VERSION ""

NS_ :

BS_:

BU_: APIM_CISM APIM ESPM DSP FCIMB RACM_RCIM HUD_ADV WCM TRM_ITRM ACM GWM _delete IPC GENERIC TSTR

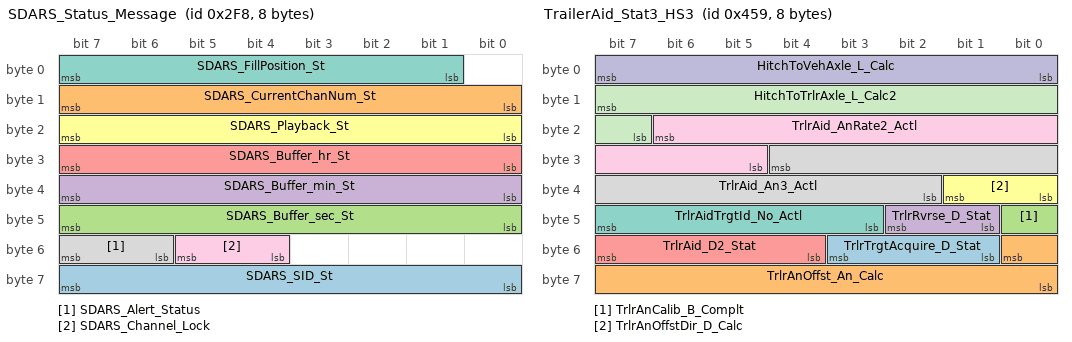
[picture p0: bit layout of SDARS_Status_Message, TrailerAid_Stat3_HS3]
BO_ 760 SDARS_Status_Message: 8 ACM
 SG_ SDARS_SID_St : 63|8@0+ (1,0) [0|255] "unitless"  APIM,RACM_RCIM
 SG_ SDARS_CurrentChanNum_St : 15|8@0+ (1,0) [0|255] "unitless"  APIM,RACM_RCIM,IPC
 SG_ SDARS_Buffer_sec_St : 47|8@0+ (1,0) [0|255] "unitless"  APIM,IPC
 SG_ SDARS_Buffer_min_St : 39|8@0+ (1,0) [0|255] "unitless"  APIM,IPC
 SG_ SDARS_Buffer_hr_St : 31|8@0+ (1,0) [0|255] "unitless"  APIM,IPC
 SG_ SDARS_Playback_St : 23|8@0+ (1,0) [0|255] "unitless"  APIM,IPC
 SG_ SDARS_FillPosition_St : 7|7@0+ (1,0) [0|127] "unitless"  APIM,IPC
 SG_ SDARS_Alert_Status : 55|2@0+ (1,0) [0|3] "SED"  APIM,IPC
 SG_ SDARS_Channel_Lock : 53|2@0+ (1,0) [0|3] "SED"  APIM,RACM_RCIM,IPC

BO_ 705 SDARS_RDISP_WORD_Tx: 8 ACM
 SG_ SDARS_RDISP_WORD_Tx : 7|64@0+ (1,0) [0|1.84467440737096E+019] "unitless"  APIM

BO_ 1113 TrailerAid_Stat3_HS3: 8 GWM
 SG_ TrlrTrgtAcquire_D_Stat : 51|3@0+ (1,0) [0|7] "SED" Vector__XXX
 SG_ TrlrAnOffst_An_Calc : 48|9@0+ (0.1,0) [0|51.1] "degrees"  APIM,APIM_CISM,IPC
 SG_ TrlrAnCalib_B_Complt : 40|1@0+ (1,0) [0|1] "SED"  APIM,APIM_CISM,IPC
 SG_ TrlrRvrse_D_Stat : 42|2@0+ (1,0) [0|3] "SED" Vector__XXX
 SG_ TrlrAid_D2_Stat : 55|4@0+ (1,0) [0|15] "SED" Vector__XXX
 SG_ TrlrAnOffstDir_D_Calc : 33|2@0+ (1,0) [0|3] "SED"  APIM,APIM_CISM,IPC
 SG_ TrlrAidTrgtId_No_Actl : 47|5@0+ (1,0) [0|31] "unitless"  APIM,APIM_CISM,IPC
 SG_ TrlrAid_An3_Actl : 28|11@0+ (0.125,-90) [-90|165.75] "degrees" Vector__XXX
 SG_ TrlrAid_AnRate2_Actl : 22|10@0+ (0.125,-50) [-50|77.75] "degrees/sec" Vector__XXX
 SG_ HitchToVehAxle_L_Calc : 7|8@0+ (0.0127,-0.508) [-0.508|2.7178] "meter" Vector__XXX
 SG_ HitchToTrlrAxle_L_Calc2 : 15|9@0+ (0.0254,0) [0|12.9794] "meter" Vector__XXX

BO_ 1144 MHT_EV_Wakeup_HS3: 8 GWM
 SG_ AwdLckMde_D_Stat : 59|3@0+ (1,0) [0|7] "SED" Vector__XXX
 SG_ BattTracCool_B_Actl : 60|1@0+ (1,0) [0|1] "SED" Vector__XXX
 SG_ BattChrgInhbt_D2_Rq : 63|3@0+ (1,0) [0|7] "SED" Vector__XXX
 SG_ FstChrgCmplt_T_Est : 41|10@0+ (1,0) [0|1023] "minute"  APIM,APIM_CISM,IPC
 SG_ BattChrgTrgtSoC_D_Rq : 35|3@0+ (1,0) [0|7] "Percent"  APIM_CISM,IPC
 SG_ CabnEvapSovFront_B_Rq : 38|1@0+ (1,0) [0|1] "SED" Vector__XXX
 SG_ HeatCoreSovRear_B_Rq : 36|1@0+ (1,0) [0|1] "SED" Vector__XXX
 SG_ BattChlrSov_B_Rq : 39|1@0+ (1,0) [0|1] "SED" Vector__XXX
 SG_ CabnEvapSovRear_B_Rq : 37|1@0+ (1,0) [0|1] "SED" Vector__XXX
 SG_ BrkAppl_D_RqPt : 25|2@0+ (1,0) [0|3] "SED" Vector__XXX
 SG_ BattClntVlvOvrrd_D_Rq : 31|2@0+ (1,0) [0|3] "SED" Vector__XXX
 SG_ BattTracChillerOn_B_Rq : 27|1@0+ (1,0) [0|1] "SED" Vector__XXX
 SG_ BattTracChiller_D_Stat : 29|2@0+ (1,0) [0|3] "SED" Vector__XXX
 SG_ HtrnDcdcDis_B_Rq : 26|1@0+ (1,0) [0|1] "SED" Vector__XXX
 SG_ HtrnCnnctPwr_B_Stat : 16|1@0+ (1,0) [0|1] "SED" Vector__XXX
 SG_ PtcHtr_D_Stat : 18|2@0+ (1,0) [0|3] "SED" Vector__XXX
 SG_ WakeAlarm0_B_Typ : 21|1@0+ (1,0) [0|1] "SED" Vector__XXX
 SG_ WakeAlarm0_T_Rq : 7|15@0+ (1,0) [0|32767] "minute" Vector__XXX
 SG_ HtrnClntFlw_D_Rq : 20|2@0+ (1,0) [0|3] "SED" Vector__XXX
 SG_ BattTracDrvSustn_B_Rq : 8|1@0+ (1,0) [0|1] "SED" Vector__XXX
 SG_ CabinDrvSustn_B_Rq : 23|1@0+ (1,0) [0|1] "SED" Vector__XXX
 SG_ ChrgNowEvnt_B_Stat : 22|1@0+ (1,0) [0|1] "SED" Vector__XXX
 SG_ PreCondBatt_B_Actl : 32|1@0+ (1,0) [0|1] "SED" Vector__XXX
 SG_ BattTracClntVlv_B_Rq : 47|1@0+ (1,0) [0|1] "SED" Vector__XXX
 SG_ ULoBattTrnsfrSustn_B_Rq : 43|1@0+ (1,0) [0|1] "SED" Vector__XXX
 SG_ ULoBattTransfer_D_Stat : 46|3@0+ (1,0) [0|7] "SED" Vector__XXX
 SG_ BattTracClimtDis_B_Stat : 42|1@0+ (1,0) [0|1] "SED" Vector__XXX

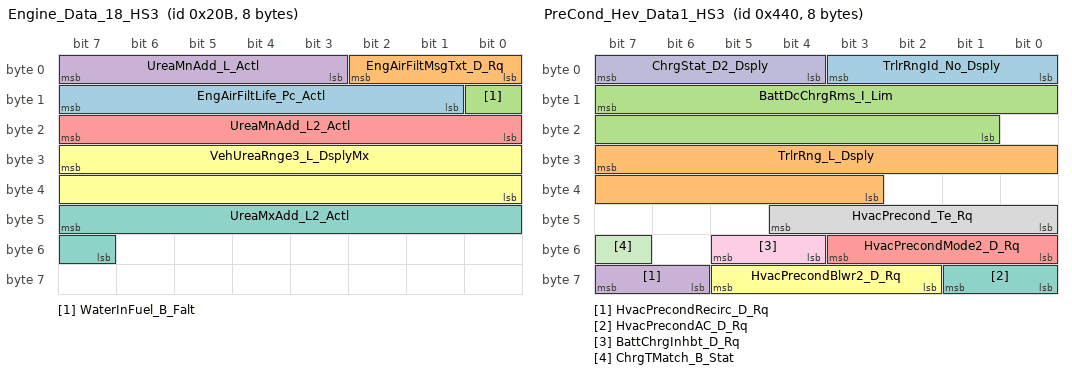
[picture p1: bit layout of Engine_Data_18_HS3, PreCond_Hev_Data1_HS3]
BO_ 523 Engine_Data_18_HS3: 8 GWM
 SG_ EngAirFiltLife_Pc_Actl : 15|7@0+ (1,0) [0|127] "percent"  IPC
 SG_ EngAirFiltMsgTxt_D_Rq : 2|3@0+ (1,0) [0|7] "SED"  IPC
 SG_ WaterInFuel_B_Falt : 8|1@0+ (1,0) [0|1] "SED"  APIM_CISM,IPC
 SG_ UreaMnAdd_L_Actl : 7|5@0+ (1,0) [0|31] "litre"  APIM_CISM,IPC
 SG_ UreaMnAdd_L2_Actl : 23|8@0+ (0.1,0) [0|25.4] "litre"  APIM_CISM,IPC
 SG_ VehUreaRnge3_L_DsplyMx : 31|16@0+ (1,0) [0|65535] "unitless"  APIM_CISM,IPC
 SG_ UreaMxAdd_L2_Actl : 47|9@0+ (0.1,0) [0|51] "litre"  APIM_CISM,IPC

BO_ 692 AUDIO_RDISP_WORD_Tx: 8 ACM
 SG_ AUDIO_RDISP_WORD_Tx : 7|64@0+ (1,0) [0|1.84467440737096E+019] "unitless"  APIM

BO_ 1837 TesterPhysicalResWCM: 8 WCM
 SG_ TesterPhysicalResWCM : 7|64@0+ (1,0) [0|1.84467E+019] "unitless"  TSTR

BO_ 942 ParkAid_Data2_HS3: 8 GWM
 SG_ ApaOffOptnSel_B_Avail : 51|1@0+ (1,0) [0|1] "SED"  APIM,APIM_CISM
 SG_ ApaSlotOption_B_Avail : 43|1@0+ (1,0) [0|1] "SED"  APIM,APIM_CISM
 SG_ ApaSlotAlrtSet_B_Stat : 44|1@0+ (1,0) [0|1] "SED"  APIM,APIM_CISM
 SG_ ApaSlotAlrt_B_Rq : 45|1@0+ (1,0) [0|1] "SED"  APIM,APIM_CISM
 SG_ ApaRmtFeatSel_B_Avail : 46|1@0+ (1,0) [0|1] "SED"  APIM,APIM_CISM
 SG_ ApaParkOutSel_B_Avail : 47|1@0+ (1,0) [0|1] "SED"  APIM,APIM_CISM
 SG_ ApaSys_D2_Stat : 35|4@0+ (1,0) [0|15] "SED"  APIM,APIM_CISM
 SG_ ApaSlotTrgt_D_Stat : 39|4@0+ (1,0) [0|15] "SED"  APIM,APIM_CISM
 SG_ ApaParkInSel_B_Avail : 24|1@0+ (1,0) [0|1] "SED"  APIM,APIM_CISM
 SG_ ApaMsgTxt_D2_Stat : 28|4@0+ (1,0) [0|15] "SED"  APIM,APIM_CISM
 SG_ ApaDynmcSlot_B_Stat : 29|1@0+ (1,0) [0|1] "SED"  APIM,APIM_CISM
 SG_ ApaDisplayMode_D_Stat : 31|2@0+ (1,0) [0|3] "SED"  APIM,APIM_CISM
 SG_ ApaControlMode_D_Stat : 16|1@0+ (1,0) [0|1] "SED"  APIM,APIM_CISM
 SG_ PrkBrkElRleas_B_RqApa : 50|1@0+ (1,0) [0|1] "SED" Vector__XXX
 SG_ PrkAidAcsyRear_D_Stat : 18|2@0+ (1,0) [0|3] "SED"  IPC
 SG_ PrkAidAcsyFront_D_Stat : 20|2@0+ (1,0) [0|3] "SED"  IPC
 SG_ ApaDrvRq2MsgTxt_D_Rq : 55|4@0+ (1,0) [0|15] "SED"  APIM,APIM_CISM
 SG_ ApaDrvRq1MsgTxt_D_Rq : 42|3@0+ (1,0) [0|7] "SED"  APIM,APIM_CISM
 SG_ PrkAidRdiusRight_L_Dsply : 15|8@0+ (1,0) [0|255] "unitless"  APIM,APIM_CISM
 SG_ PrkAidRdiusLeft_L_Dsply : 7|8@0+ (1,0) [0|255] "unitless"  APIM,APIM_CISM
 SG_ PrkAidDrvDir_D_Stat : 23|3@0+ (1,0) [0|7] "SED"  APIM,APIM_CISM

BO_ 1088 PreCond_Hev_Data1_HS3: 8 GWM
 SG_ TrlrRngId_No_Dsply : 3|4@0+ (1,0) [0|15] "unitless"  APIM,APIM_CISM
 SG_ TrlrRng_L_Dsply : 31|13@0+ (0.1,0) [0|818.9] "kilometer"  APIM,APIM_CISM
 SG_ BattDcChrgRms_I_Lim : 15|15@0+ (0.05,0) [0|1638.25] "ampere" Vector__XXX
 SG_ HvacPrecondRecirc_D_Rq : 63|2@0+ (1,0) [0|3] "SED"  GENERIC
 SG_ HvacPrecondMode2_D_Rq : 51|4@0+ (1,0) [0|15] "SED"  GENERIC
 SG_ HvacPrecondBlwr2_D_Rq : 61|4@0+ (1,0) [0|15] "SED"  GENERIC
 SG_ HvacPrecondAC_D_Rq : 57|2@0+ (1,0) [0|3] "SED"  GENERIC
 SG_ HvacPrecond_Te_Rq : 44|5@0+ (0.5,14.5) [14.5|30] "degC"  GENERIC
 SG_ BattChrgInhbt_D_Rq : 53|2@0+ (1,0) [0|3] "SED"  GENERIC
 SG_ ChrgStat_D2_Dsply : 7|4@0+ (1,0) [0|15] "SED"  APIM,APIM_CISM,IPC
 SG_ ChrgTMatch_B_Stat : 55|1@0+ (1,0) [0|1] "SED"  APIM_CISM,IPC

BO_ 706 SDARS_MC_WORD_Tx: 8 ACM
 SG_ SDARS_MC_WORD_Tx : 7|64@0+ (1,0) [0|1.84467440737096E+019] "unitless"  IPC

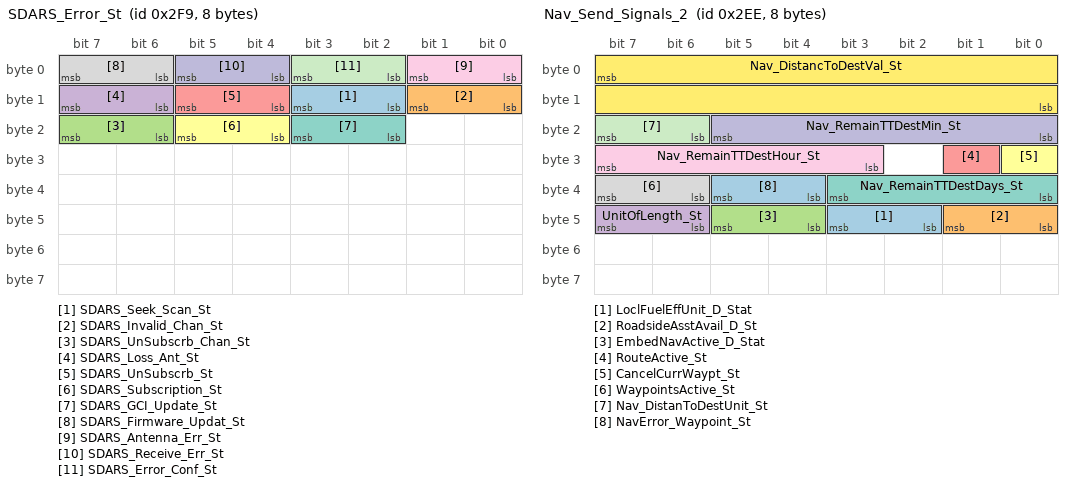
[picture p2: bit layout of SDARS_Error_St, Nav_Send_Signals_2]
BO_ 761 SDARS_Error_St: 8 ACM
 SG_ SDARS_Seek_Scan_St : 11|2@0+ (1,0) [0|3] "SED"  APIM,RACM_RCIM,IPC
 SG_ SDARS_Invalid_Chan_St : 9|2@0+ (1,0) [0|3] "SED"  APIM,RACM_RCIM,IPC
 SG_ SDARS_UnSubscrb_Chan_St : 23|2@0+ (1,0) [0|3] "SED"  APIM,RACM_RCIM,IPC
 SG_ SDARS_Loss_Ant_St : 15|2@0+ (1,0) [0|3] "SED"  APIM,RACM_RCIM,IPC
 SG_ SDARS_UnSubscrb_St : 13|2@0+ (1,0) [0|3] "SED"  APIM,RACM_RCIM,IPC
 SG_ SDARS_Subscription_St : 21|2@0+ (1,0) [0|3] "SED"  APIM,RACM_RCIM,IPC
 SG_ SDARS_GCI_Update_St : 19|2@0+ (1,0) [0|3] "SED"  APIM,RACM_RCIM,IPC
 SG_ SDARS_Firmware_Updat_St : 7|2@0+ (1,0) [0|3] "SED"  APIM,RACM_RCIM,IPC
 SG_ SDARS_Antenna_Err_St : 1|2@0+ (1,0) [0|3] "SED"  APIM,RACM_RCIM,IPC
 SG_ SDARS_Receive_Err_St : 5|2@0+ (1,0) [0|3] "SED"  APIM,RACM_RCIM,IPC
 SG_ SDARS_Error_Conf_St : 3|2@0+ (1,0) [0|3] "SED"  APIM,RACM_RCIM,IPC

BO_ 694 PHONE_MC_WORD_Tx: 8 APIM
 SG_ PHONE_MC_WORD_Tx : 7|64@0+ (1,0) [0|1.84467440737096E+019] "unitless"  IPC

BO_ 750 Nav_Send_Signals_2: 8 APIM
 SG_ LoclFuelEffUnit_D_Stat : 43|2@0+ (1,0) [0|3] "SED"  GWM,IPC
 SG_ RoadsideAsstAvail_D_St : 41|2@0+ (1,0) [0|3] "SED"  GWM,IPC
 SG_ EmbedNavActive_D_Stat : 45|2@0+ (1,0) [0|3] "SED"  GWM,IPC
 SG_ UnitOfLength_St : 47|2@0+ (1,0) [0|3] "SED"  GWM,IPC
 SG_ RouteActive_St : 25|1@0+ (1,0) [0|1] "SED"  GWM,HUD_ADV,IPC
 SG_ CancelCurrWaypt_St : 24|1@0+ (1,0) [0|1] "SED"  GWM,IPC
 SG_ Nav_RemainTTDestDays_St : 35|4@0+ (1,0) [0|14] "day"  GWM,HUD_ADV,IPC
 SG_ WaypointsActive_St : 39|2@0+ (1,0) [0|3] "SED"  GWM,IPC
 SG_ Nav_RemainTTDestHour_St : 31|5@0+ (1,0) [0|31] "hour"  GWM,HUD_ADV,IPC
 SG_ Nav_RemainTTDestMin_St : 21|6@0+ (1,0) [0|63] "minute"  GWM,HUD_ADV,IPC
 SG_ Nav_DistanToDestUnit_St : 23|2@0+ (1,0) [0|3] "SED"  GWM,HUD_ADV,IPC
 SG_ Nav_DistancToDestVal_St : 7|16@0+ (1,0) [0|65534] "unitless"  GWM,HUD_ADV,IPC
 SG_ NavError_Waypoint_St : 37|2@0+ (1,0) [0|3] "SED"  GWM,HUD_ADV,IPC

BO_ 704 NAV_MC_WORD_Tx: 8 APIM
 SG_ NAV_MC_WORD_Tx : 7|64@0+ (1,0) [0|1.84467440737096E+019] "unitless"  IPC

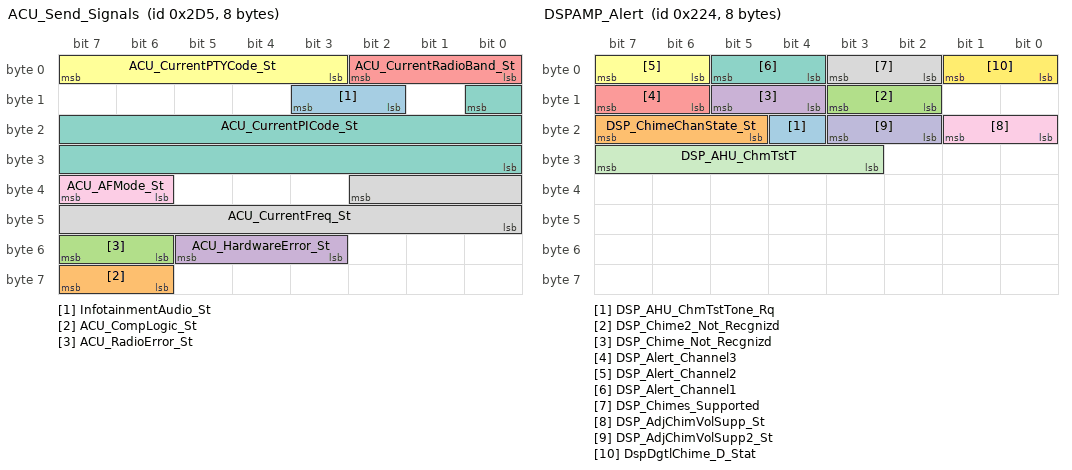
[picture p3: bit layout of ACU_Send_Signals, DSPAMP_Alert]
BO_ 725 ACU_Send_Signals: 8 APIM
 SG_ InfotainmentAudio_St : 11|2@0+ (1,0) [0|3] "SED"  APIM,DSP
 SG_ ACU_CompLogic_St : 63|2@0+ (1,0) [0|3] "SED"  GWM,GENERIC
 SG_ ACU_RadioError_St : 55|2@0+ (1,0) [0|3] "SED"  APIM,RACM_RCIM,GWM,IPC
 SG_ ACU_HardwareError_St : 53|3@0+ (1,0) [0|7] "SED"  APIM,RACM_RCIM,GWM,IPC
 SG_ ACU_CurrentRadioBand_St : 2|3@0+ (1,0) [0|7] "SED"  GWM,IPC
 SG_ ACU_CurrentPTYCode_St : 7|5@0+ (1,0) [0|31] "unitless"  APIM,RACM_RCIM,GWM,IPC
 SG_ ACU_CurrentPICode_St : 8|17@0+ (1,0) [0|65535] "unitless"  APIM,RACM_RCIM,GWM
 SG_ ACU_CurrentFreq_St : 34|11@0+ (1,0) [0|1557] "unitless"  APIM,DSP,RACM_RCIM,GWM,WCM,IPC
 SG_ ACU_AFMode_St : 39|2@0+ (1,0) [0|3] "SED"  APIM,GWM

BO_ 1049 APIMSDMsignals: 8 APIM
 SG_ DcacZone3PwBttn_B_Stat : 34|1@0+ (1,0) [0|1] "SED"  GWM
 SG_ DcacZone2PwBttn_B_Stat : 35|1@0+ (1,0) [0|1] "SED"  GWM
 SG_ DcacPwResetBtn2_B_Stat : 36|1@0+ (1,0) [0|1] "SED"  GWM
 SG_ DcacPwOffButtn2_B_Stat : 37|1@0+ (1,0) [0|1] "SED"  GWM
 SG_ DcacPwHiButtn2_B_Stat : 38|1@0+ (1,0) [0|1] "SED"  GWM
 SG_ DcacGfciTestBtn2_B_Stat : 39|1@0+ (1,0) [0|1] "SED"  GWM
 SG_ DcacAllZoneBttn_B_Stat : 16|1@0+ (1,0) [0|1] "SED"  GWM
 SG_ DcacChime_D_Rq : 18|2@0+ (1,0) [0|3] "SED"  GWM,IPC
 SG_ PersTurnSglView_D_RqMnu : 20|2@0+ (1,0) [0|3] "SED"  GWM
 SG_ TrailCtlSwtch_B_Stat4 : 21|1@0+ (1,0) [0|1] "SED"  GWM
 SG_ RearDiffLck_D_RqDrv3 : 9|2@0+ (1,0) [0|3] "SED"  GWM
 SG_ FrontDiffLck_D_RqDrv3 : 11|2@0+ (1,0) [0|3] "SED"  GWM
 SG_ CamraFrnt_B_RqMnu : 12|1@0+ (1,0) [0|1] "SED"  GWM
 SG_ TurnAsstSwtch_D_Stat : 14|2@0+ (1,0) [0|3] "SED"  GWM
 SG_ StabBarCnncButtn_D_Sta3 : 23|2@0+ (1,0) [0|3] "SED"  GWM
 SG_ TrlrRngId_No_RqReset : 27|4@0+ (1,0) [0|15] "unitless"  GWM
 SG_ TrlrId_No_ActlMnu : 31|4@0+ (1,0) [0|15] "unitless"  GWM
 SG_ SelDrvMdeTxtRst_B_Rq2 : 15|1@0+ (1,0) [0|1] "SED"  GWM
 SG_ SelDrvMdePage_B_Stat : 0|1@0+ (1,0) [0|1] "SED"  GWM
 SG_ SelDrvMdeCnfm_D_Stat2 : 2|2@0+ (1,0) [0|3] "SED"  GWM
 SG_ SelDrvMde_D_RqDrv : 7|5@0+ (1,0) [0|31] "SED"  GWM

BO_ 1014 WCM_Send_Signals: 8 WCM
 SG_ WrlssAcsyChrgr_D_Stat : 7|3@0+ (1,0) [0|7] "SED"  APIM,APIM_CISM
 SG_ WrlssAcsyChrg_Pc_Actl : 15|7@0+ (1,0) [0|125] "percent"  APIM,APIM_CISM

BO_ 548 DSPAMP_Alert: 8 DSP
 SG_ DSP_AHU_ChmTstTone_Rq : 20|1@0+ (1,0) [0|1] "SED"  APIM_CISM,ACM
 SG_ DSP_ChimeChanState_St : 23|3@0+ (1,0) [0|7] "SED"  APIM_CISM,ACM
 SG_ DSP_Chime2_Not_Recgnizd : 11|2@0+ (1,0) [0|3] "SED"  APIM_CISM,IPC
 SG_ DSP_Chime_Not_Recgnizd : 13|2@0+ (1,0) [0|3] "SED"  APIM_CISM,IPC
 SG_ DSP_Alert_Channel3 : 15|2@0+ (1,0) [0|3] "SED"  APIM,APIM_CISM,WCM,IPC,RACM_RCIM
 SG_ DSP_Alert_Channel2 : 7|2@0+ (1,0) [0|3] "SED"  APIM_CISM,IPC,ACM
 SG_ DSP_Alert_Channel1 : 5|2@0+ (1,0) [0|3] "SED"  APIM_CISM,IPC,ACM
 SG_ DSP_Chimes_Supported : 3|2@0+ (1,0) [0|3] "SED"  APIM,APIM_CISM,IPC,ACM
 SG_ DSP_AdjChimVolSupp_St : 17|2@0+ (1,0) [0|3] "SED"  APIM_CISM,IPC,ACM
 SG_ DSP_AdjChimVolSupp2_St : 19|2@0+ (1,0) [0|3] "SED"  APIM_CISM,IPC,ACM
 SG_ DSP_AHU_ChmTstT : 31|5@0+ (1,0) [0|31] "SED"  APIM_CISM,ACM
 SG_ DspDgtlChime_D_Stat : 1|2@0+ (1,0) [0|3] "SED"  APIM_CISM,ACM

BO_ 404 Dsp_Response_Signals: 8 APIM
 SG_ Dsp_LangUpdate_Rsp : 7|2@0+ (1,0) [0|3] "SED"  GWM,IPC

BO_ 689 AUDIO_MC_WORD_Tx: 8 ACM
 SG_ AUDIO_MC_WORD_Tx : 7|64@0+ (1,0) [0|1.84467440737096E+019] "unitless"  IPC

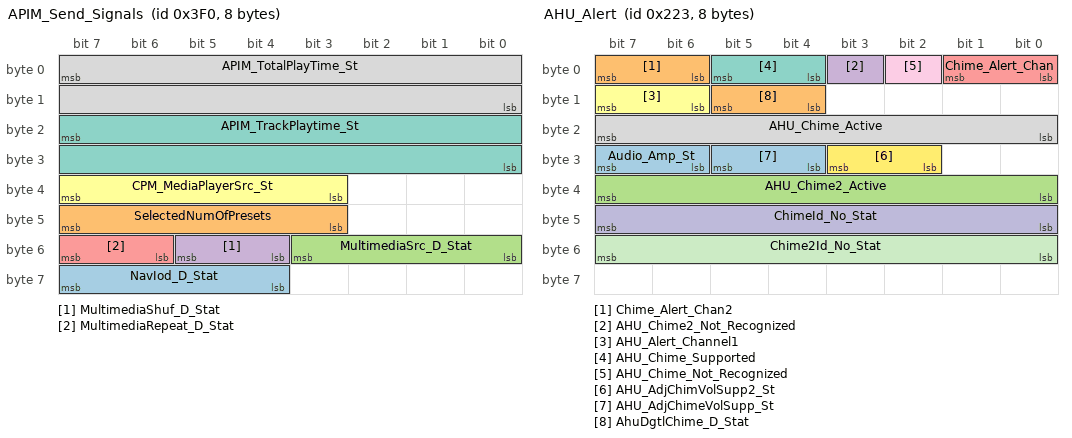
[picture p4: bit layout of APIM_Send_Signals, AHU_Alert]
BO_ 1008 APIM_Send_Signals: 8 APIM
 SG_ NavIod_D_Stat : 63|4@0+ (1,0) [0|15] "SED"  IPC
 SG_ SelectedNumOfPresets : 47|5@0+ (1,0) [0|31] "SED"  RACM_RCIM,IPC,ACM,GWM
 SG_ MultimediaSrc_D_Stat : 51|4@0+ (1,0) [0|15] "SED"  RACM_RCIM,GWM
 SG_ MultimediaShuf_D_Stat : 53|2@0+ (1,0) [0|2] "SED"  RACM_RCIM,GWM
 SG_ MultimediaRepeat_D_Stat : 55|2@0+ (1,0) [0|3] "SED"  RACM_RCIM,GWM
 SG_ CPM_MediaPlayerSrc_St : 39|5@0+ (1,0) [0|31] "SED"  GENERIC,GWM
 SG_ APIM_TrackPlaytime_St : 23|16@0+ (1,-100) [-100|65434] "second"  RACM_RCIM,IPC,GWM
 SG_ APIM_TotalPlayTime_St : 7|16@0+ (1,-100) [-100|65434] "second"  RACM_RCIM,IPC,GWM

BO_ 547 AHU_Alert: 8 APIM
 SG_ Audio_Amp_St : 31|2@0+ (1,0) [0|3] "SED"  GWM
 SG_ Chime_Alert_Chan2 : 7|2@0+ (1,0) [0|3] "SED"  GWM,DSP,IPC
 SG_ AHU_Chime2_Active : 39|8@0+ (1,0) [0|255] "SED"  GWM,DSP,IPC
 SG_ AHU_Chime2_Not_Recognized : 3|1@0+ (1,0) [0|1] "SED"  GWM,IPC
 SG_ Chime_Alert_Chan : 1|2@0+ (1,0) [0|3] "SED"  GWM,DSP,IPC
 SG_ AHU_Alert_Channel1 : 15|2@0+ (1,0) [0|3] "SED"  APIM,IPC,WCM,RACM_RCIM,GWM
 SG_ AHU_Chime_Supported : 5|2@0+ (1,0) [0|3] "SED"  APIM,GWM,IPC
 SG_ AHU_Chime_Active : 23|8@0+ (1,0) [0|255] "SED"  GWM,DSP,IPC
 SG_ AHU_Chime_Not_Recognized : 2|1@0+ (1,0) [0|1] "SED"  GWM,IPC
 SG_ ChimeId_No_Stat : 47|8@0+ (1,0) [0|255] "SED"  IPC
 SG_ Chime2Id_No_Stat : 55|8@0+ (1,0) [0|255] "SED"  IPC
 SG_ AHU_AdjChimVolSupp2_St : 27|2@0+ (1,0) [0|3] "SED"  IPC
 SG_ AHU_AdjChimeVolSupp_St : 29|2@0+ (1,0) [0|3] "SED"  IPC
 SG_ AhuDgtlChime_D_Stat : 13|2@0+ (1,0) [0|3] "SED"  DSP

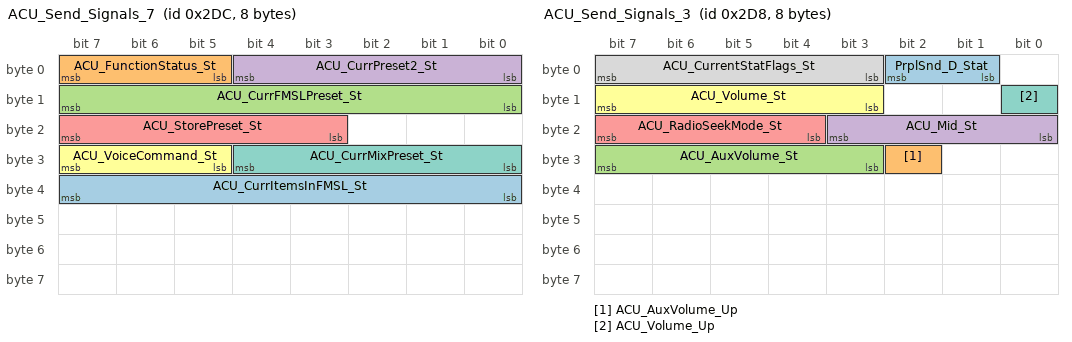
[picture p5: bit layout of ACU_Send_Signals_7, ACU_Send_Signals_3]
BO_ 732 ACU_Send_Signals_7: 8 APIM
 SG_ ACU_CurrItemsInFMSL_St : 39|8@0+ (1,0) [0|255] "unitless"  APIM
 SG_ ACU_FunctionStatus_St : 7|3@0+ (1,0) [0|7] "SED"  APIM,RACM_RCIM,IPC
 SG_ ACU_CurrFMSLPreset_St : 15|8@0+ (1,0) [0|255] "unitless"  APIM,GWM
 SG_ ACU_CurrPreset2_St : 4|5@0+ (1,0) [0|31] "unitless"  APIM,RACM_RCIM,GWM,IPC
 SG_ ACU_StorePreset_St : 23|5@0+ (1,0) [0|31] "SED"  APIM,IPC,GWM
 SG_ ACU_VoiceCommand_St : 31|3@0+ (1,0) [0|7] "SED" Vector__XXX
 SG_ ACU_CurrMixPreset_St : 28|5@0+ (1,0) [0|31] "unitless"  APIM,IPC,RACM_RCIM,GWM

BO_ 728 ACU_Send_Signals_3: 8 APIM
 SG_ PrplSnd_D_Stat : 2|2@0+ (1,0) [0|3] "SED"  APIM
 SG_ ACU_AuxVolume_Up : 26|1@0+ (1,0) [0|1] "SED"  IPC
 SG_ ACU_AuxVolume_St : 31|5@0+ (1,0) [0|31] "unitless"  IPC
 SG_ ACU_Mid_St : 19|4@0+ (1,-7) [-7|8] "unitless"  APIM,GWM
 SG_ ACU_RadioSeekMode_St : 23|4@0+ (1,0) [0|15] "SED"  APIM,IPC,GWM
 SG_ ACU_Volume_St : 15|5@0+ (1,0) [0|30] "unitless"  APIM,WCM,HUD_ADV,RACM_RCIM,GWM,IPC
 SG_ ACU_Volume_Up : 8|1@0+ (1,0) [0|1] "SED"  APIM,RACM_RCIM,GWM,IPC
 SG_ ACU_CurrentStatFlags_St : 7|5@0+ (1,0) [0|31] "unitless"  APIM,RACM_RCIM,GWM,IPC

BO_ 489 ACU_Send_Signals_1: 8 APIM
 SG_ ACU_CurrentPSName_St : 7|64@0+ (1,0) [0|1.8446744074E+019] "unitless"  APIM,RACM_RCIM,GWM,IPC

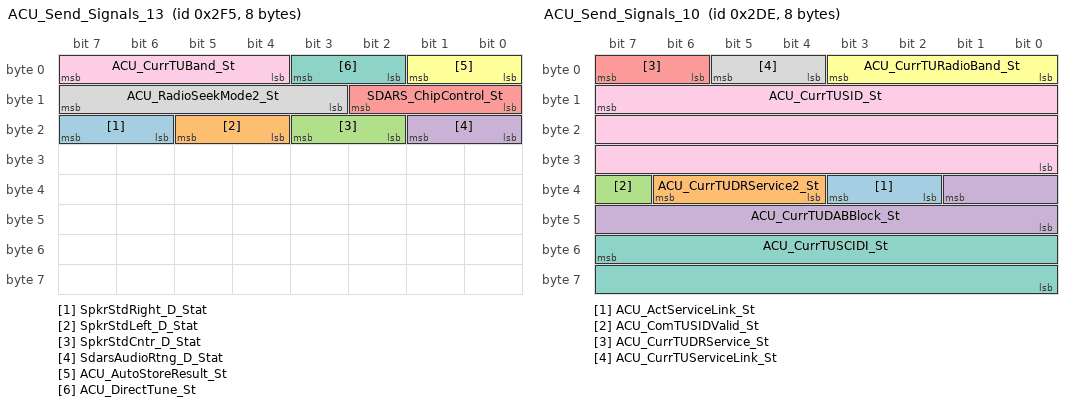
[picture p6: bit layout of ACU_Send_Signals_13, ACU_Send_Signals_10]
BO_ 757 ACU_Send_Signals_13: 8 ACM
 SG_ SpkrStdRight_D_Stat : 23|2@0+ (1,0) [0|3] "SED"  DSP,GWM
 SG_ SpkrStdLeft_D_Stat : 21|2@0+ (1,0) [0|3] "SED"  DSP,GWM
 SG_ SpkrStdCntr_D_Stat : 19|2@0+ (1,0) [0|3] "SED"  DSP,GWM
 SG_ SdarsAudioRtng_D_Stat : 17|2@0+ (1,0) [0|3] "SED"  APIM,APIM_CISM
 SG_ SDARS_ChipControl_St : 10|3@0+ (1,0) [0|7] "SED"  APIM
 SG_ ACU_AutoStoreResult_St : 1|2@0+ (1,0) [0|3] "SED"  APIM,RACM_RCIM,GWM,IPC
 SG_ ACU_DirectTune_St : 3|2@0+ (1,0) [0|3] "SED"  APIM,GWM,IPC
 SG_ ACU_RadioSeekMode2_St : 15|5@0+ (1,0) [0|31] "SED"  APIM,RACM_RCIM,GWM,WCM,IPC
 SG_ ACU_CurrTUBand_St : 7|4@0+ (1,0) [0|15] "SED"  APIM,DSP,RACM_RCIM,GWM,WCM,IPC

BO_ 734 ACU_Send_Signals_10: 8 ACM
 SG_ ACU_ActServiceLink_St : 35|2@0+ (1,0) [0|3] "SED"  APIM,IPC,RACM_RCIM
 SG_ ACU_CurrTUDRService2_St : 38|3@0+ (1,0) [0|7] "SED"  APIM,RACM_RCIM,GWM,IPC
 SG_ ACU_ComTUSIDValid_St : 39|1@0+ (1,0) [0|1] "SED"  APIM,GWM
 SG_ ACU_CurrTUDABBlock_St : 33|10@0+ (1,0) [0|1023] "SED"  APIM,RACM_RCIM,GWM,IPC
 SG_ ACU_CurrTUDRService_St : 7|2@0+ (1,0) [0|3] "SED"  APIM,GWM
 SG_ ACU_CurrTURadioBand_St : 3|4@0+ (1,0) [0|15] "SED" Vector__XXX
 SG_ ACU_CurrTUSCIDI_St : 55|16@0+ (1,0) [0|65535] "unitless"  APIM,RACM_RCIM,GWM
 SG_ ACU_CurrTUServiceLink_St : 5|2@0+ (1,0) [0|3] "SED"  APIM,RACM_RCIM,GWM
 SG_ ACU_CurrTUSID_St : 15|24@0+ (1,0) [0|16777215] "unitless"  APIM,RACM_RCIM,GWM

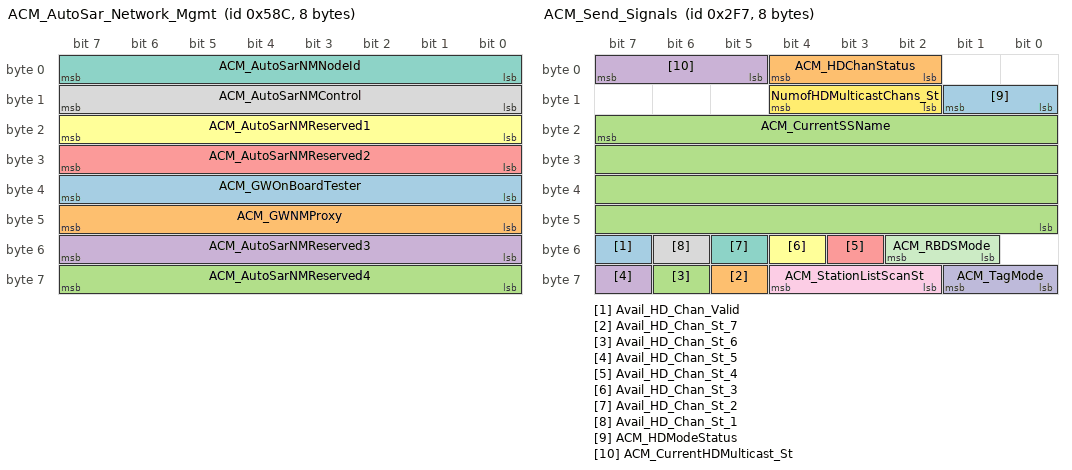
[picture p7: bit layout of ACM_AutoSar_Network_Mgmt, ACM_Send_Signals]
BO_ 1420 ACM_AutoSar_Network_Mgmt: 8 ACM
 SG_ ACM_GWOnBoardTester : 39|8@0+ (1,0) [0|255] "unitless"  IPC,GENERIC,GWM
 SG_ ACM_GWNMProxy : 47|8@0+ (1,0) [0|255] "unitless"  IPC,GENERIC,GWM
 SG_ ACM_AutoSarNMReserved4 : 63|8@0+ (1,0) [0|255] "unitless"  IPC,GENERIC,GWM
 SG_ ACM_AutoSarNMReserved3 : 55|8@0+ (1,0) [0|255] "unitless"  IPC,GENERIC,GWM
 SG_ ACM_AutoSarNMReserved2 : 31|8@0+ (1,0) [0|255] "unitless"  IPC,GENERIC,GWM
 SG_ ACM_AutoSarNMReserved1 : 23|8@0+ (1,0) [0|255] "unitless"  IPC,GENERIC,GWM
 SG_ ACM_AutoSarNMNodeId : 7|8@0+ (1,0) [0|255] "unitless"  IPC,GENERIC,GWM
 SG_ ACM_AutoSarNMControl : 15|8@0+ (1,0) [0|255] "unitless"  IPC,GENERIC,GWM

BO_ 759 ACM_Send_Signals: 8 ACM
 SG_ Avail_HD_Chan_Valid : 55|1@0+ (1,0) [0|1] "SED"  APIM,RACM_RCIM
 SG_ Avail_HD_Chan_St_7 : 61|1@0+ (1,0) [0|1] "SED"  APIM,RACM_RCIM
 SG_ Avail_HD_Chan_St_6 : 62|1@0+ (1,0) [0|1] "SED"  APIM,RACM_RCIM
 SG_ Avail_HD_Chan_St_5 : 63|1@0+ (1,0) [0|1] "SED"  APIM,RACM_RCIM
 SG_ Avail_HD_Chan_St_4 : 51|1@0+ (1,0) [0|1] "SED"  APIM,RACM_RCIM
 SG_ Avail_HD_Chan_St_3 : 52|1@0+ (1,0) [0|1] "SED"  APIM,RACM_RCIM
 SG_ Avail_HD_Chan_St_2 : 53|1@0+ (1,0) [0|1] "SED"  APIM,RACM_RCIM
 SG_ Avail_HD_Chan_St_1 : 54|1@0+ (1,0) [0|1] "SED"  APIM,RACM_RCIM
 SG_ ACM_StationListScanSt : 60|3@0+ (1,0) [0|7] "SED"  APIM,IPC
 SG_ ACM_TagMode : 57|2@0+ (1,0) [0|3] "SED"  APIM,IPC
 SG_ ACM_RBDSMode : 50|2@0+ (1,0) [0|3] "SED"  APIM,RACM_RCIM,IPC
 SG_ NumofHDMulticastChans_St : 12|3@0+ (1,0) [0|7] "SED"  APIM,RACM_RCIM,IPC
 SG_ ACM_HDModeStatus : 9|2@0+ (1,0) [0|3] "SED"  APIM,RACM_RCIM,IPC
 SG_ ACM_HDChanStatus : 4|3@0+ (1,0) [0|7] "SED"  APIM,DSP,RACM_RCIM,IPC
 SG_ ACM_CurrentSSName : 23|32@0+ (1,0) [0|4294967295] "unitless"  APIM,RACM_RCIM,IPC
 SG_ ACM_CurrentHDMulticast_St : 7|3@0+ (1,0) [0|7] "SED"  APIM,RACM_RCIM,IPC

BO_ 1960 TesterPhysicalResFCIMB: 8 FCIMB
 SG_ TesterPhysicalResFCIMB : 7|64@0+ (1,0) [0|1.84467E+019] "unitless"  TSTR

BO_ 1952 TesterPhysicalReqFCIMB: 8 TSTR
 SG_ TesterPhysicalReqFCIMB : 7|64@0+ (1,0) [0|1.84467E+019] "unitless"  FCIMB

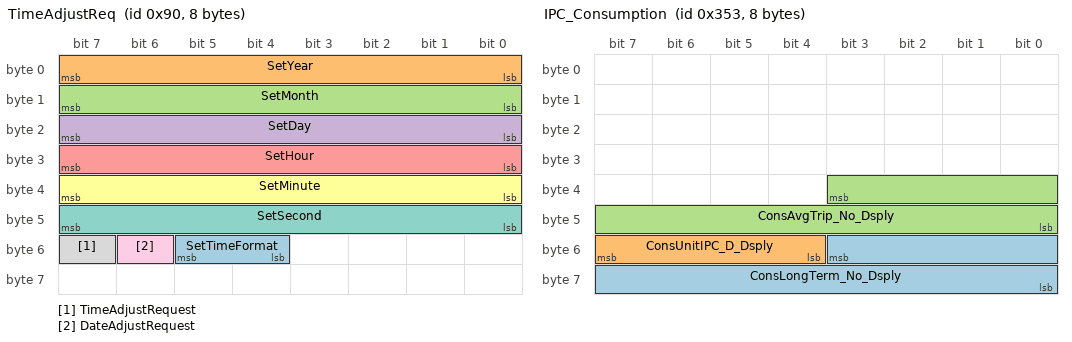
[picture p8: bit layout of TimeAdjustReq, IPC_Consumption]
BO_ 144 TimeAdjustReq: 8 APIM
 SG_ SetTimeFormat : 53|2@0+ (1,0) [0|3] "unitless"  IPC
 SG_ SetYear : 7|8@0+ (1,2000) [2000|2254] "year"  IPC,GENERIC
 SG_ SetMonth : 15|8@0+ (1,0) [0|12] "month"  IPC,GENERIC
 SG_ SetDay : 23|8@0+ (1,0) [0|31] "day"  IPC,GENERIC
 SG_ SetHour : 31|8@0+ (1,0) [0|23] "hour"  IPC,GENERIC
 SG_ SetMinute : 39|8@0+ (1,0) [0|59] "minute"  IPC,GENERIC
 SG_ SetSecond : 47|8@0+ (1,0) [0|59] "second"  IPC,GENERIC
 SG_ TimeAdjustRequest : 55|1@0+ (1,0) [0|1] "SED"  IPC,GENERIC
 SG_ DateAdjustRequest : 54|1@0+ (1,0) [0|1] "SED"  IPC,GENERIC

BO_ 851 IPC_Consumption: 8 IPC
 SG_ ConsLongTerm_No_Dsply : 51|12@0+ (1,0) [0|4093] "%"  GWM
 SG_ ConsUnitIPC_D_Dsply : 55|4@0+ (1,0) [0|15] "SED"  APIM,APIM_CISM,GWM
 SG_ ConsAvgTrip_No_Dsply : 35|12@0+ (1,0) [0|4093] "%"  GWM

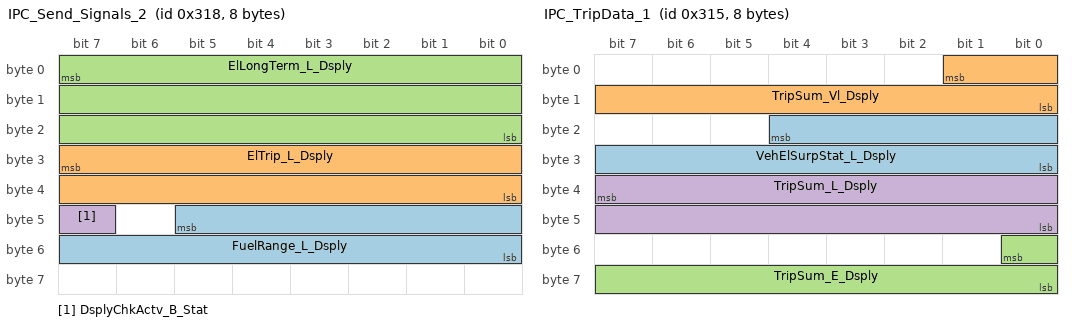
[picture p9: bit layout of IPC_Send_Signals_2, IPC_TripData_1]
BO_ 792 IPC_Send_Signals_2: 8 IPC
 SG_ FuelRange_L_Dsply : 45|14@0+ (0.1,0) [0|1638.3] "km"  APIM,APIM_CISM,HUD_ADV,GWM,ACM
 SG_ ElTrip_L_Dsply : 31|16@0+ (0.1,0) [0|6553.3] "unitless"  GWM
 SG_ ElLongTerm_L_Dsply : 7|24@0+ (0.1,0) [0|1677721.3] "unitless"  GWM
 SG_ DsplyChkActv_B_Stat : 47|1@0+ (1,0) [0|1] "SED"  HUD_ADV,GWM

BO_ 789 IPC_TripData_1: 8 IPC
 SG_ VehElSurpStat_L_Dsply : 20|13@0+ (0.1,-409.4) [-409.4|409.5] "Km"  GWM
 SG_ TripSum_Vl_Dsply : 1|10@0+ (0.1,0) [0|102.3] "Liters"  GWM
 SG_ TripSum_E_Dsply : 48|9@0+ (0.1,0) [0|50.9] "kw*hrs"  GWM
 SG_ TripSum_L_Dsply : 39|16@0+ (0.1,0) [0|6553.3] "Km"  GWM

BO_ 697 AUDIO_MC_WORD_Rx: 8 IPC
 SG_ AUDIO_MC_WORD_Rx : 7|64@0+ (1,0) [0|1.84467440737096E+019] "unitless"  APIM_CISM,ACM

BO_ 700 AUDIO_RDISP_WORD_Rx: 8 APIM
 SG_ AUDIO_RDISP_WORD_Rx : 7|64@0+ (1,0) [0|1.84467440737096E+019] "unitless"  ACM

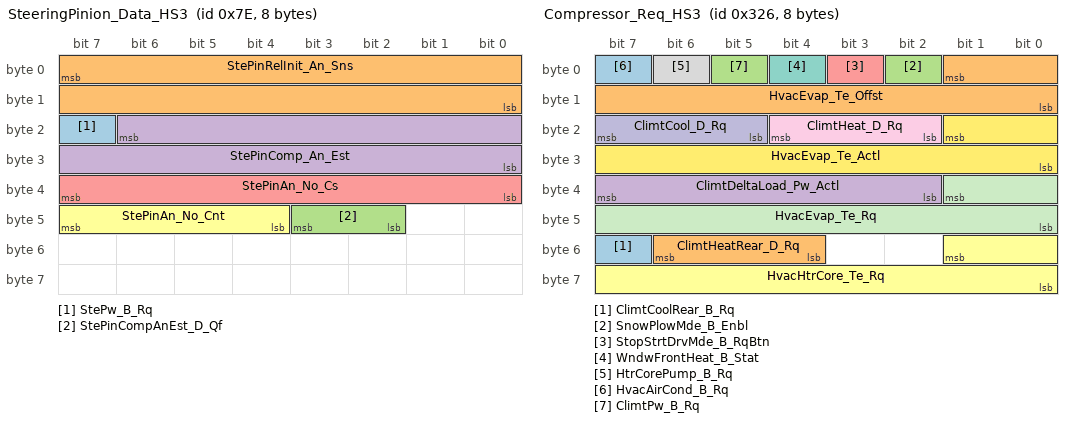
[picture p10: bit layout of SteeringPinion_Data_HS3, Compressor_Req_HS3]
BO_ 126 SteeringPinion_Data_HS3: 8 GWM
 SG_ StePw_B_Rq : 23|1@0+ (1,0) [0|1] "SED" Vector__XXX
 SG_ StePinRelInit_An_Sns : 7|16@0+ (0.1,-3200) [-3200|3353.3] "degrees" Vector__XXX
 SG_ StePinCompAnEst_D_Qf : 43|2@0+ (1,0) [0|3] "SED"  APIM,APIM_CISM,IPC
 SG_ StePinComp_An_Est : 22|15@0+ (0.1,-1600) [-1600|1676.7] "degrees"  APIM,APIM_CISM,IPC
 SG_ StePinAn_No_Cs : 39|8@0+ (1,0) [0|255] "unitless" Vector__XXX
 SG_ StePinAn_No_Cnt : 47|4@0+ (1,0) [0|15] "unitless" Vector__XXX

BO_ 806 Compressor_Req_HS3: 8 GWM
 SG_ ClimtCoolRear_B_Rq : 55|1@0+ (1,0) [0|1] "SED" Vector__XXX
 SG_ ClimtHeatRear_D_Rq : 54|3@0+ (1,0) [0|7] "SED" Vector__XXX
 SG_ SnowPlowMde_B_Enbl : 2|1@0+ (1,0) [0|1] "SED"  APIM,APIM_CISM,IPC
 SG_ ClimtDeltaLoad_Pw_Actl : 39|6@0+ (50,-1600) [-1600|1450] "watts" Vector__XXX
 SG_ StopStrtDrvMde_B_RqBtn : 3|1@0+ (1,0) [0|1] "SED" Vector__XXX
 SG_ HvacHtrCore_Te_Rq : 49|10@0+ (0.25,-50) [-50|205.75] "degC" Vector__XXX
 SG_ WndwFrontHeat_B_Stat : 4|1@0+ (1,0) [0|1] "SED" Vector__XXX
 SG_ HtrCorePump_B_Rq : 6|1@0+ (1,0) [0|1] "SED" Vector__XXX
 SG_ ClimtHeat_D_Rq : 20|3@0+ (1,0) [0|7] "SED" Vector__XXX
 SG_ ClimtCool_D_Rq : 23|3@0+ (1,0) [0|7] "SED" Vector__XXX
 SG_ HvacEvap_Te_Rq : 33|10@0+ (0.125,-50) [-50|77.875] "degC" Vector__XXX
 SG_ HvacEvap_Te_Actl : 17|10@0+ (0.125,-50) [-50|77.75] "degC" Vector__XXX
 SG_ HvacAirCond_B_Rq : 7|1@0+ (1,0) [0|1] "SED" Vector__XXX
 SG_ HvacEvap_Te_Offst : 1|10@0+ (0.125,-50) [-50|77.875] "degC" Vector__XXX
 SG_ ClimtPw_B_Rq : 5|1@0+ (1,0) [0|1] "SED" Vector__XXX

BO_ 676 MC_RDISP_WORD_Tx: 8 IPC
 SG_ MC_RDISP_WORD_Tx : 7|64@0+ (1,0) [0|1.84467440737096E+019] "unitless"  APIM,APIM_CISM

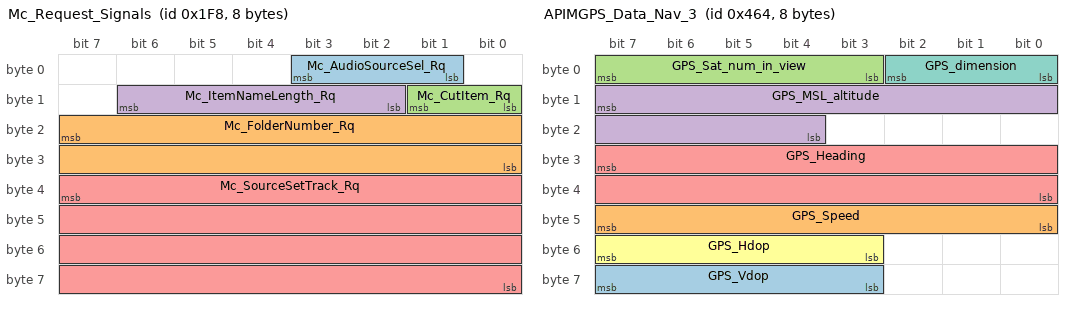
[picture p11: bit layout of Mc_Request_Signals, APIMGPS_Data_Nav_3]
BO_ 504 Mc_Request_Signals: 8 IPC
 SG_ Mc_AudioSourceSel_Rq : 3|3@0+ (1,0) [0|7] "SED"  APIM_CISM,GWM,ACM
 SG_ Mc_FolderNumber_Rq : 23|16@0+ (1,0) [0|65535] "unitless"  APIM_CISM,GWM,ACM
 SG_ Mc_CutItem_Rq : 9|2@0+ (1,0) [0|3] "SED"  APIM_CISM,GWM,ACM
 SG_ Mc_ItemNameLength_Rq : 14|5@0+ (1,0) [0|20] "SED"  APIM_CISM,GWM,ACM
 SG_ Mc_SourceSetTrack_Rq : 39|32@0+ (1,0) [0|4294967295] "unitless"  APIM_CISM,GWM,ACM

BO_ 410 Mc_Send_Signals_3: 8 IPC
 SG_ MyKey_e911Override_St : 39|2@0+ (1,0) [0|3] "SED"  APIM,APIM_CISM,GWM
 SG_ DoNotDisturbOveride_St : 26|2@0+ (1,0) [0|3] "SED"  APIM,APIM_CISM,GWM

BO_ 1124 APIMGPS_Data_Nav_3: 8 APIM
 SG_ GPS_Vdop : 63|5@0+ (0.2,0) [0|5.8] "unitless"  GWM
 SG_ GPS_Speed : 47|8@0+ (1,0) [0|253] "MPH"  GWM
 SG_ GPS_Sat_num_in_view : 7|5@0+ (1,0) [0|29] "unitless"  GWM
 SG_ GPS_MSL_altitude : 15|12@0+ (10,-20460) [-20460|20470] "feet"  GWM
 SG_ GPS_Heading : 31|16@0+ (0.01,0) [0|655.33] "degrees"  GWM
 SG_ GPS_Hdop : 55|5@0+ (0.2,0) [0|5.8] "unitless"  GWM
 SG_ GPS_dimension : 2|3@0+ (1,0) [0|7] "SED"  GWM

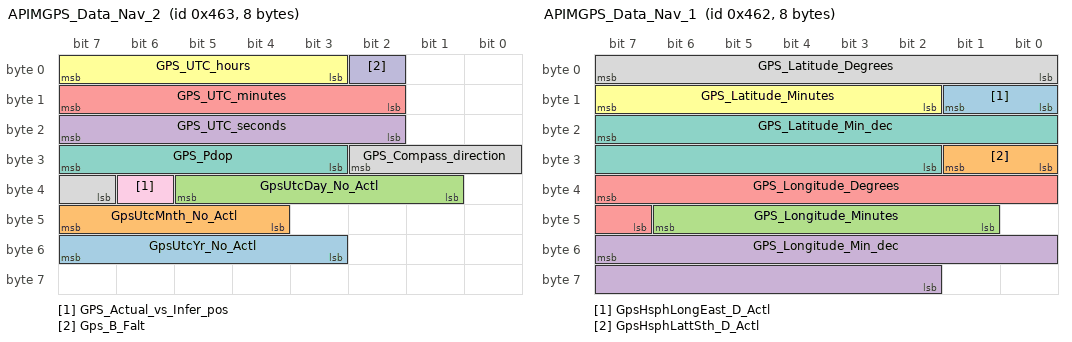
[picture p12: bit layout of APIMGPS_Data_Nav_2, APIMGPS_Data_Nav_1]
BO_ 1123 APIMGPS_Data_Nav_2: 8 APIM
 SG_ GpsUtcYr_No_Actl : 55|5@0+ (1,2010) [2010|2040] "Year"  GWM
 SG_ GpsUtcMnth_No_Actl : 47|4@0+ (1,1) [1|15] "Month"  GWM
 SG_ GpsUtcDay_No_Actl : 37|5@0+ (1,1) [1|32] "day"  GWM
 SG_ GPS_UTC_seconds : 23|6@0+ (1,0) [0|59] "seconds"  GWM
 SG_ GPS_UTC_minutes : 15|6@0+ (1,0) [0|59] "minute"  GWM
 SG_ GPS_UTC_hours : 7|5@0+ (1,0) [0|23] "Hours"  GWM
 SG_ GPS_Pdop : 31|5@0+ (0.2,0) [0|5.8] "unitless"  GWM
 SG_ GPS_Compass_direction : 26|4@0+ (1,0) [0|15] "SED"  HUD_ADV,GWM,IPC
 SG_ GPS_Actual_vs_Infer_pos : 38|1@0+ (1,0) [0|1] "SED"  GWM
 SG_ Gps_B_Falt : 2|1@0+ (1,0) [0|1] "SED"  GWM

BO_ 1122 APIMGPS_Data_Nav_1: 8 APIM
 SG_ GpsHsphLongEast_D_Actl : 9|2@0+ (1,0) [0|3] "SED"  GWM
 SG_ GpsHsphLattSth_D_Actl : 25|2@0+ (1,0) [0|3] "SED"  GWM
 SG_ GPS_Longitude_Minutes : 46|6@0+ (1,0) [0|61] "minute"  GWM
 SG_ GPS_Longitude_Min_dec : 55|14@0+ (0.0001,0) [0|1.6381] "minute"  GWM
 SG_ GPS_Longitude_Degrees : 39|9@0+ (1,-179) [-179|330] "degrees"  GWM
 SG_ GPS_Latitude_Minutes : 15|6@0+ (1,0) [0|61] "minute"  GWM
 SG_ GPS_Latitude_Min_dec : 23|14@0+ (0.0001,0) [0|1.6381] "minute"  GWM
 SG_ GPS_Latitude_Degrees : 7|8@0+ (1,-89) [-89|164] "degrees"  GWM

BO_ 1050 Climate_Control_Data_HS3: 8 GWM
 SG_ HtrCoreRearSov_D_Stat : 34|3@0+ (1,0) [0|7] "SED" Vector__XXX
 SG_ CamraRearBttn_D_Stat : 35|1@0+ (1,0) [0|1] "SED"  APIM,APIM_CISM
 SG_ TrailCtlSwtch_B_Stat : 16|1@0+ (1,0) [0|1] "SED" Vector__XXX
 SG_ CamraFrntBttn_D_Stat : 8|1@0+ (1,0) [0|1] "SED" Vector__XXX
 SG_ AutoHoldSwtch_D_Stat : 20|2@0+ (1,0) [0|3] "SED" Vector__XXX
 SG_ GlvBoxRleas_No_Actl : 23|3@0+ (1,0) [0|7] "unitless" Vector__XXX
 SG_ EcoInhbt_B_RqHvac : 17|1@0+ (1,0) [0|1] "SED" Vector__XXX
 SG_ LpdbPtc3_B_Rq : 36|1@0+ (1,0) [0|1] "SED" Vector__XXX
 SG_ LpdbPtc2_B_Rq : 37|1@0+ (1,0) [0|1] "SED" Vector__XXX
 SG_ LpdbPtc1_B_Rq : 38|1@0+ (1,0) [0|1] "SED" Vector__XXX
 SG_ LpdbHeatWiprPrk_B_Rq : 39|1@0+ (1,0) [0|1] "SED" Vector__XXX
 SG_ LpdbDfrstRearOn_B_Rq : 24|1@0+ (1,0) [0|1] "SED" Vector__XXX
 SG_ LpdbDfrstFrOn_B_Rq : 25|1@0+ (1,0) [0|1] "SED" Vector__XXX
 SG_ LpdbDfrstFlOn_B_Rq : 26|1@0+ (1,0) [0|1] "SED" Vector__XXX
 SG_ LpdbAuxBlwr_B_Rq : 27|1@0+ (1,0) [0|1] "SED" Vector__XXX
 SG_ PrkAidSwtch_No_Cnt : 31|4@0+ (1,0) [0|15] "unitless" Vector__XXX
 SG_ PrkAidSwtch_D_RqDrv : 18|1@0+ (1,0) [0|1] "SED" Vector__XXX
 SG_ SteWhlHeat_D_Rq : 13|4@0+ (1,0) [0|15] "SED" Vector__XXX
 SG_ MirrorHeatOn_B_Rq : 14|1@0+ (1,0) [0|1] "SED" Vector__XXX
 SG_ Remote_Start_QuietMode : 15|1@0+ (1,0) [0|1] "SED" Vector__XXX
 SG_ DrvSlipCtlMde_B_Rq : 9|1@0+ (1,0) [0|1] "SED" Vector__XXX
 SG_ Outside_Air_Temp_Stat : 7|8@0+ (0.5,-40) [-40|86.5] "degC"  APIM,APIM_CISM,IPC,WCM

BO_ 1106 TrailerAid_Stat1_HS3: 8 GWM
 SG_ TrlrSnsId_No_Actl : 7|48@0+ (1,0) [0|281474976710653] "unitless"  APIM,APIM_CISM,IPC

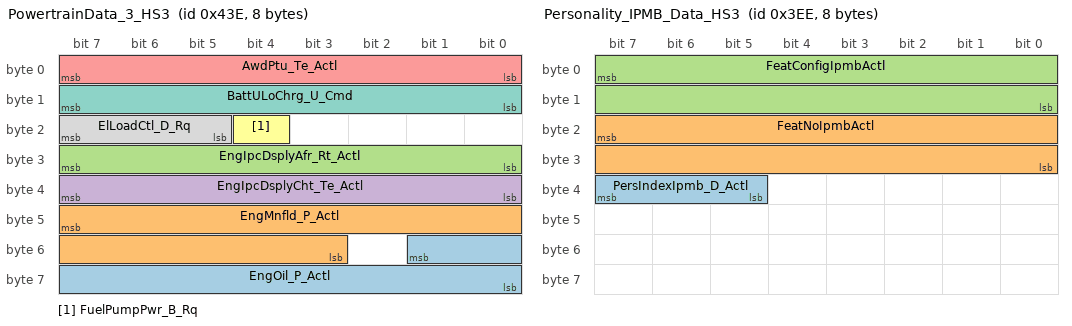
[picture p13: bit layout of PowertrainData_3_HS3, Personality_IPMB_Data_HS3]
BO_ 1086 PowertrainData_3_HS3: 8 GWM
 SG_ EngOil_P_Actl : 49|10@0+ (1,0) [0|1023] "kilopascal"  APIM,APIM_CISM,IPC
 SG_ EngMnfld_P_Actl : 47|13@0+ (0.1,-206.8) [-206.8|612.3] "kilopascal"  APIM,APIM_CISM,IPC
 SG_ EngIpcDsplyAfr_Rt_Actl : 31|8@0+ (0.1,0) [0|25.5] "unitless"  IPC
 SG_ EngIpcDsplyCht_Te_Actl : 39|8@0+ (1,-60) [-60|195] "degC"  IPC
 SG_ AwdPtu_Te_Actl : 7|8@0+ (1,-50) [-50|204] "degC" Vector__XXX
 SG_ FuelPumpPwr_B_Rq : 20|1@0+ (1,0) [0|1] "SED"  IPC
 SG_ BattULoChrg_U_Cmd : 15|8@0+ (0.025,10.6) [10.6|16.975] "volt"  IPC
 SG_ ElLoadCtl_D_Rq : 23|3@0+ (1,0) [0|7] "SED"  IPC

BO_ 817 Locking_Systems_2_HS3: 8 GWM
 SG_ ChildLckMde_B_Stat : 56|1@0+ (1,0) [0|1] "SED"  GENERIC
 SG_ VehLckInd_D_Rq : 58|2@0+ (1,0) [0|3] "SED" Vector__XXX
 SG_ DrTgateOpen_B_Rq : 59|1@0+ (1,0) [0|1] "SED" Vector__XXX
 SG_ DrTgateExtSwMde_B_Stat : 32|1@0+ (1,0) [0|1] "SED" Vector__XXX
 SG_ Remote_Device_Feedback : 50|3@0+ (1,0) [0|7] "SED" Vector__XXX
 SG_ Veh_Lock_Requestor : 55|5@0+ (1,0) [0|31] "SED"  APIM,APIM_CISM,HUD_ADV
 SG_ R_Pwr_Sliding_Dr_Rqst : 36|1@0+ (1,0) [0|1] "SED" Vector__XXX
 SG_ Power_Liftgate_Rqst : 0|1@0+ (1,0) [0|1] "SED" Vector__XXX
 SG_ Veh_Lock_EvNum : 47|8@0+ (1,0) [0|255] "unitless"  HUD_ADV,IPC
 SG_ Power_Decklid_Rqst : 1|1@0+ (1,0) [0|1] "SED" Vector__XXX
 SG_ L_Pwr_Sliding_Dr_Rqst : 3|1@0+ (1,0) [0|1] "SED" Vector__XXX
 SG_ Keyfob_Pad_Msg_Count : 15|8@0+ (1,0) [0|255] "Counts" Vector__XXX
 SG_ Veh_Lock_Sub_Id : 63|4@0+ (1,0) [0|15] "SED" Vector__XXX
 SG_ Veh_Lock_Status : 34|2@0+ (1,0) [0|3] "SED"  APIM,APIM_CISM,HUD_ADV,RACM_RCIM,ACM,IPC
 SG_ ChildLck_D_Dsply : 7|2@0+ (1,0) [0|3] "SED" Vector__XXX
 SG_ WindowLockout_B_Stat : 35|1@0+ (1,0) [0|1] "SED" Vector__XXX
 SG_ RollCodeUnlock : 23|16@0+ (1,0) [0|65535] "unitless"  IPC
 SG_ Lockmsgtxt_D_Rq : 39|3@0+ (1,0) [0|7] "SED"  IPC
 SG_ FobComm_D_Stat : 5|2@0+ (1,0) [0|3] "SED" Vector__XXX
 SG_ LockInhibit : 2|1@0+ (1,0) [0|1] "SED"  APIM,APIM_CISM

BO_ 611 Driveline_Data_1_HS3: 8 GWM
 SG_ AwdTerrMdeChng_D_Rdy : 58|3@0+ (1,0) [0|7] "SED"  IPC
 SG_ AwdTerrMde_D_Actl : 50|3@0+ (1,0) [0|7] "SED"  IPC
 SG_ AwdSys_D_Stat : 27|2@0+ (1,0) [0|3] "SED"  IPC
 SG_ AwdStat_D_RqDsply : 63|5@0+ (1,0) [0|31] "SED"  IPC
 SG_ AwdLck_D_Stat : 31|4@0+ (1,0) [0|15] "SED"  IPC
 SG_ AwdSrvcRqd_B_Rq : 0|1@0+ (1,0) [0|1] "SED"  IPC
 SG_ AwdLck_Tq_Rq : 15|12@0+ (1,0) [0|4093] "Nm"  APIM_CISM,IPC
 SG_ TrnAout_Tq_RqMx : 47|13@0+ (1,-1250) [-1250|6941] "Nm"  IPC
 SG_ AwdOffRoadMode_D_Stats : 25|2@0+ (1,0) [0|3] "SED"  APIM,APIM_CISM,IPC
 SG_ AwdLoLamp_D_RqDsply : 35|2@0+ (1,0) [0|3] "SED"  APIM,APIM_CISM,IPC
 SG_ AwdHiLamp_D_RqDsply : 19|2@0+ (1,0) [0|3] "SED"  APIM,APIM_CISM,IPC
 SG_ AwdAutoLamp_D_RqDsply : 17|2@0+ (1,0) [0|3] "SED"  APIM,APIM_CISM,IPC
 SG_ Awd2wdLamp_D_RqDsply : 2|2@0+ (1,0) [0|3] "SED"  APIM,APIM_CISM,IPC
 SG_ AwdRnge_D_Actl : 7|3@0+ (1,0) [0|7] "SED"  APIM,APIM_CISM,ACM,IPC
 SG_ NtrlTowAvail_B_Stat : 4|1@0+ (1,0) [0|1] "SED"  IPC
 SG_ AwdDrvMde_D_Stat : 38|3@0+ (1,0) [0|7] "SED"  APIM,APIM_CISM,IPC
 SG_ SelDrvMdeAwd_D_Stat : 33|2@0+ (1,0) [0|3] "SED"  GENERIC

BO_ 1114 TrailerAid_Data: 8 IPC
 SG_ TrailCtlSwtch_B_Stat2 : 16|1@0+ (1,0) [0|1] "SED"  GWM
 SG_ TrlBrkInitOut_D_Rq : 60|2@0+ (1,0) [0|3] "SED"  TRM_ITRM,GWM

BO_ 968 Cluster_Lighting_Rq: 8 IPC
 SG_ RvltnMatchAllw_D_Rq : 58|2@0+ (1,0) [0|3] "SED"  GWM
 SG_ BrkDrvMde_D_Rq : 18|3@0+ (1,0) [0|7] "SED"  GWM
 SG_ LnchCtl_N_Rq : 55|8@0+ (50,0) [0|12750] "rpm"  GWM
 SG_ LnchCtl_D_Rq : 63|2@0+ (1,0) [0|3] "SED"  GWM
 SG_ CurrentColor_CmdGage : 43|4@0+ (1,0) [0|15] "SED"  GWM
 SG_ BlendedColor_CmdGage : 25|2@0+ (1,0) [0|3] "SED"  GWM
 SG_ BlendColorRed_CmdGage : 47|4@0+ (1,0) [0|15] "SED"  GWM
 SG_ BlendColorGrn_CmdGage : 35|4@0+ (1,0) [0|15] "SED"  GWM
 SG_ BlendColorBlue_CmdGage : 39|4@0+ (1,0) [0|15] "SED"  GWM
 SG_ Dimming_Level_Cmd : 1|2@0+ (1,0) [0|3] "SED"  GWM
 SG_ Current_Color_Cmd : 23|4@0+ (1,0) [0|15] "SED"  GWM
 SG_ BlendedColorRed_Cmd : 11|4@0+ (1,0) [0|15] "SED"  GWM
 SG_ BlendedColorGreen_Cmd : 15|4@0+ (1,0) [0|15] "SED"  GWM
 SG_ BlendedColorBlue_Cmd : 5|4@0+ (1,0) [0|15] "SED"  GWM
 SG_ BlendedColor_Cmd : 7|2@0+ (1,0) [0|3] "SED"  GWM
 SG_ SuspDrvMde_D_Rq : 61|3@0+ (1,0) [0|7] "SED"  GWM
 SG_ SlMde_D_Rq : 27|2@0+ (1,0) [0|3] "SED"  GWM
 SG_ IsaOffst_D_Rq : 31|4@0+ (1,0) [0|15] "SED"  GWM

BO_ 1006 Personality_IPMB_Data_HS3: 8 GWM
 SG_ PersIndexIpmb_D_Actl : 39|3@0+ (1,0) [0|7] "SED"  APIM,APIM_CISM,ACM
 SG_ FeatNoIpmbActl : 23|16@0+ (1,0) [0|65535] "Number"  APIM,APIM_CISM,ACM
 SG_ FeatConfigIpmbActl : 7|16@0+ (1,0) [0|65535] "Undefined"  APIM,APIM_CISM,ACM

BO_ 129 Steering_Wheel_Data2_HS3: 8 GWM
 SG_ AirbagDrv_B_RqDactv : 36|1@0+ (1,0) [0|1] "SED" Vector__XXX
 SG_ SelDrvMdeSwtch4_D_Stat4 : 38|2@0+ (1,0) [0|3] "SED" Vector__XXX
 SG_ EngExhMdeQuiet_B_RqDrv2 : 39|1@0+ (1,0) [0|1] "SED"  IPC
 SG_ SteWhlSwtchHome_B_Stat : 19|1@0+ (1,0) [0|1] "SED"  IPC
 SG_ SteWhlSwtchInfo_B_Stat : 18|1@0+ (1,0) [0|1] "SED"  IPC
 SG_ SelDrvMdeSwtch3_D_Stat4 : 25|2@0+ (1,0) [0|3] "SED"  GENERIC
 SG_ SelDrvMdeSwtch2_D_Stat4 : 27|2@0+ (1,0) [0|3] "SED"  GENERIC
 SG_ SelDrvMdeSwtch1_D_Stat4 : 29|2@0+ (1,0) [0|3] "SED"  GENERIC
 SG_ PoliceAux4Swtch_B_Stat : 30|1@0+ (1,0) [0|1] "SED"  TRM_ITRM
 SG_ PoliceAux3Swtch_B_Stat : 31|1@0+ (1,0) [0|1] "SED"  TRM_ITRM
 SG_ PoliceAux2Swtch_B_Stat : 16|1@0+ (1,0) [0|1] "SED"  TRM_ITRM
 SG_ SteWhlSwtchView_B_Stat : 23|1@0+ (1,0) [0|1] "SED"  IPC
 SG_ SteWhlSwtchSet_B_Stat : 8|1@0+ (1,0) [0|1] "SED"  IPC
 SG_ SteWhlSwtchPhon_B_Stat : 9|1@0+ (1,0) [0|1] "SED"  HUD_ADV,IPC
 SG_ SteWhlSwtchNav_B_Stat : 10|1@0+ (1,0) [0|1] "SED"  IPC
 SG_ SteWhlSwtchMed_B_Stat : 11|1@0+ (1,0) [0|1] "SED"  HUD_ADV,IPC
 SG_ SteWhlSwtchIod_B_Stat : 12|1@0+ (1,0) [0|1] "SED"  IPC
 SG_ SteWhlSwtchHud_B_Stat : 13|1@0+ (1,0) [0|1] "SED"  HUD_ADV,IPC
 SG_ SteWhlSwtchBack_B_Stat : 14|1@0+ (1,0) [0|1] "SED"  HUD_ADV,IPC
 SG_ PoliceAux1Swtch_B_Stat : 17|1@0+ (1,0) [0|1] "SED"  TRM_ITRM
 SG_ SelDrvMdeSwtch_D_Stat4 : 21|2@0+ (1,0) [0|3] "SED"  APIM,APIM_CISM
 SG_ SteWhlSwtchMenu_B_Stat : 22|1@0+ (1,0) [0|1] "SED"  IPC
 SG_ SteEffortInc_B_RqDrv : 5|1@0+ (1,0) [0|1] "SED"  IPC
 SG_ SelDrvMdeInc_B_RqDrv : 6|1@0+ (1,0) [0|1] "SED"  IPC
 SG_ SelDrvMdeDec_B_RqDrv : 7|1@0+ (1,0) [0|1] "SED"  IPC
 SG_ SuspDampInc_B_RqDrv : 15|1@0+ (1,0) [0|1] "SED"  IPC
 SG_ SteWhlSwtchUp_B_Stat : 3|1@0+ (1,0) [0|1] "SED"  HUD_ADV,IPC
 SG_ SteWhlSwtchRght_B_Stat : 2|1@0+ (1,0) [0|1] "SED"  IPC
 SG_ SteWhlSwtchOk_B_Stat : 4|1@0+ (1,0) [0|1] "SED"  HUD_ADV,IPC
 SG_ SteWhlSwtchLeft_B_Stat : 1|1@0+ (1,0) [0|1] "SED"  IPC
 SG_ SteWhlSwtchDown_B_Stat : 0|1@0+ (1,0) [0|1] "SED"  HUD_ADV,IPC

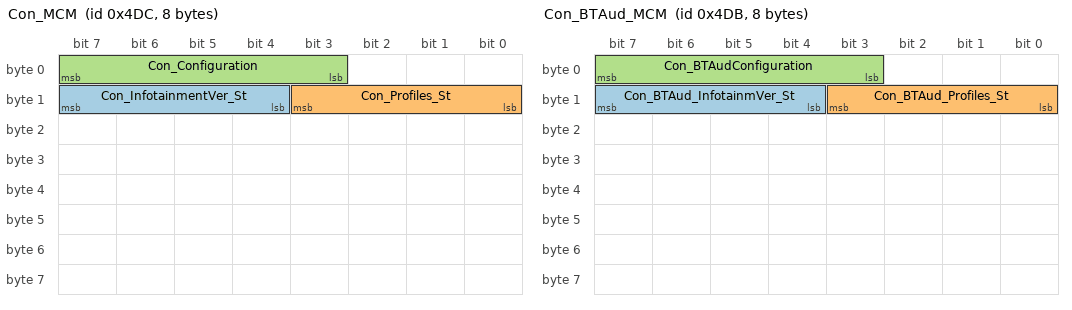
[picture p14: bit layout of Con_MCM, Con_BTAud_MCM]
BO_ 1244 Con_MCM: 8 ACM
 SG_ Con_InfotainmentVer_St : 15|4@0+ (1,0) [0|15] "SED"  IPC
 SG_ Con_Profiles_St : 11|4@0+ (1,0) [0|15] "unitless"  IPC
 SG_ Con_Configuration : 7|5@0+ (1,0) [0|31] "unitless"  IPC

BO_ 1243 Con_BTAud_MCM: 8 ACM
 SG_ Con_BTAud_InfotainmVer_St : 15|4@0+ (1,0) [0|15] "SED"  IPC
 SG_ Con_BTAud_Profiles_St : 11|4@0+ (1,0) [0|15] "unitless"  IPC
 SG_ Con_BTAudConfiguration : 7|5@0+ (1,0) [0|31] "unitless"  IPC

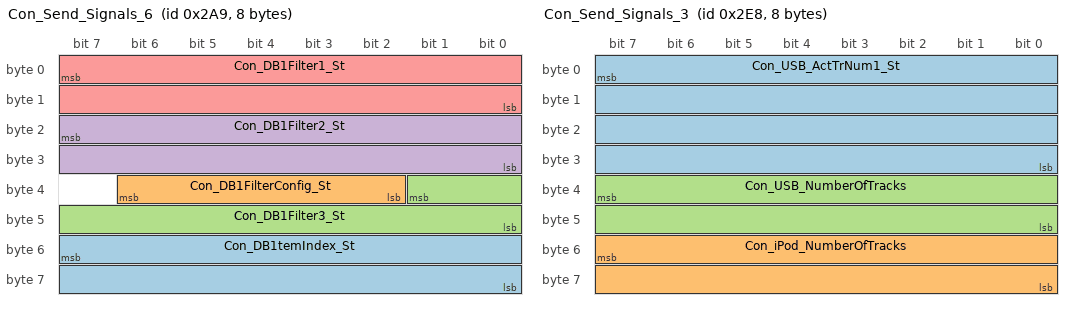
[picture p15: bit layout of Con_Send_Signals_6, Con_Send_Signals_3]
BO_ 681 Con_Send_Signals_6: 8 ACM
 SG_ Con_DB1temIndex_St : 55|16@0+ (1,0) [0|65535] "unitless"  IPC
 SG_ Con_DB1FilterConfig_St : 38|5@0+ (1,0) [0|31] "SED"  IPC
 SG_ Con_DB1Filter3_St : 33|10@0+ (1,0) [0|1023] "unitless"  IPC
 SG_ Con_DB1Filter2_St : 23|16@0+ (1,0) [0|65535] "unitless"  IPC
 SG_ Con_DB1Filter1_St : 7|16@0+ (1,0) [0|65535] "unitless"  IPC

BO_ 744 Con_Send_Signals_3: 8 ACM
 SG_ Con_USB_ActTrNum1_St : 7|32@0+ (1,0) [0|4294967295] "unitless"  IPC
 SG_ Con_iPod_NumberOfTracks : 55|16@0+ (1,0) [0|65535] "unitless"  IPC
 SG_ Con_USB_NumberOfTracks : 39|16@0+ (1,0) [0|65535] "unitless"  IPC

BO_ 712 NAV_MC_WORD_Rx: 8 IPC
 SG_ NAV_MC_WORD_Rx : 7|64@0+ (1,0) [0|1.84467440737096E+019] "unitless"  APIM,APIM_CISM

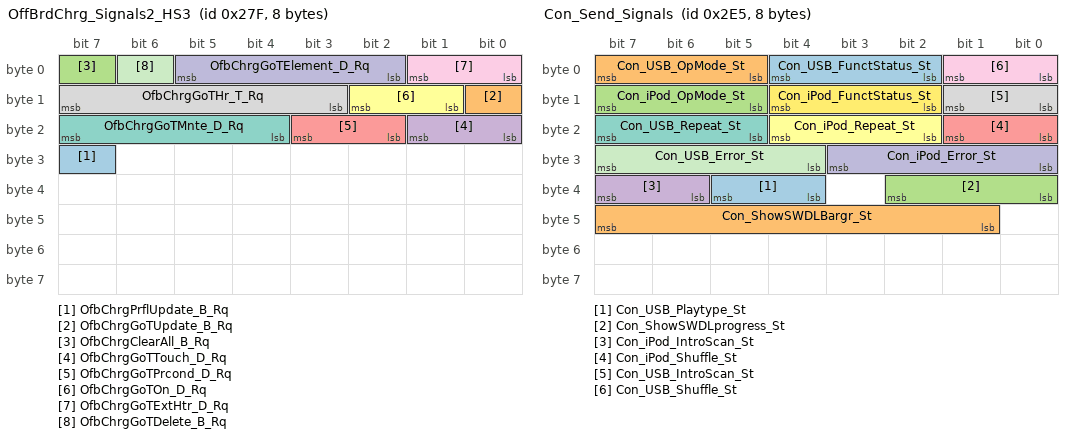
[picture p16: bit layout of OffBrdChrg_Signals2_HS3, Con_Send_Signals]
BO_ 639 OffBrdChrg_Signals2_HS3: 8 GWM
 SG_ OfbChrgPrflUpdate_B_Rq : 31|1@0+ (1,0) [0|1] "SED"  APIM,APIM_CISM
 SG_ OfbChrgGoTUpdate_B_Rq : 8|1@0+ (1,0) [0|1] "SED"  APIM,APIM_CISM
 SG_ OfbChrgClearAll_B_Rq : 7|1@0+ (1,0) [0|1] "SED"  GENERIC
 SG_ OfbChrgGoTTouch_D_Rq : 17|2@0+ (1,0) [0|3] "SED"  GENERIC
 SG_ OfbChrgGoTPrcond_D_Rq : 19|2@0+ (1,0) [0|3] "SED"  GENERIC
 SG_ OfbChrgGoTOn_D_Rq : 10|2@0+ (1,0) [0|3] "SED"  GENERIC
 SG_ OfbChrgGoTMnte_D_Rq : 23|4@0+ (1,0) [0|15] "minute"  GENERIC
 SG_ OfbChrgGoTHr_T_Rq : 15|5@0+ (1,0) [0|29] "hour"  GENERIC
 SG_ OfbChrgGoTExtHtr_D_Rq : 1|2@0+ (1,0) [0|3] "SED"  GENERIC
 SG_ OfbChrgGoTElement_D_Rq : 5|4@0+ (1,0) [0|15] "unitless"  GENERIC
 SG_ OfbChrgGoTDelete_B_Rq : 6|1@0+ (1,0) [0|1] "SED"  GENERIC

BO_ 741 Con_Send_Signals: 8 ACM
 SG_ Con_USB_Playtype_St : 37|2@0+ (1,0) [0|3] "SED"  APIM
 SG_ Con_ShowSWDLBargr_St : 47|7@0+ (1,0) [0|127] "unitless"  APIM
 SG_ Con_ShowSWDLprogress_St : 34|3@0+ (1,0) [0|7] "SED"  APIM
 SG_ Con_iPod_IntroScan_St : 39|2@0+ (1,0) [0|3] "SED"  APIM
 SG_ Con_iPod_Shuffle_St : 17|2@0+ (1,0) [0|3] "SED"  APIM
 SG_ Con_iPod_Repeat_St : 20|3@0+ (1,0) [0|7] "SED"  APIM
 SG_ Con_USB_Repeat_St : 23|3@0+ (1,0) [0|7] "SED"  APIM
 SG_ Con_USB_IntroScan_St : 9|2@0+ (1,0) [0|3] "SED"  APIM
 SG_ Con_USB_Shuffle_St : 1|2@0+ (1,0) [0|3] "SED"  APIM
 SG_ Con_iPod_Error_St : 27|4@0+ (1,0) [0|15] "SED"  APIM
 SG_ Con_USB_Error_St : 31|4@0+ (1,0) [0|15] "SED"  APIM
 SG_ Con_iPod_FunctStatus_St : 12|3@0+ (1,0) [0|7] "SED"  APIM
 SG_ Con_USB_FunctStatus_St : 4|3@0+ (1,0) [0|7] "SED"  APIM
 SG_ Con_USB_OpMode_St : 7|3@0+ (1,0) [0|7] "SED"  APIM
 SG_ Con_iPod_OpMode_St : 15|3@0+ (1,0) [0|7] "SED"  APIM

BO_ 954 Body_Info_10_HS3: 8 GWM
 SG_ ChildLckMaint_D_Stat : 59|2@0+ (1,0) [0|3] "SED" Vector__XXX
 SG_ ExtLghtFront_D_RqBody : 61|2@0+ (1,0) [0|3] "SED" Vector__XXX
 SG_ LoadShedRelay_B_Rq : 40|1@0+ (1,0) [0|1] "SED" Vector__XXX
 SG_ LoadShedRelayMde_D_Stat : 53|2@0+ (1,0) [0|3] "SED" Vector__XXX
 SG_ KeylessIdl_B_Stat : 41|1@0+ (1,0) [0|1] "SED"  APIM,APIM_CISM
 SG_ CargoLght_D_Stat : 55|2@0+ (1,0) [0|3] "SED"  APIM,APIM_CISM
 SG_ TlghtTestLght_D_Stat : 44|3@0+ (1,0) [0|7] "SED"  APIM,APIM_CISM
 SG_ TlghtTestPrecnd_D_Stat : 47|3@0+ (1,0) [0|7] "SED"  APIM,APIM_CISM
 SG_ TlghtTest_D_Stat : 33|2@0+ (1,0) [0|3] "SED"  APIM,APIM_CISM
 SG_ LghtAmbDrvMde_B_Stat : 34|1@0+ (1,0) [0|1] "SED"  APIM,APIM_CISM
 SG_ PwRnngBoardPoll_D_Stat : 36|2@0+ (1,0) [0|3] "SED"  GENERIC
 SG_ PosLghtFr_D_Stat : 49|2@0+ (1,0) [0|3] "SED" Vector__XXX
 SG_ PosLghtFl_D_Stat : 51|2@0+ (1,0) [0|3] "SED" Vector__XXX
 SG_ PoliceDmngLvl_D_Stat : 39|3@0+ (1,0) [0|7] "SED"  APIM,APIM_CISM,IPC
 SG_ TrlrHitchLamp_D_Stat : 25|1@0+ (1,0) [0|1] "SED"  APIM,APIM_CISM
 SG_ LicPlateLght_B_Stat : 26|1@0+ (1,0) [0|1] "SED"  APIM,APIM_CISM
 SG_ TrukBedLght_B_Stat : 24|1@0+ (1,0) [0|1] "SED"  APIM,APIM_CISM
 SG_ VehWlcmFrwlMde_D_Stat : 29|3@0+ (1,0) [0|7] "SED"  APIM,APIM_CISM,IPC
 SG_ GenericSwtch3_No_Actl : 15|3@0+ (1,0) [0|7] "unitless"  TRM_ITRM
 SG_ GenericSwtch2_No_Actl : 4|3@0+ (1,0) [0|7] "unitless"  TRM_ITRM
 SG_ GenericSwtch1_No_Actl : 7|3@0+ (1,0) [0|7] "unitless"  TRM_ITRM
 SG_ PudSptLghtRight_D_Rq : 17|2@0+ (1,0) [0|3] "SED"  GENERIC
 SG_ PudSptLghtLeft_D_Rq : 19|2@0+ (1,0) [0|3] "SED"  GENERIC
 SG_ ExtLghtRight_D_Stat : 21|2@0+ (1,0) [0|3] "SED"  APIM,APIM_CISM
 SG_ VehWlcmFrwl_D_Stat : 31|2@0+ (1,0) [0|3] "SED"  APIM,APIM_CISM,GENERIC
 SG_ ExtLghtRear_D_Stat : 23|2@0+ (1,0) [0|3] "SED"  APIM,APIM_CISM
 SG_ ExtLghtLeft_D_Stat : 9|2@0+ (1,0) [0|3] "SED"  APIM,APIM_CISM
 SG_ ExtLghtAlrt_B_Rq : 12|1@0+ (1,0) [0|1] "SED"  APIM,APIM_CISM
 SG_ ExtLght_D_Falt : 1|2@0+ (1,0) [0|3] "SED"  APIM,APIM_CISM
 SG_ ExtLghtFront_D_Stat : 11|2@0+ (1,0) [0|3] "SED"  APIM,APIM_CISM
 SG_ CrtsyLghtRear_D_Stat : 63|2@0+ (1,0) [0|3] "SED"  APIM,APIM_CISM

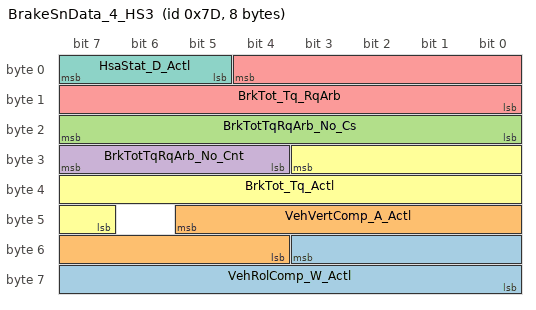
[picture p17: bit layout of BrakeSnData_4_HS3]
BO_ 125 BrakeSnData_4_HS3: 8 GWM
 SG_ VehRolComp_W_Actl : 51|12@0+ (0.03663,-75) [-75|74.92659] "degrees/sec"  APIM,APIM_CISM
 SG_ VehVertComp_A_Actl : 45|10@0+ (0.035,-17.9) [-17.9|17.835] "m/s^2"  APIM,APIM_CISM
 SG_ BrkTotTqRqArb_No_Cs : 23|8@0+ (1,0) [0|255] "unitless"  TRM_ITRM
 SG_ BrkTotTqRqArb_No_Cnt : 31|4@0+ (1,0) [0|15] "unitless"  TRM_ITRM
 SG_ BrkTot_Tq_RqArb : 4|13@0+ (4,0) [0|32756] "Nm"  APIM,APIM_CISM,TRM_ITRM
 SG_ BrkTot_Tq_Actl : 27|13@0+ (4,0) [0|32756] "Nm"  APIM,APIM_CISM,IPC
 SG_ HsaStat_D_Actl : 7|3@0+ (1,0) [0|7] "SED"  IPC

BO_TX_BU_ 760 : APIM_CISM,APIM,ACM;
BO_TX_BU_ 706 : APIM_CISM,APIM,ACM;
BO_TX_BU_ 761 : APIM_CISM,APIM,ACM;
BO_TX_BU_ 694 : APIM_CISM,APIM;
BO_TX_BU_ 750 : APIM_CISM,APIM;
BO_TX_BU_ 704 : APIM_CISM,APIM;
BO_TX_BU_ 725 : APIM_CISM,ACM,APIM;
BO_TX_BU_ 1049 : APIM_CISM,APIM;
BO_TX_BU_ 404 : APIM_CISM,APIM;
BO_TX_BU_ 689 : APIM_CISM,APIM,ACM;
BO_TX_BU_ 1008 : APIM_CISM,APIM;
BO_TX_BU_ 547 : APIM_CISM,ACM,APIM;
BO_TX_BU_ 732 : APIM_CISM,ACM,APIM;
BO_TX_BU_ 728 : APIM_CISM,ACM,APIM;
BO_TX_BU_ 489 : ACM,APIM_CISM,APIM;
BO_TX_BU_ 757 : APIM_CISM,APIM,ACM;
BO_TX_BU_ 734 : APIM_CISM,APIM,ACM;
BO_TX_BU_ 759 : APIM_CISM,APIM,ACM;
BO_TX_BU_ 144 : APIM_CISM,APIM;
BO_TX_BU_ 1124 : APIM_CISM,APIM;
BO_TX_BU_ 1123 : APIM_CISM,APIM;
BO_TX_BU_ 1122 : APIM_CISM,APIM;
CM_ SG_ 760 SDARS_SID_St "Object Tuner.SDARS.ServiceID
$0: SID_0
$1: SID_1
$2: SID_2
$FE: SID_254
$FF: SID_255

";
CM_ SG_ 760 SDARS_CurrentChanNum_St "Object Tuner.SDARS Tuner.CurrentChanNum.ChanNum 
$0: Channel_0
$1: Channel_1
$2: Channel_2
$FE: Channel_254
$FF: Inactive";
CM_ SG_ 760 SDARS_Buffer_sec_St "Object Tuner.SDARS Tuner.BufferStatus.Second
(Parameter5)
";
CM_ SG_ 760 SDARS_Buffer_min_St "Object Tuner.SDARS Tuner.BufferStatus.Minute
(Parameter4)
";
CM_ SG_ 760 SDARS_Buffer_hr_St "Object Tuner.SDARS Tuner.BufferStatus.Hour
(Parameter3)
";
CM_ SG_ 760 SDARS_Playback_St "Method SDARS_BufferStatus
0-100%
Object Tuner.SDARS Tuner.BufferStatus.PlaybackPosition
(Parameter2)";
CM_ SG_ 760 SDARS_FillPosition_St "Method SDARS_BufferStatus
0-100%
Object Tuner.SDARS Tuner.BufferStatus.FillPosition
(Parameter1)";
CM_ SG_ 760 SDARS_Alert_Status "Object.Tuner.SDARS.AlertStatus";
CM_ SG_ 760 SDARS_Channel_Lock "Method SDARS_Channel_Lock";
CM_ SG_ 692 AUDIO_RDISP_WORD_Tx "MM ISO 15765-2 Message Catalogue
Section AUDIO - RDISP";
CM_ SG_ 942 PrkAidRdiusRight_L_Dsply "MSGDCR 679, set all signals to OnChange";
CM_ SG_ 942 PrkAidRdiusLeft_L_Dsply "MSGDCR 679, set all signals to OnChange";
CM_ SG_ 942 PrkAidDrvDir_D_Stat "MSGDCR 679, set all signals to OnChange";
CM_ SG_ 1088 HvacPrecondMode2_D_Rq "Signal not transmitted on vehicles that do not have the Fuel operated heater feature.";
CM_ SG_ 1088 HvacPrecondBlwr2_D_Rq "Signal not transmitted on vehicles that do not have the Fuel operated heater feature.";
CM_ SG_ 761 SDARS_Seek_Scan_St "Method SDARS_Error_Msg
Int Seek/Scan No Channels Available

0x1: No Channel Available
Object Tuner.SDARS Tuner.";
CM_ SG_ 761 SDARS_Invalid_Chan_St "Object Tuner.SDARS Tuner.";
CM_ SG_ 761 SDARS_UnSubscrb_Chan_St "Object Tuner.SDARS Tuner.Unsubscribed Channel ";
CM_ SG_ 761 SDARS_Loss_Ant_St "Object Tuner.SDARS Tuner.Loss of Antenna Signal ";
CM_ SG_ 761 SDARS_UnSubscrb_St "Object Tuner.SDARS Tuner.Unsubscribed Receiver ";
CM_ SG_ 761 SDARS_Subscription_St "Object Tuner.SDARS Tuner.Subscription Update ";
CM_ SG_ 761 SDARS_GCI_Update_St "Object Tuner.SDARS Tuner.GCI Update ";
CM_ SG_ 761 SDARS_Firmware_Updat_St "Object Tuner.SDARS Tuner.FirmwareUpdate";
CM_ SG_ 761 SDARS_Antenna_Err_St "Object Tuner.SDARS Tuner.Antenna Error";
CM_ SG_ 761 SDARS_Receive_Err_St "Object Tuner.SDARS Tuner.Receiver Error";
CM_ SG_ 761 SDARS_Error_Conf_St "Object Tuner.SDARS Tuner.Configuration Status";
CM_ SG_ 694 PHONE_MC_WORD_Tx "MM ISO 15765-2 Message Catalogue
Section  PHONE - MC";
CM_ SG_ 750 UnitOfLength_St "Object.VehicleSettings.LengthUnit.St";
CM_ SG_ 750 RouteActive_St "RouteActive";
CM_ SG_ 750 CancelCurrWaypt_St "Object.NavigationRepeater.CancelCurrentWayPoint.Rsp.Cancelwaypoint";
CM_ SG_ 750 Nav_RemainTTDestDays_St "Object.NavigationRepeater.RemainTimeToDestination.Days
0x0…0xD: days (0…13)
0xE: greater than 13 days";
CM_ SG_ 750 WaypointsActive_St "Object:NavigationRepeater.WaypointsActive.St.WaypointStatus";
CM_ SG_ 750 Nav_RemainTTDestHour_St "Object Navigation.RemainTimeToDestination
0x00 .. 0x18: hours (0 .. 24)
0x19 .. 0x1D: reserved
0x1E : not available";
CM_ SG_ 750 Nav_RemainTTDestMin_St "Object Navigation.RemainTimeToDestination
0x00 .. 0x3C: minutes (0 .. 60)
0x3D .. 0x3D: reserved
0x3E : not available";
CM_ SG_ 750 Nav_DistanToDestUnit_St "Object Navigation.DistanceToDestination

This attribute shows the remaining distance to destination to the infotainment displays.
";
CM_ SG_ 750 Nav_DistancToDestVal_St "Object Navigation.DistanceToDestination

This attribute shows the remaining distance to destination to the infotainment displays.

0x0000 .. 0xFFFD: distance (0 .. 65533)
0xFFFE : distance not available";
CM_ SG_ 750 NavError_Waypoint_St "Object:NavigationRepeater.NAVError.WaypointStatus";
CM_ SG_ 704 NAV_MC_WORD_Tx "MM ISO 15765-2 Message Catalogue
Section NAV - MC
Section NavRepServer - NavRepClient";
CM_ SG_ 725 ACU_CompLogic_St "Object.CDCompLogic_St ";
CM_ SG_ 725 ACU_RadioError_St "Object Audio Management Audio Client.AudioError.RadioError";
CM_ SG_ 725 ACU_HardwareError_St "Object Audio Management Audio Client.AudioError.HardwareError";
CM_ SG_ 725 ACU_CurrentRadioBand_St "Object Tuner.CurrentRadioBand";
CM_ SG_ 725 ACU_CurrentPTYCode_St "Object Tuner.CurrentPTYCode

$0: Invalid
$1: PTY 1 (News)
..
$1F: PTY 31 (Alarm)";
CM_ SG_ 725 ACU_CurrentPICode_St "Object Tuner.CurrentPICode";
CM_ SG_ 725 ACU_CurrentFreq_St "Object Tuner.CurrentFreq

AM: Freq = 153+ Offset kHz.
Offset 0..1557 

FM: Freq = 76+ Offset*0.05 MHz. Offset 0..640
Selected tuned band determine frequency (kHz or MHz).";
CM_ SG_ 725 ACU_AFMode_St "Object Tuner.AFMode";
CM_ SG_ 548 DSP_ChimeChanState_St "Object BodyInterface.StdChimeIF.ChimeChannelState.St";
CM_ SG_ 548 DSP_Chime2_Not_Recgnizd "Object.ChimeAudioSource.DSP_Chime_Not_Recognized ";
CM_ SG_ 548 DSP_Chime_Not_Recgnizd "Object.ChimeAudioSource.DSP_Chime_Not_Recognized ";
CM_ SG_ 548 DSP_Alert_Channel3 "Object.AlertMethod.DSP_AMP_Alert

";
CM_ SG_ 548 DSP_Alert_Channel2 "Object.AlertMethod.DSP_AMP_Alert

";
CM_ SG_ 548 DSP_Alert_Channel1 "Object.AlertMethod.DSP_AMP_Alert

";
CM_ SG_ 548 DSP_Chimes_Supported "Object.AlertMethod.DSP_AMP_Alert

";
CM_ SG_ 548 DSP_AdjChimVolSupp_St "AdjustableChimeVolSupported2";
CM_ SG_ 548 DSP_AdjChimVolSupp2_St "AdjustableChimeVolSupported";
CM_ SG_ 404 Dsp_LangUpdate_Rsp "Object. LanguageUpdate.Rsp";
CM_ SG_ 689 AUDIO_MC_WORD_Tx "MM ISO 15765-2 Message Catalogue
Section Audio - MC";
CM_ SG_ 1008 CPM_MediaPlayerSrc_St "Object AtlanticWizard.AudioManagement.PeripheralMediaPlayerAudioSourceStatus_St";
CM_ SG_ 1008 APIM_TrackPlaytime_St "Object.Mediaplayer.TotalPlayTime";
CM_ SG_ 1008 APIM_TotalPlayTime_St "Object.Mediaplayer.TotalPlayTime";
CM_ SG_ 547 Audio_Amp_St "Object. Audio_Amp_St";
CM_ SG_ 547 Chime_Alert_Chan2 "Object.AlertMethod. AHU_Alerts";
CM_ SG_ 547 AHU_Chime2_Active "Object. AlertMethod. AHU_Alerts

0x0 Inactive
0x1 No_Chime
0x2 Chime_1
0x3 Chime_2
0x4 Chime_3
cont.
0x3F Chime_62";
CM_ SG_ 547 AHU_Chime2_Not_Recognized "Object.AlertMethod. AHU_Alerts";
CM_ SG_ 547 Chime_Alert_Chan "Object.AlertMethod. AHU_Alerts";
CM_ SG_ 547 AHU_Alert_Channel1 "Object.AlertMethod.AHU_Alerts

";
CM_ SG_ 547 AHU_Chime_Supported "Object.AlertMethod. AHU_Alerts";
CM_ SG_ 547 AHU_Chime_Active "Object. AlertMethod. AHU_Alerts

0x0 Inactive
0x1 No_Chime
0x2 Chime_1
0x3 Chime_2
0x4 Chime_3
cont.
0x3F Chime_62";
CM_ SG_ 547 AHU_Chime_Not_Recognized "Object.AlertMethod. AHU_Alerts";
CM_ SG_ 547 AHU_AdjChimVolSupp2_St "AdjustableChimeVolSupported2";
CM_ SG_ 547 AHU_AdjChimeVolSupp_St "AdjustableChimeVolSupported";
CM_ SG_ 732 ACU_CurrItemsInFMSL_St "Object Tuner.CurrentItemsInFMSL";
CM_ SG_ 732 ACU_FunctionStatus_St "Object Indash CD Changer.FunctionStatus
Object Single CD.FunctionStatus";
CM_ SG_ 732 ACU_CurrFMSLPreset_St "Object Tuner.CurrentFMSLPreset

Not applicable for LLA, HLA
CurrentSLIndex";
CM_ SG_ 732 ACU_CurrPreset2_St "Object Tuner.CurrentPreset2";
CM_ SG_ 732 ACU_StorePreset_St "Object Tuner.StorePreset";
CM_ SG_ 732 ACU_VoiceCommand_St "Object VoiceRecogniser.VoiceCommand";
CM_ SG_ 732 ACU_CurrMixPreset_St "Object Tuner.CurrMixPreset";
CM_ SG_ 728 ACU_AuxVolume_Up "Object Audio.Volume_UP
Indicate user value recalls if the value is set to lower/upper border ";
CM_ SG_ 728 ACU_AuxVolume_St "Object Audio.AuxVolume

Level 0..30";
CM_ SG_ 728 ACU_Mid_St "Object Audio.Mid

Level -7..0..7


Method: AHU_Midrange";
CM_ SG_ 728 ACU_RadioSeekMode_St "Object Tuner.RadioSeekMode";
CM_ SG_ 728 ACU_Volume_St "Object Audio.Volume

Level 0..30
Method AHU_Audio_Vol_Level

Refer method table in SPSS for details
0x0 No Volume
0x1 Vol_Step1
0x2 Vol_Step2
0x3 Vol_Step3
Cont.
0x1E Vol_Step30";
CM_ SG_ 728 ACU_Volume_Up "Object Audio.Volume_UP
Indicate user value recalls if the value is set to lower/upper border 
Method AHU_Audio_Vol_Updated";
CM_ SG_ 728 ACU_CurrentStatFlags_St "Object Tuner.CurrentStatFlags

Bit 0: Validation
Bit 1: EON not sup; 1: EON sup
Bit 2: TP not sup; 1: TP sup
Bit 3: 0: Mono; 1: Stereo
Bit 4: 0: RDS not sup; 1: RDS sup";
CM_ SG_ 489 ACU_CurrentPSName_St "Object Tuner.CurrentPSName
Object Tuner.DAB.CurrentServiceName

Text with maximum 8 characters";
CM_ SG_ 757 ACU_AutoStoreResult_St "Object Tuner. RadioSeekModeResult";
CM_ SG_ 757 ACU_DirectTune_St "Object.Tuner.DirectTune";
CM_ SG_ 757 ACU_RadioSeekMode2_St "Object Tuner.RadioSeekMode2";
CM_ SG_ 757 ACU_CurrTUBand_St "Object.Tuner.CurrentTUBand";
CM_ SG_ 734 ACU_ActServiceLink_St "Object DAB.ActServiceLink";
CM_ SG_ 734 ACU_CurrTUDRService2_St "Object DAB.CurrentDRServiceStatus";
CM_ SG_ 734 ACU_ComTUSIDValid_St "Object DAB.CurrentSID.Availability
";
CM_ SG_ 734 ACU_CurrTUDABBlock_St "Object DAB.CurrentDABBlock
Bitfield:
Bit 0..4: L-Band Canada: Numeric value (NV)(1 .. 23); L-Band Europe: NV (A=1 .. W=23); Band III: NV (A=1 .. W=23); 
Bit 5..8: Band III: NV (not used for L-Band; set value to 0h)
Bit 9: 0: Band III, 1: L-Band
";
CM_ SG_ 734 ACU_CurrTUDRService_St "Object DAB.CurrentDRServiceStatus";
CM_ SG_ 734 ACU_CurrTURadioBand_St "Object DAB.CurrentTUBand

Gen3 Values 
$1: reserved
$2: reserved 
$3: reserved
$4: reserved
$5: reserved
$6: reserved";
CM_ SG_ 734 ACU_CurrTUSCIDI_St "Object DAB.CurrentSCIDI";
CM_ SG_ 734 ACU_CurrTUServiceLink_St "Object DAB.CurrentServiceLink";
CM_ SG_ 734 ACU_CurrTUSID_St "Object DAB.CurrentSID.SID

For Digital Radio: 
Byte 1..2: 16 bit hex coded SID
Byte 3:     8 bit hex coded ECC";
CM_ SG_ 759 Avail_HD_Chan_Valid "Object. AvailableHDChannel.St";
CM_ SG_ 759 Avail_HD_Chan_St_7 "Object. AvailableHDChannel.St";
CM_ SG_ 759 Avail_HD_Chan_St_6 "Object. AvailableHDChannel.St";
CM_ SG_ 759 Avail_HD_Chan_St_5 "Object. AvailableHDChannel.St";
CM_ SG_ 759 Avail_HD_Chan_St_4 "Object. AvailableHDChannel.St";
CM_ SG_ 759 Avail_HD_Chan_St_3 "Object. AvailableHDChannel.St";
CM_ SG_ 759 Avail_HD_Chan_St_2 "Object. AvailableHDChannel.St";
CM_ SG_ 759 Avail_HD_Chan_St_1 "Object. AvailableHDChannel.St";
CM_ SG_ 759 ACM_StationListScanSt "Object.AMFMSlave.StationListScan
$0:Invalid";
CM_ SG_ 759 ACM_TagMode "Object.AMFMSlave.TagMode";
CM_ SG_ 759 ACM_RBDSMode "Object.AMFMSlave.RBDSMode";
CM_ SG_ 759 NumofHDMulticastChans_St "Object. AMFMSlave.NumofHDMulticastChans";
CM_ SG_ 759 ACM_HDModeStatus "Object.AMFMSlave.HDMode";
CM_ SG_ 759 ACM_HDChanStatus "Object. AMFMSlave.HDChanStatus
$0:Inactive";
CM_ SG_ 759 ACM_CurrentSSName "Object.AMFMSlave.Method CurrentSSName";
CM_ SG_ 759 ACM_CurrentHDMulticast_St "Object.AMFMSlave.CurrentHDMulticast";
CM_ BO_ 144 "GW Message IMS->BMS";
CM_ SG_ 144 SetTimeFormat "Object.BodyInterface.Settings.VehicleTimeFormatUserSelection";
CM_ SG_ 144 SetYear "Object Clock.SetYear

Request from the Audio Control Unit to the Cluster in order to adjust the years, with an offset of 2000.";
CM_ SG_ 144 SetMonth "Object Clock.SetMonth

Request from the Audio Control Unit to the Cluster in order to adjust the months.";
CM_ SG_ 144 SetDay "Object Clock.SetDay

Request from the Audio Control Unit to the Cluster in order to adjust the days.";
CM_ SG_ 144 SetHour "Object Clock.SetHour

Request from the Audio Control Unit to the Cluster in order to adjust the hours.";
CM_ SG_ 144 SetMinute "Object Clock.SetMinute

Request from the Audio Control Unit to the Cluster in order to adjust the minutes.";
CM_ SG_ 144 SetSecond "Object Clock.SetSecond

Request from the Audio Control Unit to the Cluster in order to adjust the seconds.";
CM_ SG_ 144 TimeAdjustRequest "Object Clock.TimeAdjustRequest

Request from the Audio Control Unit to the Cluster in order to adjust the time.";
CM_ SG_ 144 DateAdjustRequest "Object Clock.DateAdjustRequest

Request from the Audio Control Unit to the Cluster in order to adjust the date.";
CM_ SG_ 851 ConsUnitIPC_D_Dsply "Communicates the instrument cluster current unit mode setting. Used thru-out displays to update units and labels for the fuel consumption history displays. If units updated on cluster, other displays thru-out vehicle should be updated as well.";
CM_ SG_ 792 ElTrip_L_Dsply "Key cycle trip distance driven with the engine off (Trip EV Miles)";
CM_ SG_ 792 ElLongTerm_L_Dsply "Long term distance distance driven with the engine off since the last long term reset (Long Term EV Miles).";
CM_ SG_ 789 VehElSurpStat_L_Dsply "Number of surplus / debt miles displayed on the BEV instrument cluster. Used for BEV cluster and centerstack displays in both numerical an emotive displays. Negative numbers mean a debt, positive numbers are a surplus. ";
CM_ SG_ 789 TripSum_Vl_Dsply "This signal represents the total fuel used by the vehicle on the current trip. It is intended to be used on the cluster shutdown summary screen and in remote data functions (i.e. MyData).";
CM_ SG_ 789 TripSum_E_Dsply "This signal represents the total energy used by the vehicle on the current trip. It is intended to be used on the cluster shutdown summary screen.";
CM_ SG_ 789 TripSum_L_Dsply "Trip Length (Last Drive)";
CM_ SG_ 697 AUDIO_MC_WORD_Rx "MM ISO 15765-2 Message Catalogue
Section MC - Audio";
CM_ SG_ 700 AUDIO_RDISP_WORD_Rx "MM ISO 15765-2 Message Catalogue
Section RDISP - Audio
";
CM_ SG_ 126 StePinRelInit_An_Sns "SASM will transmit these signals on vehicles with SASM and without PSCM.  SCCM will not Tx this signal when SASM is present.";
CM_ SG_ 126 StePinAn_No_Cs "Signal not transmitted on gas variants.";
CM_ SG_ 676 MC_RDISP_WORD_Tx "Communicates ConsHistGraph_St, which includes data to populate the consumption history display.";
CM_ SG_ 504 Mc_AudioSourceSel_Rq "Object Single CD.GetFolderName.AudioSource
Object Media Player
BTAudio.GetFolderName.AudioSource
BTAudio.SetTrack.AudioSource
USB.GetFolderName.AudioSource
USB.SetTrack.AudioSource
SDCard.GetFolderName.AudioSource
SDCard.SetTrack.AudioSource";
CM_ SG_ 504 Mc_FolderNumber_Rq "Object Media Player BTAudio.GetFolderName.FolderName
Object Media Player USB.GetFolderName.FolderName
Object Single CD.GetFolderName.FolderNumber
Object Media Player SDCard.FolderNumber

$FFFF: Inactive";
CM_ SG_ 504 Mc_CutItem_Rq "Object Media Player BTAudio.GetFolderName.CutItemName
Object Media Player USB.GetFolderName.CutItemName
Object Single CD.GetFolderName.CutItem
Object Media Player SDCard.CutItem";
CM_ SG_ 504 Mc_ItemNameLength_Rq "Object Media Player BTAudio.GetFolderName.ItemNameLength
Object Media Player USB.GetFolderName.ItemNameLength
Object Media Player SDCard.GetFolderName.ItemNameLength
Object Single CD.GetFolderName.ItemNameLength";
CM_ SG_ 504 Mc_SourceSetTrack_Rq "Object Media Player BTAudio.SetTrack
Object Media Player USB.SetTrack
Object Media Player SDCard.SetTrack

$0000: Inactive";
CM_ SG_ 410 MyKey_e911Override_St "Object MyKey.MyKey_e911Override_St";
CM_ SG_ 410 DoNotDisturbOveride_St "Object MyKey.DoNotDisturbOverride_St 
";
CM_ BO_ 1124 "HS3 APIM Sync Gen3 Tx 0x464.  FrameGateway to 0x467 on HS1, HS2, HS3 and MS1.";
CM_ BO_ 1123 "HS3 APIM Sync Gen3 Tx 0x463.  FrameGateway to 0x466 on HS1, HS2, HS3 and MS1.";
CM_ BO_ 1122 "HS3 APIM Sync Gen3 Tx 0x462.  FrameGateway to 0x465 on HS1, HS2, HS3 and MS1.";
CM_ SG_ 1050 Outside_Air_Temp_Stat "Filtered value, i.e. same as disply for customer";
CM_ BO_ 1106 " new RCM Serial Trailer Aid (TrailerAid_Stat1) 48 bits";
CM_ SG_ 1086 ElLoadCtl_D_Rq "Signal not transmitted on HEV variants.";
CM_ BO_ 611 "Used on Applications with 4x4 supplied by Motorola.";
CM_ SG_ 611 AwdStat_D_RqDsply "Signal not transmitted on programs that do not have AWD.";
CM_ SG_ 611 AwdSrvcRqd_B_Rq "Signal not transmitted on programs that do not have AWD.";
CM_ SG_ 611 AwdLck_Tq_Rq "Signal not transmitted on programs that do not have AWD.";
CM_ SG_ 129 SelDrvMdeSwtch3_D_Stat4 "ECM_HEV does not support or Transmit signal.";
CM_ SG_ 1244 Con_InfotainmentVer_St "Object Configuration Management.CON_InfotainmetVer";
CM_ SG_ 1244 Con_Profiles_St "Object Configuration Management.CON_Profiles

Bit 0: 0: invalid 1: valid
Bit 1: 0: No iPod browsing support 1: iPod browsing support
Bit 2: 0: No USB browsing support 1: USB browsing support
Bit 3: Reserved
Bit 4: Reserved";
CM_ SG_ 1244 Con_Configuration "Object Configuration Management.CON_Configuration

Bit 0: 0=invalid, 1=valid
Bit 1: SWDLviaUSB support: 0=No, 1=Yes
Bit 2: iPod support 0=No, 1:=Yes
Bit 3: USB support 0=No, 1=Yes
Bit 4: Reserved";
CM_ SG_ 1243 Con_BTAud_InfotainmVer_St "Object Configuration Management.BTAud_InfotainmentVer";
CM_ SG_ 1243 Con_BTAud_Profiles_St "Object Configuration Management.BTAud_Profiles

Bit 0: 0: invalid 1: valid
Bit 1: 0: No BTAudio browsing support 1: BTAudio browsing support
Bit 2: 0: No BTAudio device setting support 1: BTAudio device setting support
Bit 3: ElapsedRemainingTiming

";
CM_ SG_ 1243 Con_BTAudConfiguration "Object Configuration Management.BTAud_Configuration

Bit 0: 0: invalid 1: valid
Bit 1: 0: No BTAudio streaming support 1: BTAudio streaming
Bit 2: 0: No mobile navigation support 1: Mobile navigation";
CM_ SG_ 681 Con_DB1temIndex_St "Object Media Player iPod.MDBActiveTrack.ItemIndex";
CM_ SG_ 681 Con_DB1FilterConfig_St "Object Media Player iPod.MDBActiveTrack.MDBFilterConf";
CM_ SG_ 681 Con_DB1Filter3_St "Object Media Player iPod.MDBActiveTrack.MDBFilter3";
CM_ SG_ 681 Con_DB1Filter2_St "Object Media Player iPod..MDBActiveTrack.MDBFilter2";
CM_ SG_ 681 Con_DB1Filter1_St "Object Media Player iPod..MDBActiveTrack.MDBFilter1";
CM_ SG_ 744 Con_USB_ActTrNum1_St "Object Media Player USB.ActiveTrackNum1";
CM_ SG_ 744 Con_iPod_NumberOfTracks "Object Media Player USB..NumberofTracks
Info: Tracks in current folder";
CM_ SG_ 744 Con_USB_NumberOfTracks "Object Media Player USB..NumberofTracks
Info: Tracks in current folder";
CM_ SG_ 712 NAV_MC_WORD_Rx "MM ISO 15765-2 Message Catalogue
Section MC - NAV
Section NavRepClient - NavRepServer";
CM_ SG_ 741 Con_USB_Playtype_St "Object Media Player USB.Playtype
Playtype:
Playlist is selected if CON module plays tracks out of a Playlist
";
CM_ SG_ 741 Con_ShowSWDLBargr_St "Object SWDL.ShowSWDLBargraphStatus

Range (dec): 0% - 100% (0x00 - 0x64)

No update in progress: ConnectivitySWUpdateNotRunning: $7E";
CM_ SG_ 741 Con_ShowSWDLprogress_St "Object SWDL.Con_ShowCONSWDL_St";
CM_ SG_ 741 Con_iPod_IntroScan_St "Object Media Player iPod.Introscan";
CM_ SG_ 741 Con_iPod_Shuffle_St "Object Media Player iPod.Shuffle";
CM_ SG_ 741 Con_iPod_Repeat_St "Object Media Player iPod.Repeat";
CM_ SG_ 741 Con_USB_Repeat_St "Object Media Player USB.Repeat";
CM_ SG_ 741 Con_USB_IntroScan_St "Object Media Player USB.IntroScan";
CM_ SG_ 741 Con_USB_Shuffle_St "Object MediaPlayer USB.Shuffle";
CM_ SG_ 741 Con_iPod_Error_St "Object Media Player iPod.iPodError";
CM_ SG_ 741 Con_USB_Error_St "Object Media Player USB.USBError";
CM_ SG_ 741 Con_iPod_FunctStatus_St "Object Media Player iPod.FunctionStatus";
CM_ SG_ 741 Con_USB_FunctStatus_St "Object Media Player USB.FunctionStatus";
CM_ SG_ 741 Con_USB_OpMode_St "Object Media Player USB.OperationMode";
CM_ SG_ 741 Con_iPod_OpMode_St "Object Media Player iPod.OperationMode";
CM_ SG_ 954 GenericSwtch2_No_Actl "U625 Police Wig Wag feature";
BA_DEF_ BO_  "FrameRouting" STRING ;
BA_DEF_ BO_  "NetworkInitialization" ENUM  "No","Yes";
BA_DEF_ BO_  "GenMsgStartDelayTime" INT 0 10000;
BA_DEF_ BO_  "GenMsgNrOfRepetition" INT 0 100;
BA_DEF_ BO_  "GenMsgDelayTime" INT 0 1000;
BA_DEF_ BO_  "GenMsgCycleTime" INT 0 100000;
BA_DEF_ BO_  "GenMsgSendType" ENUM  "FixedPeriodic","Event","EnabledPeriodic","NotUsed","NotUsed","EventPeriodic","NotUsed","NotUsed","NoMsgSendType";
BA_DEF_ SG_  "U_V710_MY2023_Tx" ENUM  "No","Yes";
BA_DEF_ SG_  "U_P708_MY2023_Tx" ENUM  "No","Yes";
BA_DEF_ SG_  "U_V713AV_MY2022_Tx" ENUM  "No","Yes";
BA_DEF_ SG_  "U_V713N_MY2022_Tx" ENUM  "No","Yes";
BA_DEF_ SG_  "ECGUsedTxSignal" ENUM  "No","Yes";
BA_DEF_ SG_  "U_V710_MY2023_Rx" ENUM  "No","Yes";
BA_DEF_ SG_  "U_P708_MY2023_Rx" ENUM  "No","Yes";
BA_DEF_ SG_  "U_V713AV_MY2022_Rx" ENUM  "No","Yes";
BA_DEF_ SG_  "U_V713N_MY2022_Rx" ENUM  "No","Yes";
BA_DEF_ SG_  "ECGUsedRxSignal" ENUM  "No","Yes";
BA_DEF_ SG_  "UsedOnPgmDBC" ENUM  "No","Yes";
BA_DEF_ SG_  "ContentDependant" ENUM  "No","Yes";
BA_DEF_ SG_  "GenSigStartValue" HEX 0 268435455;
BA_DEF_ SG_  "MetaData" ENUM  "No","Yes";
BA_DEF_ SG_  "WakeupSignal" ENUM  "No","Yes";
BA_DEF_ SG_  "GenSigInactiveValue" INT 0 100000;
BA_DEF_ SG_  "GenSigSendType" ENUM  "Cyclic","OnWrite","vector_leerstring","OnChange","vector_leerstring","IfActive","vector_leerstring","NoSigSendType";
BA_DEF_ BO_  "TpTxIndex" INT 0 536870911;
BA_DEF_ BO_  "OvtpPushApplication" ENUM  "FALSE","TRUE";
BA_DEF_ BO_  "SCP_FreshnessValueLength" INT 0 512;
BA_DEF_ BO_  "SCP_DataId" INT 0 17663;
BA_DEF_ BO_  "SCP_FreshnessValueTxLength" INT 0 512;
BA_DEF_ BO_  "SCP_AuthInfoTxLength" INT 0 512;
BA_DEF_ BO_  "SC_Message" ENUM  "No","Yes";
BA_DEF_ BO_  "GenMsgRoutingTimeoutTime" INT 0 5000;
BA_DEF_ BO_  "MessageGateway" ENUM  "No","Yes";
BA_DEF_ BO_  "NmAsrMessage" ENUM  "No","Yes";
BA_DEF_ BO_  "DiagState" ENUM  "No","Yes";
BA_DEF_ BO_  "DiagRequest" ENUM  "No","Yes";
BA_DEF_ BO_  "DiagResponse" ENUM  "No","Yes";
BA_DEF_ BO_  "GenMsgILSupport" ENUM  "No","Yes";
BA_DEF_DEF_  "FrameRouting" "";
BA_DEF_DEF_  "NetworkInitialization" "Yes";
BA_DEF_DEF_  "GenMsgStartDelayTime" 0;
BA_DEF_DEF_  "GenMsgNrOfRepetition" 1;
BA_DEF_DEF_  "GenMsgDelayTime" 20;
BA_DEF_DEF_  "GenMsgCycleTime" 0;
BA_DEF_DEF_  "GenMsgSendType" "NoMsgSendType";
BA_DEF_DEF_  "U_V710_MY2023_Tx" "No";
BA_DEF_DEF_  "U_P708_MY2023_Tx" "No";
BA_DEF_DEF_  "U_V713AV_MY2022_Tx" "No";
BA_DEF_DEF_  "U_V713N_MY2022_Tx" "No";
BA_DEF_DEF_  "ECGUsedTxSignal" "No";
BA_DEF_DEF_  "U_V710_MY2023_Rx" "No";
BA_DEF_DEF_  "U_P708_MY2023_Rx" "No";
BA_DEF_DEF_  "U_V713AV_MY2022_Rx" "No";
BA_DEF_DEF_  "U_V713N_MY2022_Rx" "No";
BA_DEF_DEF_  "ECGUsedRxSignal" "No";
BA_DEF_DEF_  "UsedOnPgmDBC" "Yes";
BA_DEF_DEF_  "ContentDependant" "No";
BA_DEF_DEF_  "GenSigStartValue" 0;
BA_DEF_DEF_  "MetaData" "No";
BA_DEF_DEF_  "WakeupSignal" "No";
BA_DEF_DEF_  "GenSigInactiveValue" 0;
BA_DEF_DEF_  "GenSigSendType" "NoSigSendType";
BA_DEF_DEF_  "TpTxIndex" 0;
BA_DEF_DEF_  "OvtpPushApplication" "FALSE";
BA_DEF_DEF_  "SCP_FreshnessValueLength" 64;
BA_DEF_DEF_  "SCP_DataId" 0;
BA_DEF_DEF_  "SCP_FreshnessValueTxLength" 11;
BA_DEF_DEF_  "SCP_AuthInfoTxLength" 53;
BA_DEF_DEF_  "SC_Message" "No";
BA_DEF_DEF_  "GenMsgRoutingTimeoutTime" 0;
BA_DEF_DEF_  "MessageGateway" "No";
BA_DEF_DEF_  "NmAsrMessage" "No";
BA_DEF_DEF_  "DiagState" "No";
BA_DEF_DEF_  "DiagRequest" "No";
BA_DEF_DEF_  "DiagResponse" "No";
BA_DEF_DEF_  "GenMsgILSupport" "Yes";
BA_ "GenMsgCycleTime" BO_ 760 1000;
BA_ "GenMsgSendType" BO_ 760 5;
BA_ "TpTxIndex" BO_ 705 27;
BA_ "FrameRouting" BO_ 1113 "FD1_CAN,0x459;FD3_CAN,0x459";
BA_ "FrameRouting" BO_ 1144 "FD1_CAN,0x478;";
BA_ "FrameRouting" BO_ 523 "FD1_CAN,0x20B;";
BA_ "TpTxIndex" BO_ 692 15;
BA_ "NetworkInitialization" BO_ 1837 0;
BA_ "GenMsgDelayTime" BO_ 1837 0;
BA_ "GenMsgSendType" BO_ 1837 1;
BA_ "DiagResponse" BO_ 1837 1;
BA_ "GenMsgILSupport" BO_ 1837 0;
BA_ "FrameRouting" BO_ 942 "FD1_CAN,0x3AE;FD3_CAN,0x3AE";
BA_ "FrameRouting" BO_ 1088 "FD1_CAN,0x440;";
BA_ "TpTxIndex" BO_ 706 28;
BA_ "GenMsgCycleTime" BO_ 761 1000;
BA_ "GenMsgSendType" BO_ 761 5;
BA_ "TpTxIndex" BO_ 694 17;
BA_ "GenMsgCycleTime" BO_ 750 1000;
BA_ "GenMsgSendType" BO_ 750 5;
BA_ "TpTxIndex" BO_ 704 31;
BA_ "GenMsgCycleTime" BO_ 725 1000;
BA_ "GenMsgSendType" BO_ 725 5;
BA_ "GenMsgCycleTime" BO_ 1049 1000;
BA_ "GenMsgSendType" BO_ 1049 5;
BA_ "GenMsgCycleTime" BO_ 1014 1000;
BA_ "GenMsgSendType" BO_ 1014 5;
BA_ "GenMsgCycleTime" BO_ 548 1000;
BA_ "GenMsgSendType" BO_ 548 5;
BA_ "GenMsgSendType" BO_ 404 1;
BA_ "TpTxIndex" BO_ 689 12;
BA_ "GenMsgCycleTime" BO_ 1008 1000;
BA_ "GenMsgSendType" BO_ 1008 5;
BA_ "GenMsgCycleTime" BO_ 547 1000;
BA_ "GenMsgSendType" BO_ 547 5;
BA_ "GenMsgCycleTime" BO_ 732 1000;
BA_ "GenMsgSendType" BO_ 732 5;
BA_ "GenMsgCycleTime" BO_ 728 1000;
BA_ "GenMsgSendType" BO_ 728 5;
BA_ "GenMsgSendType" BO_ 489 1;
BA_ "GenMsgCycleTime" BO_ 757 1000;
BA_ "GenMsgSendType" BO_ 757 5;
BA_ "GenMsgCycleTime" BO_ 734 1000;
BA_ "GenMsgSendType" BO_ 734 5;
BA_ "NetworkInitialization" BO_ 1420 0;
BA_ "GenMsgCycleTime" BO_ 1420 1000;
BA_ "GenMsgSendType" BO_ 1420 0;
BA_ "NmAsrMessage" BO_ 1420 1;
BA_ "GenMsgILSupport" BO_ 1420 0;
BA_ "GenMsgCycleTime" BO_ 759 1000;
BA_ "GenMsgSendType" BO_ 759 5;
BA_ "NetworkInitialization" BO_ 1960 0;
BA_ "GenMsgDelayTime" BO_ 1960 0;
BA_ "GenMsgSendType" BO_ 1960 1;
BA_ "DiagResponse" BO_ 1960 1;
BA_ "GenMsgILSupport" BO_ 1960 0;
BA_ "NetworkInitialization" BO_ 1952 0;
BA_ "GenMsgDelayTime" BO_ 1952 0;
BA_ "GenMsgSendType" BO_ 1952 1;
BA_ "DiagRequest" BO_ 1952 1;
BA_ "GenMsgILSupport" BO_ 1952 0;
BA_ "GenMsgSendType" BO_ 144 1;
BA_ "GenMsgCycleTime" BO_ 851 1000;
BA_ "GenMsgSendType" BO_ 851 5;
BA_ "GenMsgCycleTime" BO_ 792 100;
BA_ "GenMsgSendType" BO_ 792 0;
BA_ "GenMsgCycleTime" BO_ 789 1000;
BA_ "GenMsgSendType" BO_ 789 0;
BA_ "NetworkInitialization" BO_ 697 0;
BA_ "TpTxIndex" BO_ 697 12;
BA_ "TpTxIndex" BO_ 700 15;
BA_ "FrameRouting" BO_ 126 "FD1_CAN,0x7E;FD3_CAN,0x7E";
BA_ "FrameRouting" BO_ 806 "MS1_CAN,0x326;";
BA_ "NetworkInitialization" BO_ 676 0;
BA_ "TpTxIndex" BO_ 676 29;
BA_ "NetworkInitialization" BO_ 504 0;
BA_ "GenMsgSendType" BO_ 504 1;
BA_ "GenMsgCycleTime" BO_ 410 1000;
BA_ "GenMsgSendType" BO_ 410 5;
BA_ "GenMsgSendType" BO_ 1124 1;
BA_ "GenMsgSendType" BO_ 1123 1;
BA_ "GenMsgSendType" BO_ 1122 1;
BA_ "FrameRouting" BO_ 1050 "MS1_CAN,0x41A;";
BA_ "FrameRouting" BO_ 1106 "HS2_CAN,0x452;";
BA_ "FrameRouting" BO_ 1086 "FD1_CAN,0x43E;";
BA_ "FrameRouting" BO_ 817 "FD1_CAN,0x331;";
BA_ "FrameRouting" BO_ 611 "FD1_CAN,0x263;";
BA_ "GenMsgCycleTime" BO_ 1114 1000;
BA_ "GenMsgSendType" BO_ 1114 5;
BA_ "GenMsgCycleTime" BO_ 968 1000;
BA_ "GenMsgSendType" BO_ 968 5;
BA_ "FrameRouting" BO_ 1006 "FD1_CAN,0x3EE;FD3_CAN,0x3EE";
BA_ "FrameRouting" BO_ 129 "FD3_CAN,0x81;HS2_CAN,0x81";
BA_ "GenMsgCycleTime" BO_ 1244 1000;
BA_ "GenMsgSendType" BO_ 1244 0;
BA_ "GenMsgCycleTime" BO_ 1243 1000;
BA_ "GenMsgSendType" BO_ 1243 0;
BA_ "GenMsgCycleTime" BO_ 681 1000;
BA_ "GenMsgSendType" BO_ 681 5;
BA_ "GenMsgCycleTime" BO_ 744 1000;
BA_ "GenMsgSendType" BO_ 744 5;
BA_ "NetworkInitialization" BO_ 712 0;
BA_ "TpTxIndex" BO_ 712 31;
BA_ "GenMsgCycleTime" BO_ 639 1000;
BA_ "GenMsgSendType" BO_ 639 5;
BA_ "GenMsgCycleTime" BO_ 741 1000;
BA_ "GenMsgSendType" BO_ 741 5;
BA_ "FrameRouting" BO_ 954 "FD1_CAN,0x3BA;";
BA_ "FrameRouting" BO_ 125 "FD1_CAN,0x7D;";
BA_ "U_V710_MY2023_Tx" SG_ 760 SDARS_SID_St 1;
BA_ "U_P708_MY2023_Tx" SG_ 760 SDARS_SID_St 1;
BA_ "U_V713AV_MY2022_Tx" SG_ 760 SDARS_SID_St 1;
BA_ "U_V713N_MY2022_Tx" SG_ 760 SDARS_SID_St 1;
BA_ "U_V710_MY2023_Tx" SG_ 760 SDARS_CurrentChanNum_St 1;
BA_ "U_P708_MY2023_Tx" SG_ 760 SDARS_CurrentChanNum_St 1;
BA_ "U_V713AV_MY2022_Tx" SG_ 760 SDARS_CurrentChanNum_St 1;
BA_ "U_V713N_MY2022_Tx" SG_ 760 SDARS_CurrentChanNum_St 1;
BA_ "U_P708_MY2023_Rx" SG_ 760 SDARS_CurrentChanNum_St 1;
BA_ "U_V713AV_MY2022_Rx" SG_ 760 SDARS_CurrentChanNum_St 1;
BA_ "U_V713N_MY2022_Rx" SG_ 760 SDARS_CurrentChanNum_St 1;
BA_ "U_V710_MY2023_Tx" SG_ 760 SDARS_Buffer_sec_St 1;
BA_ "U_P708_MY2023_Tx" SG_ 760 SDARS_Buffer_sec_St 1;
BA_ "U_V713AV_MY2022_Tx" SG_ 760 SDARS_Buffer_sec_St 1;
BA_ "U_V713N_MY2022_Tx" SG_ 760 SDARS_Buffer_sec_St 1;
BA_ "U_V713AV_MY2022_Rx" SG_ 760 SDARS_Buffer_sec_St 1;
BA_ "U_V713N_MY2022_Rx" SG_ 760 SDARS_Buffer_sec_St 1;
BA_ "U_V710_MY2023_Tx" SG_ 760 SDARS_Buffer_min_St 1;
BA_ "U_P708_MY2023_Tx" SG_ 760 SDARS_Buffer_min_St 1;
BA_ "U_V713AV_MY2022_Tx" SG_ 760 SDARS_Buffer_min_St 1;
BA_ "U_V713N_MY2022_Tx" SG_ 760 SDARS_Buffer_min_St 1;
BA_ "U_V713AV_MY2022_Rx" SG_ 760 SDARS_Buffer_min_St 1;
BA_ "U_V713N_MY2022_Rx" SG_ 760 SDARS_Buffer_min_St 1;
BA_ "U_V710_MY2023_Tx" SG_ 760 SDARS_Buffer_hr_St 1;
BA_ "U_P708_MY2023_Tx" SG_ 760 SDARS_Buffer_hr_St 1;
BA_ "U_V713AV_MY2022_Tx" SG_ 760 SDARS_Buffer_hr_St 1;
BA_ "U_V713N_MY2022_Tx" SG_ 760 SDARS_Buffer_hr_St 1;
BA_ "U_V713AV_MY2022_Rx" SG_ 760 SDARS_Buffer_hr_St 1;
BA_ "U_V713N_MY2022_Rx" SG_ 760 SDARS_Buffer_hr_St 1;
BA_ "U_V710_MY2023_Tx" SG_ 760 SDARS_Playback_St 1;
BA_ "U_P708_MY2023_Tx" SG_ 760 SDARS_Playback_St 1;
BA_ "U_V713AV_MY2022_Tx" SG_ 760 SDARS_Playback_St 1;
BA_ "U_V713N_MY2022_Tx" SG_ 760 SDARS_Playback_St 1;
BA_ "U_P708_MY2023_Rx" SG_ 760 SDARS_Playback_St 1;
BA_ "U_V713AV_MY2022_Rx" SG_ 760 SDARS_Playback_St 1;
BA_ "U_V713N_MY2022_Rx" SG_ 760 SDARS_Playback_St 1;
BA_ "U_V710_MY2023_Tx" SG_ 760 SDARS_FillPosition_St 1;
BA_ "U_P708_MY2023_Tx" SG_ 760 SDARS_FillPosition_St 1;
BA_ "U_V713AV_MY2022_Tx" SG_ 760 SDARS_FillPosition_St 1;
BA_ "U_V713N_MY2022_Tx" SG_ 760 SDARS_FillPosition_St 1;
BA_ "U_V713AV_MY2022_Rx" SG_ 760 SDARS_FillPosition_St 1;
BA_ "U_V713N_MY2022_Rx" SG_ 760 SDARS_FillPosition_St 1;
BA_ "U_V710_MY2023_Tx" SG_ 760 SDARS_Alert_Status 1;
BA_ "U_P708_MY2023_Tx" SG_ 760 SDARS_Alert_Status 1;
BA_ "U_V713AV_MY2022_Tx" SG_ 760 SDARS_Alert_Status 1;
BA_ "U_V713N_MY2022_Tx" SG_ 760 SDARS_Alert_Status 1;
BA_ "U_V713AV_MY2022_Rx" SG_ 760 SDARS_Alert_Status 1;
BA_ "U_V713N_MY2022_Rx" SG_ 760 SDARS_Alert_Status 1;
BA_ "GenSigSendType" SG_ 760 SDARS_Alert_Status 3;
BA_ "U_V710_MY2023_Tx" SG_ 760 SDARS_Channel_Lock 1;
BA_ "U_P708_MY2023_Tx" SG_ 760 SDARS_Channel_Lock 1;
BA_ "U_V713AV_MY2022_Tx" SG_ 760 SDARS_Channel_Lock 1;
BA_ "U_V713N_MY2022_Tx" SG_ 760 SDARS_Channel_Lock 1;
BA_ "U_P708_MY2023_Rx" SG_ 760 SDARS_Channel_Lock 1;
BA_ "U_V713AV_MY2022_Rx" SG_ 760 SDARS_Channel_Lock 1;
BA_ "U_V713N_MY2022_Rx" SG_ 760 SDARS_Channel_Lock 1;
BA_ "GenSigSendType" SG_ 760 SDARS_Channel_Lock 3;
BA_ "U_V710_MY2023_Tx" SG_ 705 SDARS_RDISP_WORD_Tx 1;
BA_ "U_P708_MY2023_Tx" SG_ 705 SDARS_RDISP_WORD_Tx 1;
BA_ "U_V713AV_MY2022_Tx" SG_ 705 SDARS_RDISP_WORD_Tx 1;
BA_ "U_V713N_MY2022_Tx" SG_ 705 SDARS_RDISP_WORD_Tx 1;
BA_ "U_P708_MY2023_Rx" SG_ 1113 TrlrAnOffst_An_Calc 1;
BA_ "U_V713AV_MY2022_Rx" SG_ 1113 TrlrAnOffst_An_Calc 1;
BA_ "U_V713N_MY2022_Rx" SG_ 1113 TrlrAnOffst_An_Calc 1;
BA_ "U_V713AV_MY2022_Rx" SG_ 1113 TrlrAnCalib_B_Complt 1;
BA_ "U_V713N_MY2022_Rx" SG_ 1113 TrlrAnCalib_B_Complt 1;
BA_ "U_P708_MY2023_Rx" SG_ 1113 TrlrAnOffstDir_D_Calc 1;
BA_ "U_V713AV_MY2022_Rx" SG_ 1113 TrlrAnOffstDir_D_Calc 1;
BA_ "U_V713N_MY2022_Rx" SG_ 1113 TrlrAnOffstDir_D_Calc 1;
BA_ "U_V713AV_MY2022_Rx" SG_ 1113 TrlrAidTrgtId_No_Actl 1;
BA_ "U_V713N_MY2022_Rx" SG_ 1113 TrlrAidTrgtId_No_Actl 1;
BA_ "GenSigStartValue" SG_ 1113 HitchToVehAxle_L_Calc 255;
BA_ "GenSigStartValue" SG_ 1144 BattChrgInhbt_D2_Rq 1;
BA_ "U_P708_MY2023_Rx" SG_ 1144 FstChrgCmplt_T_Est 1;
BA_ "U_V710_MY2023_Rx" SG_ 1144 BattChrgTrgtSoC_D_Rq 1;
BA_ "U_P708_MY2023_Rx" SG_ 1144 BattChrgTrgtSoC_D_Rq 1;
BA_ "U_V713AV_MY2022_Rx" SG_ 1144 BattChrgTrgtSoC_D_Rq 1;
BA_ "U_V713N_MY2022_Rx" SG_ 1144 BattChrgTrgtSoC_D_Rq 1;
BA_ "WakeupSignal" SG_ 1144 CabnEvapSovFront_B_Rq 1;
BA_ "WakeupSignal" SG_ 1144 HeatCoreSovRear_B_Rq 1;
BA_ "WakeupSignal" SG_ 1144 BattChlrSov_B_Rq 1;
BA_ "WakeupSignal" SG_ 1144 CabnEvapSovRear_B_Rq 1;
BA_ "GenSigStartValue" SG_ 1144 WakeAlarm0_T_Rq 32767;
BA_ "U_P708_MY2023_Rx" SG_ 523 EngAirFiltLife_Pc_Actl 1;
BA_ "U_V710_MY2023_Rx" SG_ 523 EngAirFiltMsgTxt_D_Rq 1;
BA_ "U_P708_MY2023_Rx" SG_ 523 EngAirFiltMsgTxt_D_Rq 1;
BA_ "U_V710_MY2023_Rx" SG_ 523 WaterInFuel_B_Falt 1;
BA_ "U_P708_MY2023_Rx" SG_ 523 WaterInFuel_B_Falt 1;
BA_ "U_V713N_MY2022_Rx" SG_ 523 WaterInFuel_B_Falt 1;
BA_ "U_P708_MY2023_Rx" SG_ 523 UreaMnAdd_L_Actl 1;
BA_ "U_V710_MY2023_Rx" SG_ 523 UreaMnAdd_L2_Actl 1;
BA_ "U_P708_MY2023_Rx" SG_ 523 UreaMnAdd_L2_Actl 1;
BA_ "U_V710_MY2023_Rx" SG_ 523 VehUreaRnge3_L_DsplyMx 1;
BA_ "U_P708_MY2023_Rx" SG_ 523 VehUreaRnge3_L_DsplyMx 1;
BA_ "U_V710_MY2023_Rx" SG_ 523 UreaMxAdd_L2_Actl 1;
BA_ "U_P708_MY2023_Rx" SG_ 523 UreaMxAdd_L2_Actl 1;
BA_ "GenSigStartValue" SG_ 523 UreaMxAdd_L2_Actl 510;
BA_ "U_V710_MY2023_Tx" SG_ 692 AUDIO_RDISP_WORD_Tx 1;
BA_ "U_P708_MY2023_Tx" SG_ 692 AUDIO_RDISP_WORD_Tx 1;
BA_ "U_V713AV_MY2022_Tx" SG_ 692 AUDIO_RDISP_WORD_Tx 1;
BA_ "U_V713N_MY2022_Tx" SG_ 692 AUDIO_RDISP_WORD_Tx 1;
BA_ "U_V710_MY2023_Tx" SG_ 1837 TesterPhysicalResWCM 1;
BA_ "U_P708_MY2023_Tx" SG_ 1837 TesterPhysicalResWCM 1;
BA_ "U_V713N_MY2022_Tx" SG_ 1837 TesterPhysicalResWCM 1;
BA_ "GenSigSendType" SG_ 1837 TesterPhysicalResWCM 3;
BA_ "GenSigStartValue" SG_ 942 ApaOffOptnSel_B_Avail 1;
BA_ "U_V710_MY2023_Rx" SG_ 942 PrkAidAcsyRear_D_Stat 1;
BA_ "U_P708_MY2023_Rx" SG_ 942 PrkAidAcsyRear_D_Stat 1;
BA_ "U_V713AV_MY2022_Rx" SG_ 942 PrkAidAcsyRear_D_Stat 1;
BA_ "U_V713N_MY2022_Rx" SG_ 942 PrkAidAcsyRear_D_Stat 1;
BA_ "U_V710_MY2023_Rx" SG_ 942 PrkAidAcsyFront_D_Stat 1;
BA_ "U_P708_MY2023_Rx" SG_ 942 PrkAidAcsyFront_D_Stat 1;
BA_ "U_V713AV_MY2022_Rx" SG_ 942 PrkAidAcsyFront_D_Stat 1;
BA_ "U_V713N_MY2022_Rx" SG_ 942 PrkAidAcsyFront_D_Stat 1;
BA_ "GenSigStartValue" SG_ 1088 TrlrRng_L_Dsply 8190;
BA_ "GenSigStartValue" SG_ 1088 BattDcChrgRms_I_Lim 32766;
BA_ "WakeupSignal" SG_ 1088 HvacPrecondMode2_D_Rq 1;
BA_ "WakeupSignal" SG_ 1088 HvacPrecondBlwr2_D_Rq 1;
BA_ "GenSigStartValue" SG_ 1088 HvacPrecond_Te_Rq 2;
BA_ "U_V710_MY2023_Rx" SG_ 1088 ChrgStat_D2_Dsply 1;
BA_ "U_V713AV_MY2022_Rx" SG_ 1088 ChrgStat_D2_Dsply 1;
BA_ "U_V713N_MY2022_Rx" SG_ 1088 ChrgStat_D2_Dsply 1;
BA_ "WakeupSignal" SG_ 1088 ChrgStat_D2_Dsply 1;
BA_ "U_V710_MY2023_Rx" SG_ 1088 ChrgTMatch_B_Stat 1;
BA_ "U_V710_MY2023_Tx" SG_ 706 SDARS_MC_WORD_Tx 1;
BA_ "U_P708_MY2023_Tx" SG_ 706 SDARS_MC_WORD_Tx 1;
BA_ "U_V713AV_MY2022_Tx" SG_ 706 SDARS_MC_WORD_Tx 1;
BA_ "U_V713N_MY2022_Tx" SG_ 706 SDARS_MC_WORD_Tx 1;
BA_ "U_P708_MY2023_Rx" SG_ 706 SDARS_MC_WORD_Tx 1;
BA_ "U_V713AV_MY2022_Rx" SG_ 706 SDARS_MC_WORD_Tx 1;
BA_ "U_V713N_MY2022_Rx" SG_ 706 SDARS_MC_WORD_Tx 1;
BA_ "U_V710_MY2023_Tx" SG_ 761 SDARS_Seek_Scan_St 1;
BA_ "U_P708_MY2023_Tx" SG_ 761 SDARS_Seek_Scan_St 1;
BA_ "U_V713AV_MY2022_Tx" SG_ 761 SDARS_Seek_Scan_St 1;
BA_ "U_V713N_MY2022_Tx" SG_ 761 SDARS_Seek_Scan_St 1;
BA_ "U_V713AV_MY2022_Rx" SG_ 761 SDARS_Seek_Scan_St 1;
BA_ "U_V713N_MY2022_Rx" SG_ 761 SDARS_Seek_Scan_St 1;
BA_ "GenSigSendType" SG_ 761 SDARS_Seek_Scan_St 3;
BA_ "U_V710_MY2023_Tx" SG_ 761 SDARS_Invalid_Chan_St 1;
BA_ "U_P708_MY2023_Tx" SG_ 761 SDARS_Invalid_Chan_St 1;
BA_ "U_V713AV_MY2022_Tx" SG_ 761 SDARS_Invalid_Chan_St 1;
BA_ "U_V713N_MY2022_Tx" SG_ 761 SDARS_Invalid_Chan_St 1;
BA_ "U_P708_MY2023_Rx" SG_ 761 SDARS_Invalid_Chan_St 1;
BA_ "U_V713AV_MY2022_Rx" SG_ 761 SDARS_Invalid_Chan_St 1;
BA_ "U_V713N_MY2022_Rx" SG_ 761 SDARS_Invalid_Chan_St 1;
BA_ "GenSigSendType" SG_ 761 SDARS_Invalid_Chan_St 3;
BA_ "U_V710_MY2023_Tx" SG_ 761 SDARS_UnSubscrb_Chan_St 1;
BA_ "U_P708_MY2023_Tx" SG_ 761 SDARS_UnSubscrb_Chan_St 1;
BA_ "U_V713AV_MY2022_Tx" SG_ 761 SDARS_UnSubscrb_Chan_St 1;
BA_ "U_V713N_MY2022_Tx" SG_ 761 SDARS_UnSubscrb_Chan_St 1;
BA_ "U_P708_MY2023_Rx" SG_ 761 SDARS_UnSubscrb_Chan_St 1;
BA_ "U_V713AV_MY2022_Rx" SG_ 761 SDARS_UnSubscrb_Chan_St 1;
BA_ "U_V713N_MY2022_Rx" SG_ 761 SDARS_UnSubscrb_Chan_St 1;
BA_ "GenSigSendType" SG_ 761 SDARS_UnSubscrb_Chan_St 3;
BA_ "U_V710_MY2023_Tx" SG_ 761 SDARS_Loss_Ant_St 1;
BA_ "U_P708_MY2023_Tx" SG_ 761 SDARS_Loss_Ant_St 1;
BA_ "U_V713AV_MY2022_Tx" SG_ 761 SDARS_Loss_Ant_St 1;
BA_ "U_V713N_MY2022_Tx" SG_ 761 SDARS_Loss_Ant_St 1;
BA_ "U_V713AV_MY2022_Rx" SG_ 761 SDARS_Loss_Ant_St 1;
BA_ "U_V713N_MY2022_Rx" SG_ 761 SDARS_Loss_Ant_St 1;
BA_ "GenSigSendType" SG_ 761 SDARS_Loss_Ant_St 3;
BA_ "U_V710_MY2023_Tx" SG_ 761 SDARS_UnSubscrb_St 1;
BA_ "U_P708_MY2023_Tx" SG_ 761 SDARS_UnSubscrb_St 1;
BA_ "U_V713AV_MY2022_Tx" SG_ 761 SDARS_UnSubscrb_St 1;
BA_ "U_V713N_MY2022_Tx" SG_ 761 SDARS_UnSubscrb_St 1;
BA_ "U_P708_MY2023_Rx" SG_ 761 SDARS_UnSubscrb_St 1;
BA_ "U_V713AV_MY2022_Rx" SG_ 761 SDARS_UnSubscrb_St 1;
BA_ "U_V713N_MY2022_Rx" SG_ 761 SDARS_UnSubscrb_St 1;
BA_ "GenSigSendType" SG_ 761 SDARS_UnSubscrb_St 3;
BA_ "U_V710_MY2023_Tx" SG_ 761 SDARS_Subscription_St 1;
BA_ "U_P708_MY2023_Tx" SG_ 761 SDARS_Subscription_St 1;
BA_ "U_V713AV_MY2022_Tx" SG_ 761 SDARS_Subscription_St 1;
BA_ "U_V713N_MY2022_Tx" SG_ 761 SDARS_Subscription_St 1;
BA_ "U_V713AV_MY2022_Rx" SG_ 761 SDARS_Subscription_St 1;
BA_ "U_V713N_MY2022_Rx" SG_ 761 SDARS_Subscription_St 1;
BA_ "GenSigSendType" SG_ 761 SDARS_Subscription_St 3;
BA_ "U_V710_MY2023_Tx" SG_ 761 SDARS_GCI_Update_St 1;
BA_ "U_P708_MY2023_Tx" SG_ 761 SDARS_GCI_Update_St 1;
BA_ "U_V713AV_MY2022_Tx" SG_ 761 SDARS_GCI_Update_St 1;
BA_ "U_V713N_MY2022_Tx" SG_ 761 SDARS_GCI_Update_St 1;
BA_ "U_V713AV_MY2022_Rx" SG_ 761 SDARS_GCI_Update_St 1;
BA_ "U_V713N_MY2022_Rx" SG_ 761 SDARS_GCI_Update_St 1;
BA_ "GenSigSendType" SG_ 761 SDARS_GCI_Update_St 3;
BA_ "U_V710_MY2023_Tx" SG_ 761 SDARS_Firmware_Updat_St 1;
BA_ "U_P708_MY2023_Tx" SG_ 761 SDARS_Firmware_Updat_St 1;
BA_ "U_V713AV_MY2022_Tx" SG_ 761 SDARS_Firmware_Updat_St 1;
BA_ "U_V713N_MY2022_Tx" SG_ 761 SDARS_Firmware_Updat_St 1;
BA_ "U_V713AV_MY2022_Rx" SG_ 761 SDARS_Firmware_Updat_St 1;
BA_ "U_V713N_MY2022_Rx" SG_ 761 SDARS_Firmware_Updat_St 1;
BA_ "GenSigSendType" SG_ 761 SDARS_Firmware_Updat_St 3;
BA_ "U_V710_MY2023_Tx" SG_ 761 SDARS_Antenna_Err_St 1;
BA_ "U_P708_MY2023_Tx" SG_ 761 SDARS_Antenna_Err_St 1;
BA_ "U_V713AV_MY2022_Tx" SG_ 761 SDARS_Antenna_Err_St 1;
BA_ "U_V713N_MY2022_Tx" SG_ 761 SDARS_Antenna_Err_St 1;
BA_ "U_V713AV_MY2022_Rx" SG_ 761 SDARS_Antenna_Err_St 1;
BA_ "U_V713N_MY2022_Rx" SG_ 761 SDARS_Antenna_Err_St 1;
BA_ "GenSigSendType" SG_ 761 SDARS_Antenna_Err_St 3;
BA_ "U_V710_MY2023_Tx" SG_ 761 SDARS_Receive_Err_St 1;
BA_ "U_P708_MY2023_Tx" SG_ 761 SDARS_Receive_Err_St 1;
BA_ "U_V713AV_MY2022_Tx" SG_ 761 SDARS_Receive_Err_St 1;
BA_ "U_V713N_MY2022_Tx" SG_ 761 SDARS_Receive_Err_St 1;
BA_ "U_V713AV_MY2022_Rx" SG_ 761 SDARS_Receive_Err_St 1;
BA_ "U_V713N_MY2022_Rx" SG_ 761 SDARS_Receive_Err_St 1;
BA_ "GenSigSendType" SG_ 761 SDARS_Receive_Err_St 3;
BA_ "U_V710_MY2023_Tx" SG_ 761 SDARS_Error_Conf_St 1;
BA_ "U_P708_MY2023_Tx" SG_ 761 SDARS_Error_Conf_St 1;
BA_ "U_V713AV_MY2022_Tx" SG_ 761 SDARS_Error_Conf_St 1;
BA_ "U_V713N_MY2022_Tx" SG_ 761 SDARS_Error_Conf_St 1;
BA_ "U_V713AV_MY2022_Rx" SG_ 761 SDARS_Error_Conf_St 1;
BA_ "U_V713N_MY2022_Rx" SG_ 761 SDARS_Error_Conf_St 1;
BA_ "GenSigSendType" SG_ 761 SDARS_Error_Conf_St 3;
BA_ "U_P708_MY2023_Rx" SG_ 694 PHONE_MC_WORD_Tx 1;
BA_ "U_V713AV_MY2022_Rx" SG_ 694 PHONE_MC_WORD_Tx 1;
BA_ "U_V713N_MY2022_Rx" SG_ 694 PHONE_MC_WORD_Tx 1;
BA_ "U_V710_MY2023_Rx" SG_ 750 LoclFuelEffUnit_D_Stat 1;
BA_ "ECGUsedRxSignal" SG_ 750 LoclFuelEffUnit_D_Stat 1;
BA_ "U_P708_MY2023_Rx" SG_ 750 LoclFuelEffUnit_D_Stat 1;
BA_ "U_V713AV_MY2022_Rx" SG_ 750 LoclFuelEffUnit_D_Stat 1;
BA_ "U_V713N_MY2022_Rx" SG_ 750 LoclFuelEffUnit_D_Stat 1;
BA_ "GenSigSendType" SG_ 750 LoclFuelEffUnit_D_Stat 3;
BA_ "U_V710_MY2023_Rx" SG_ 750 RoadsideAsstAvail_D_St 1;
BA_ "U_P708_MY2023_Rx" SG_ 750 RoadsideAsstAvail_D_St 1;
BA_ "U_V713AV_MY2022_Rx" SG_ 750 RoadsideAsstAvail_D_St 1;
BA_ "U_V713N_MY2022_Rx" SG_ 750 RoadsideAsstAvail_D_St 1;
BA_ "GenSigSendType" SG_ 750 RoadsideAsstAvail_D_St 3;
BA_ "U_V710_MY2023_Rx" SG_ 750 EmbedNavActive_D_Stat 1;
BA_ "ECGUsedRxSignal" SG_ 750 EmbedNavActive_D_Stat 1;
BA_ "U_P708_MY2023_Rx" SG_ 750 EmbedNavActive_D_Stat 1;
BA_ "U_V713AV_MY2022_Rx" SG_ 750 EmbedNavActive_D_Stat 1;
BA_ "U_V713N_MY2022_Rx" SG_ 750 EmbedNavActive_D_Stat 1;
BA_ "GenSigSendType" SG_ 750 EmbedNavActive_D_Stat 3;
BA_ "U_V713AV_MY2022_Rx" SG_ 750 UnitOfLength_St 1;
BA_ "U_V713N_MY2022_Rx" SG_ 750 UnitOfLength_St 1;
BA_ "GenSigSendType" SG_ 750 UnitOfLength_St 3;
BA_ "U_P708_MY2023_Rx" SG_ 750 RouteActive_St 1;
BA_ "U_V713AV_MY2022_Rx" SG_ 750 RouteActive_St 1;
BA_ "U_V713N_MY2022_Rx" SG_ 750 RouteActive_St 1;
BA_ "GenSigSendType" SG_ 750 RouteActive_St 3;
BA_ "U_P708_MY2023_Rx" SG_ 750 CancelCurrWaypt_St 1;
BA_ "U_V713AV_MY2022_Rx" SG_ 750 CancelCurrWaypt_St 1;
BA_ "U_V713N_MY2022_Rx" SG_ 750 CancelCurrWaypt_St 1;
BA_ "GenSigSendType" SG_ 750 CancelCurrWaypt_St 3;
BA_ "U_P708_MY2023_Rx" SG_ 750 Nav_RemainTTDestDays_St 1;
BA_ "U_V713AV_MY2022_Rx" SG_ 750 Nav_RemainTTDestDays_St 1;
BA_ "U_V713N_MY2022_Rx" SG_ 750 Nav_RemainTTDestDays_St 1;
BA_ "GenSigSendType" SG_ 750 Nav_RemainTTDestDays_St 3;
BA_ "U_P708_MY2023_Rx" SG_ 750 WaypointsActive_St 1;
BA_ "U_V713AV_MY2022_Rx" SG_ 750 WaypointsActive_St 1;
BA_ "U_V713N_MY2022_Rx" SG_ 750 WaypointsActive_St 1;
BA_ "GenSigSendType" SG_ 750 WaypointsActive_St 3;
BA_ "U_P708_MY2023_Rx" SG_ 750 Nav_RemainTTDestHour_St 1;
BA_ "U_V713AV_MY2022_Rx" SG_ 750 Nav_RemainTTDestHour_St 1;
BA_ "U_V713N_MY2022_Rx" SG_ 750 Nav_RemainTTDestHour_St 1;
BA_ "GenSigSendType" SG_ 750 Nav_RemainTTDestHour_St 3;
BA_ "U_P708_MY2023_Rx" SG_ 750 Nav_RemainTTDestMin_St 1;
BA_ "U_V713AV_MY2022_Rx" SG_ 750 Nav_RemainTTDestMin_St 1;
BA_ "U_V713N_MY2022_Rx" SG_ 750 Nav_RemainTTDestMin_St 1;
BA_ "GenSigSendType" SG_ 750 Nav_RemainTTDestMin_St 3;
BA_ "U_P708_MY2023_Rx" SG_ 750 Nav_DistanToDestUnit_St 1;
BA_ "U_V713AV_MY2022_Rx" SG_ 750 Nav_DistanToDestUnit_St 1;
BA_ "U_V713N_MY2022_Rx" SG_ 750 Nav_DistanToDestUnit_St 1;
BA_ "U_P708_MY2023_Rx" SG_ 750 Nav_DistancToDestVal_St 1;
BA_ "U_V713AV_MY2022_Rx" SG_ 750 Nav_DistancToDestVal_St 1;
BA_ "U_V713N_MY2022_Rx" SG_ 750 Nav_DistancToDestVal_St 1;
BA_ "GenSigSendType" SG_ 750 Nav_DistancToDestVal_St 3;
BA_ "U_P708_MY2023_Rx" SG_ 750 NavError_Waypoint_St 1;
BA_ "U_V713AV_MY2022_Rx" SG_ 750 NavError_Waypoint_St 1;
BA_ "U_V713N_MY2022_Rx" SG_ 750 NavError_Waypoint_St 1;
BA_ "U_P708_MY2023_Rx" SG_ 704 NAV_MC_WORD_Tx 1;
BA_ "U_V710_MY2023_Tx" SG_ 725 InfotainmentAudio_St 1;
BA_ "U_P708_MY2023_Tx" SG_ 725 InfotainmentAudio_St 1;
BA_ "U_V713AV_MY2022_Tx" SG_ 725 InfotainmentAudio_St 1;
BA_ "U_V713N_MY2022_Tx" SG_ 725 InfotainmentAudio_St 1;
BA_ "GenSigSendType" SG_ 725 InfotainmentAudio_St 3;
BA_ "U_V710_MY2023_Tx" SG_ 725 ACU_CompLogic_St 1;
BA_ "U_P708_MY2023_Tx" SG_ 725 ACU_CompLogic_St 1;
BA_ "U_V713AV_MY2022_Tx" SG_ 725 ACU_CompLogic_St 1;
BA_ "U_V713N_MY2022_Tx" SG_ 725 ACU_CompLogic_St 1;
BA_ "GenSigSendType" SG_ 725 ACU_CompLogic_St 3;
BA_ "U_V710_MY2023_Tx" SG_ 725 ACU_RadioError_St 1;
BA_ "U_P708_MY2023_Tx" SG_ 725 ACU_RadioError_St 1;
BA_ "U_V713AV_MY2022_Tx" SG_ 725 ACU_RadioError_St 1;
BA_ "U_V713N_MY2022_Tx" SG_ 725 ACU_RadioError_St 1;
BA_ "U_V713AV_MY2022_Rx" SG_ 725 ACU_RadioError_St 1;
BA_ "U_V713N_MY2022_Rx" SG_ 725 ACU_RadioError_St 1;
BA_ "GenSigSendType" SG_ 725 ACU_RadioError_St 3;
BA_ "U_V710_MY2023_Tx" SG_ 725 ACU_HardwareError_St 1;
BA_ "U_P708_MY2023_Tx" SG_ 725 ACU_HardwareError_St 1;
BA_ "U_V713AV_MY2022_Tx" SG_ 725 ACU_HardwareError_St 1;
BA_ "U_V713N_MY2022_Tx" SG_ 725 ACU_HardwareError_St 1;
BA_ "U_V713AV_MY2022_Rx" SG_ 725 ACU_HardwareError_St 1;
BA_ "U_V713N_MY2022_Rx" SG_ 725 ACU_HardwareError_St 1;
BA_ "GenSigSendType" SG_ 725 ACU_HardwareError_St 3;
BA_ "U_V710_MY2023_Tx" SG_ 725 ACU_CurrentRadioBand_St 1;
BA_ "U_P708_MY2023_Tx" SG_ 725 ACU_CurrentRadioBand_St 1;
BA_ "U_V713AV_MY2022_Tx" SG_ 725 ACU_CurrentRadioBand_St 1;
BA_ "U_V713N_MY2022_Tx" SG_ 725 ACU_CurrentRadioBand_St 1;
BA_ "U_P708_MY2023_Rx" SG_ 725 ACU_CurrentRadioBand_St 1;
BA_ "U_V713AV_MY2022_Rx" SG_ 725 ACU_CurrentRadioBand_St 1;
BA_ "U_V713N_MY2022_Rx" SG_ 725 ACU_CurrentRadioBand_St 1;
BA_ "GenSigSendType" SG_ 725 ACU_CurrentRadioBand_St 3;
BA_ "U_V710_MY2023_Tx" SG_ 725 ACU_CurrentPTYCode_St 1;
BA_ "U_P708_MY2023_Tx" SG_ 725 ACU_CurrentPTYCode_St 1;
BA_ "U_V713AV_MY2022_Tx" SG_ 725 ACU_CurrentPTYCode_St 1;
BA_ "U_V713N_MY2022_Tx" SG_ 725 ACU_CurrentPTYCode_St 1;
BA_ "U_P708_MY2023_Rx" SG_ 725 ACU_CurrentPTYCode_St 1;
BA_ "U_V713AV_MY2022_Rx" SG_ 725 ACU_CurrentPTYCode_St 1;
BA_ "U_V713N_MY2022_Rx" SG_ 725 ACU_CurrentPTYCode_St 1;
BA_ "GenSigSendType" SG_ 725 ACU_CurrentPTYCode_St 3;
BA_ "U_V710_MY2023_Tx" SG_ 725 ACU_CurrentPICode_St 1;
BA_ "U_P708_MY2023_Tx" SG_ 725 ACU_CurrentPICode_St 1;
BA_ "U_V713AV_MY2022_Tx" SG_ 725 ACU_CurrentPICode_St 1;
BA_ "U_V713N_MY2022_Tx" SG_ 725 ACU_CurrentPICode_St 1;
BA_ "GenSigSendType" SG_ 725 ACU_CurrentPICode_St 3;
BA_ "U_V710_MY2023_Tx" SG_ 725 ACU_CurrentFreq_St 1;
BA_ "U_P708_MY2023_Tx" SG_ 725 ACU_CurrentFreq_St 1;
BA_ "U_V713AV_MY2022_Tx" SG_ 725 ACU_CurrentFreq_St 1;
BA_ "U_V713N_MY2022_Tx" SG_ 725 ACU_CurrentFreq_St 1;
BA_ "U_V710_MY2023_Rx" SG_ 725 ACU_CurrentFreq_St 1;
BA_ "U_P708_MY2023_Rx" SG_ 725 ACU_CurrentFreq_St 1;
BA_ "U_V713AV_MY2022_Rx" SG_ 725 ACU_CurrentFreq_St 1;
BA_ "U_V713N_MY2022_Rx" SG_ 725 ACU_CurrentFreq_St 1;
BA_ "GenSigSendType" SG_ 725 ACU_CurrentFreq_St 3;
BA_ "U_V710_MY2023_Tx" SG_ 725 ACU_AFMode_St 1;
BA_ "U_P708_MY2023_Tx" SG_ 725 ACU_AFMode_St 1;
BA_ "U_V713AV_MY2022_Tx" SG_ 725 ACU_AFMode_St 1;
BA_ "U_V713N_MY2022_Tx" SG_ 725 ACU_AFMode_St 1;
BA_ "GenSigSendType" SG_ 725 ACU_AFMode_St 3;
BA_ "GenSigSendType" SG_ 1049 DcacZone3PwBttn_B_Stat 3;
BA_ "GenSigSendType" SG_ 1049 DcacZone2PwBttn_B_Stat 3;
BA_ "GenSigSendType" SG_ 1049 DcacPwResetBtn2_B_Stat 3;
BA_ "GenSigSendType" SG_ 1049 DcacPwOffButtn2_B_Stat 3;
BA_ "GenSigSendType" SG_ 1049 DcacPwHiButtn2_B_Stat 3;
BA_ "GenSigSendType" SG_ 1049 DcacGfciTestBtn2_B_Stat 3;
BA_ "GenSigSendType" SG_ 1049 DcacAllZoneBttn_B_Stat 3;
BA_ "GenSigSendType" SG_ 1049 DcacChime_D_Rq 3;
BA_ "GenSigSendType" SG_ 1049 PersTurnSglView_D_RqMnu 3;
BA_ "GenSigSendType" SG_ 1049 TrailCtlSwtch_B_Stat4 3;
BA_ "GenSigSendType" SG_ 1049 RearDiffLck_D_RqDrv3 3;
BA_ "GenSigStartValue" SG_ 1049 RearDiffLck_D_RqDrv3 2;
BA_ "GenSigSendType" SG_ 1049 FrontDiffLck_D_RqDrv3 3;
BA_ "GenSigStartValue" SG_ 1049 FrontDiffLck_D_RqDrv3 2;
BA_ "GenSigSendType" SG_ 1049 CamraFrnt_B_RqMnu 3;
BA_ "GenSigSendType" SG_ 1049 TurnAsstSwtch_D_Stat 3;
BA_ "GenSigSendType" SG_ 1049 StabBarCnncButtn_D_Sta3 3;
BA_ "GenSigSendType" SG_ 1049 TrlrRngId_No_RqReset 3;
BA_ "GenSigSendType" SG_ 1049 TrlrId_No_ActlMnu 3;
BA_ "GenSigSendType" SG_ 1049 SelDrvMdeTxtRst_B_Rq2 3;
BA_ "GenSigSendType" SG_ 1049 SelDrvMdePage_B_Stat 3;
BA_ "GenSigSendType" SG_ 1049 SelDrvMdeCnfm_D_Stat2 3;
BA_ "GenSigSendType" SG_ 1049 SelDrvMde_D_RqDrv 3;
BA_ "GenSigStartValue" SG_ 1049 SelDrvMde_D_RqDrv 31;
BA_ "U_V710_MY2023_Tx" SG_ 1014 WrlssAcsyChrgr_D_Stat 1;
BA_ "U_P708_MY2023_Tx" SG_ 1014 WrlssAcsyChrgr_D_Stat 1;
BA_ "U_V713N_MY2022_Tx" SG_ 1014 WrlssAcsyChrgr_D_Stat 1;
BA_ "GenSigSendType" SG_ 1014 WrlssAcsyChrgr_D_Stat 3;
BA_ "GenSigStartValue" SG_ 1014 WrlssAcsyChrgr_D_Stat 1;
BA_ "U_V713N_MY2022_Tx" SG_ 1014 WrlssAcsyChrg_Pc_Actl 1;
BA_ "GenSigStartValue" SG_ 1014 WrlssAcsyChrg_Pc_Actl 126;
BA_ "U_V710_MY2023_Rx" SG_ 548 DSP_AHU_ChmTstTone_Rq 1;
BA_ "U_P708_MY2023_Rx" SG_ 548 DSP_AHU_ChmTstTone_Rq 1;
BA_ "U_V713AV_MY2022_Rx" SG_ 548 DSP_AHU_ChmTstTone_Rq 1;
BA_ "U_V713N_MY2022_Rx" SG_ 548 DSP_AHU_ChmTstTone_Rq 1;
BA_ "GenSigSendType" SG_ 548 DSP_AHU_ChmTstTone_Rq 3;
BA_ "U_V710_MY2023_Rx" SG_ 548 DSP_ChimeChanState_St 1;
BA_ "U_P708_MY2023_Rx" SG_ 548 DSP_ChimeChanState_St 1;
BA_ "U_V713AV_MY2022_Rx" SG_ 548 DSP_ChimeChanState_St 1;
BA_ "U_V713N_MY2022_Rx" SG_ 548 DSP_ChimeChanState_St 1;
BA_ "GenSigSendType" SG_ 548 DSP_ChimeChanState_St 3;
BA_ "U_V713AV_MY2022_Rx" SG_ 548 DSP_Chime2_Not_Recgnizd 1;
BA_ "U_V713N_MY2022_Rx" SG_ 548 DSP_Chime2_Not_Recgnizd 1;
BA_ "GenSigSendType" SG_ 548 DSP_Chime2_Not_Recgnizd 3;
BA_ "U_V713AV_MY2022_Rx" SG_ 548 DSP_Chime_Not_Recgnizd 1;
BA_ "U_V713N_MY2022_Rx" SG_ 548 DSP_Chime_Not_Recgnizd 1;
BA_ "GenSigSendType" SG_ 548 DSP_Chime_Not_Recgnizd 3;
BA_ "U_P708_MY2023_Rx" SG_ 548 DSP_Alert_Channel3 1;
BA_ "U_V713AV_MY2022_Rx" SG_ 548 DSP_Alert_Channel3 1;
BA_ "U_V713N_MY2022_Rx" SG_ 548 DSP_Alert_Channel3 1;
BA_ "GenSigSendType" SG_ 548 DSP_Alert_Channel3 3;
BA_ "U_V710_MY2023_Rx" SG_ 548 DSP_Alert_Channel2 1;
BA_ "U_P708_MY2023_Rx" SG_ 548 DSP_Alert_Channel2 1;
BA_ "U_V713AV_MY2022_Rx" SG_ 548 DSP_Alert_Channel2 1;
BA_ "U_V713N_MY2022_Rx" SG_ 548 DSP_Alert_Channel2 1;
BA_ "GenSigSendType" SG_ 548 DSP_Alert_Channel2 3;
BA_ "U_V710_MY2023_Rx" SG_ 548 DSP_Alert_Channel1 1;
BA_ "U_P708_MY2023_Rx" SG_ 548 DSP_Alert_Channel1 1;
BA_ "U_V713AV_MY2022_Rx" SG_ 548 DSP_Alert_Channel1 1;
BA_ "U_V713N_MY2022_Rx" SG_ 548 DSP_Alert_Channel1 1;
BA_ "GenSigSendType" SG_ 548 DSP_Alert_Channel1 3;
BA_ "U_V710_MY2023_Rx" SG_ 548 DSP_Chimes_Supported 1;
BA_ "U_P708_MY2023_Rx" SG_ 548 DSP_Chimes_Supported 1;
BA_ "U_V713AV_MY2022_Rx" SG_ 548 DSP_Chimes_Supported 1;
BA_ "U_V713N_MY2022_Rx" SG_ 548 DSP_Chimes_Supported 1;
BA_ "GenSigSendType" SG_ 548 DSP_Chimes_Supported 3;
BA_ "U_V710_MY2023_Rx" SG_ 548 DSP_AdjChimVolSupp_St 1;
BA_ "U_P708_MY2023_Rx" SG_ 548 DSP_AdjChimVolSupp_St 1;
BA_ "U_V713AV_MY2022_Rx" SG_ 548 DSP_AdjChimVolSupp_St 1;
BA_ "U_V713N_MY2022_Rx" SG_ 548 DSP_AdjChimVolSupp_St 1;
BA_ "GenSigSendType" SG_ 548 DSP_AdjChimVolSupp_St 3;
BA_ "U_V710_MY2023_Rx" SG_ 548 DSP_AdjChimVolSupp2_St 1;
BA_ "U_P708_MY2023_Rx" SG_ 548 DSP_AdjChimVolSupp2_St 1;
BA_ "U_V713AV_MY2022_Rx" SG_ 548 DSP_AdjChimVolSupp2_St 1;
BA_ "U_V713N_MY2022_Rx" SG_ 548 DSP_AdjChimVolSupp2_St 1;
BA_ "GenSigSendType" SG_ 548 DSP_AdjChimVolSupp2_St 3;
BA_ "U_V710_MY2023_Rx" SG_ 548 DSP_AHU_ChmTstT 1;
BA_ "U_P708_MY2023_Rx" SG_ 548 DSP_AHU_ChmTstT 1;
BA_ "U_V713AV_MY2022_Rx" SG_ 548 DSP_AHU_ChmTstT 1;
BA_ "U_V713N_MY2022_Rx" SG_ 548 DSP_AHU_ChmTstT 1;
BA_ "GenSigSendType" SG_ 548 DSP_AHU_ChmTstT 3;
BA_ "U_V710_MY2023_Rx" SG_ 548 DspDgtlChime_D_Stat 1;
BA_ "U_P708_MY2023_Rx" SG_ 548 DspDgtlChime_D_Stat 1;
BA_ "U_V713AV_MY2022_Rx" SG_ 548 DspDgtlChime_D_Stat 1;
BA_ "U_V713N_MY2022_Rx" SG_ 548 DspDgtlChime_D_Stat 1;
BA_ "GenSigSendType" SG_ 548 DspDgtlChime_D_Stat 3;
BA_ "U_V713AV_MY2022_Rx" SG_ 404 Dsp_LangUpdate_Rsp 1;
BA_ "U_V713N_MY2022_Rx" SG_ 404 Dsp_LangUpdate_Rsp 1;
BA_ "GenSigSendType" SG_ 404 Dsp_LangUpdate_Rsp 3;
BA_ "U_V710_MY2023_Tx" SG_ 689 AUDIO_MC_WORD_Tx 1;
BA_ "U_P708_MY2023_Tx" SG_ 689 AUDIO_MC_WORD_Tx 1;
BA_ "U_V713AV_MY2022_Tx" SG_ 689 AUDIO_MC_WORD_Tx 1;
BA_ "U_V713N_MY2022_Tx" SG_ 689 AUDIO_MC_WORD_Tx 1;
BA_ "U_P708_MY2023_Rx" SG_ 689 AUDIO_MC_WORD_Tx 1;
BA_ "U_V713AV_MY2022_Rx" SG_ 689 AUDIO_MC_WORD_Tx 1;
BA_ "U_V713N_MY2022_Rx" SG_ 689 AUDIO_MC_WORD_Tx 1;
BA_ "U_P708_MY2023_Rx" SG_ 1008 NavIod_D_Stat 1;
BA_ "U_V710_MY2023_Rx" SG_ 1008 SelectedNumOfPresets 1;
BA_ "U_P708_MY2023_Rx" SG_ 1008 SelectedNumOfPresets 1;
BA_ "U_V713AV_MY2022_Rx" SG_ 1008 SelectedNumOfPresets 1;
BA_ "U_V713N_MY2022_Rx" SG_ 1008 SelectedNumOfPresets 1;
BA_ "GenSigSendType" SG_ 1008 SelectedNumOfPresets 3;
BA_ "GenSigSendType" SG_ 1008 MultimediaSrc_D_Stat 3;
BA_ "GenSigSendType" SG_ 1008 MultimediaShuf_D_Stat 3;
BA_ "GenSigSendType" SG_ 1008 MultimediaRepeat_D_Stat 3;
BA_ "GenSigSendType" SG_ 1008 CPM_MediaPlayerSrc_St 3;
BA_ "U_P708_MY2023_Rx" SG_ 1008 APIM_TrackPlaytime_St 1;
BA_ "U_P708_MY2023_Rx" SG_ 1008 APIM_TotalPlayTime_St 1;
BA_ "U_V710_MY2023_Tx" SG_ 547 Audio_Amp_St 1;
BA_ "U_P708_MY2023_Tx" SG_ 547 Audio_Amp_St 1;
BA_ "U_V713AV_MY2022_Tx" SG_ 547 Audio_Amp_St 1;
BA_ "U_V713N_MY2022_Tx" SG_ 547 Audio_Amp_St 1;
BA_ "GenSigSendType" SG_ 547 Audio_Amp_St 3;
BA_ "U_V710_MY2023_Tx" SG_ 547 Chime_Alert_Chan2 1;
BA_ "U_P708_MY2023_Tx" SG_ 547 Chime_Alert_Chan2 1;
BA_ "U_V713AV_MY2022_Tx" SG_ 547 Chime_Alert_Chan2 1;
BA_ "U_V713N_MY2022_Tx" SG_ 547 Chime_Alert_Chan2 1;
BA_ "U_V713AV_MY2022_Rx" SG_ 547 Chime_Alert_Chan2 1;
BA_ "U_V713N_MY2022_Rx" SG_ 547 Chime_Alert_Chan2 1;
BA_ "GenSigSendType" SG_ 547 Chime_Alert_Chan2 3;
BA_ "U_V710_MY2023_Tx" SG_ 547 AHU_Chime2_Active 1;
BA_ "U_P708_MY2023_Tx" SG_ 547 AHU_Chime2_Active 1;
BA_ "U_V713AV_MY2022_Tx" SG_ 547 AHU_Chime2_Active 1;
BA_ "U_V713N_MY2022_Tx" SG_ 547 AHU_Chime2_Active 1;
BA_ "U_V710_MY2023_Rx" SG_ 547 AHU_Chime2_Active 1;
BA_ "U_P708_MY2023_Rx" SG_ 547 AHU_Chime2_Active 1;
BA_ "U_V713AV_MY2022_Rx" SG_ 547 AHU_Chime2_Active 1;
BA_ "U_V713N_MY2022_Rx" SG_ 547 AHU_Chime2_Active 1;
BA_ "GenSigSendType" SG_ 547 AHU_Chime2_Active 3;
BA_ "U_V710_MY2023_Tx" SG_ 547 AHU_Chime2_Not_Recognized 1;
BA_ "U_P708_MY2023_Tx" SG_ 547 AHU_Chime2_Not_Recognized 1;
BA_ "U_V713AV_MY2022_Tx" SG_ 547 AHU_Chime2_Not_Recognized 1;
BA_ "U_V713N_MY2022_Tx" SG_ 547 AHU_Chime2_Not_Recognized 1;
BA_ "U_V710_MY2023_Rx" SG_ 547 AHU_Chime2_Not_Recognized 1;
BA_ "U_P708_MY2023_Rx" SG_ 547 AHU_Chime2_Not_Recognized 1;
BA_ "U_V713AV_MY2022_Rx" SG_ 547 AHU_Chime2_Not_Recognized 1;
BA_ "U_V713N_MY2022_Rx" SG_ 547 AHU_Chime2_Not_Recognized 1;
BA_ "GenSigSendType" SG_ 547 AHU_Chime2_Not_Recognized 3;
BA_ "U_V710_MY2023_Tx" SG_ 547 Chime_Alert_Chan 1;
BA_ "U_P708_MY2023_Tx" SG_ 547 Chime_Alert_Chan 1;
BA_ "U_V713AV_MY2022_Tx" SG_ 547 Chime_Alert_Chan 1;
BA_ "U_V713N_MY2022_Tx" SG_ 547 Chime_Alert_Chan 1;
BA_ "U_V713AV_MY2022_Rx" SG_ 547 Chime_Alert_Chan 1;
BA_ "U_V713N_MY2022_Rx" SG_ 547 Chime_Alert_Chan 1;
BA_ "GenSigSendType" SG_ 547 Chime_Alert_Chan 3;
BA_ "U_V710_MY2023_Tx" SG_ 547 AHU_Alert_Channel1 1;
BA_ "U_P708_MY2023_Tx" SG_ 547 AHU_Alert_Channel1 1;
BA_ "U_V713AV_MY2022_Tx" SG_ 547 AHU_Alert_Channel1 1;
BA_ "U_V713N_MY2022_Tx" SG_ 547 AHU_Alert_Channel1 1;
BA_ "U_P708_MY2023_Rx" SG_ 547 AHU_Alert_Channel1 1;
BA_ "GenSigSendType" SG_ 547 AHU_Alert_Channel1 3;
BA_ "U_V710_MY2023_Tx" SG_ 547 AHU_Chime_Supported 1;
BA_ "U_P708_MY2023_Tx" SG_ 547 AHU_Chime_Supported 1;
BA_ "U_V713AV_MY2022_Tx" SG_ 547 AHU_Chime_Supported 1;
BA_ "U_V713N_MY2022_Tx" SG_ 547 AHU_Chime_Supported 1;
BA_ "U_V710_MY2023_Rx" SG_ 547 AHU_Chime_Supported 1;
BA_ "U_P708_MY2023_Rx" SG_ 547 AHU_Chime_Supported 1;
BA_ "U_V713AV_MY2022_Rx" SG_ 547 AHU_Chime_Supported 1;
BA_ "U_V713N_MY2022_Rx" SG_ 547 AHU_Chime_Supported 1;
BA_ "GenSigSendType" SG_ 547 AHU_Chime_Supported 3;
BA_ "U_V710_MY2023_Tx" SG_ 547 AHU_Chime_Active 1;
BA_ "U_P708_MY2023_Tx" SG_ 547 AHU_Chime_Active 1;
BA_ "U_V713AV_MY2022_Tx" SG_ 547 AHU_Chime_Active 1;
BA_ "U_V713N_MY2022_Tx" SG_ 547 AHU_Chime_Active 1;
BA_ "U_V710_MY2023_Rx" SG_ 547 AHU_Chime_Active 1;
BA_ "U_P708_MY2023_Rx" SG_ 547 AHU_Chime_Active 1;
BA_ "U_V713AV_MY2022_Rx" SG_ 547 AHU_Chime_Active 1;
BA_ "U_V713N_MY2022_Rx" SG_ 547 AHU_Chime_Active 1;
BA_ "GenSigSendType" SG_ 547 AHU_Chime_Active 3;
BA_ "U_V710_MY2023_Tx" SG_ 547 AHU_Chime_Not_Recognized 1;
BA_ "U_P708_MY2023_Tx" SG_ 547 AHU_Chime_Not_Recognized 1;
BA_ "U_V713AV_MY2022_Tx" SG_ 547 AHU_Chime_Not_Recognized 1;
BA_ "U_V713N_MY2022_Tx" SG_ 547 AHU_Chime_Not_Recognized 1;
BA_ "U_V710_MY2023_Rx" SG_ 547 AHU_Chime_Not_Recognized 1;
BA_ "U_P708_MY2023_Rx" SG_ 547 AHU_Chime_Not_Recognized 1;
BA_ "U_V713AV_MY2022_Rx" SG_ 547 AHU_Chime_Not_Recognized 1;
BA_ "U_V713N_MY2022_Rx" SG_ 547 AHU_Chime_Not_Recognized 1;
BA_ "GenSigSendType" SG_ 547 AHU_Chime_Not_Recognized 3;
BA_ "U_V710_MY2023_Tx" SG_ 547 ChimeId_No_Stat 1;
BA_ "U_P708_MY2023_Tx" SG_ 547 ChimeId_No_Stat 1;
BA_ "U_V713AV_MY2022_Tx" SG_ 547 ChimeId_No_Stat 1;
BA_ "U_V713N_MY2022_Tx" SG_ 547 ChimeId_No_Stat 1;
BA_ "U_V710_MY2023_Rx" SG_ 547 ChimeId_No_Stat 1;
BA_ "U_V713AV_MY2022_Rx" SG_ 547 ChimeId_No_Stat 1;
BA_ "U_V713N_MY2022_Rx" SG_ 547 ChimeId_No_Stat 1;
BA_ "GenSigSendType" SG_ 547 ChimeId_No_Stat 3;
BA_ "U_V710_MY2023_Tx" SG_ 547 Chime2Id_No_Stat 1;
BA_ "U_P708_MY2023_Tx" SG_ 547 Chime2Id_No_Stat 1;
BA_ "U_V713AV_MY2022_Tx" SG_ 547 Chime2Id_No_Stat 1;
BA_ "U_V713N_MY2022_Tx" SG_ 547 Chime2Id_No_Stat 1;
BA_ "U_V710_MY2023_Rx" SG_ 547 Chime2Id_No_Stat 1;
BA_ "U_V713AV_MY2022_Rx" SG_ 547 Chime2Id_No_Stat 1;
BA_ "U_V713N_MY2022_Rx" SG_ 547 Chime2Id_No_Stat 1;
BA_ "GenSigSendType" SG_ 547 Chime2Id_No_Stat 3;
BA_ "U_V710_MY2023_Tx" SG_ 547 AHU_AdjChimVolSupp2_St 1;
BA_ "U_P708_MY2023_Tx" SG_ 547 AHU_AdjChimVolSupp2_St 1;
BA_ "U_V713AV_MY2022_Tx" SG_ 547 AHU_AdjChimVolSupp2_St 1;
BA_ "U_V713N_MY2022_Tx" SG_ 547 AHU_AdjChimVolSupp2_St 1;
BA_ "U_V710_MY2023_Rx" SG_ 547 AHU_AdjChimVolSupp2_St 1;
BA_ "U_P708_MY2023_Rx" SG_ 547 AHU_AdjChimVolSupp2_St 1;
BA_ "U_V713AV_MY2022_Rx" SG_ 547 AHU_AdjChimVolSupp2_St 1;
BA_ "U_V713N_MY2022_Rx" SG_ 547 AHU_AdjChimVolSupp2_St 1;
BA_ "GenSigSendType" SG_ 547 AHU_AdjChimVolSupp2_St 3;
BA_ "U_V710_MY2023_Tx" SG_ 547 AHU_AdjChimeVolSupp_St 1;
BA_ "U_P708_MY2023_Tx" SG_ 547 AHU_AdjChimeVolSupp_St 1;
BA_ "U_V713AV_MY2022_Tx" SG_ 547 AHU_AdjChimeVolSupp_St 1;
BA_ "U_V713N_MY2022_Tx" SG_ 547 AHU_AdjChimeVolSupp_St 1;
BA_ "U_V710_MY2023_Rx" SG_ 547 AHU_AdjChimeVolSupp_St 1;
BA_ "U_P708_MY2023_Rx" SG_ 547 AHU_AdjChimeVolSupp_St 1;
BA_ "U_V713AV_MY2022_Rx" SG_ 547 AHU_AdjChimeVolSupp_St 1;
BA_ "U_V713N_MY2022_Rx" SG_ 547 AHU_AdjChimeVolSupp_St 1;
BA_ "GenSigSendType" SG_ 547 AHU_AdjChimeVolSupp_St 3;
BA_ "U_V710_MY2023_Tx" SG_ 547 AhuDgtlChime_D_Stat 1;
BA_ "U_P708_MY2023_Tx" SG_ 547 AhuDgtlChime_D_Stat 1;
BA_ "U_V713AV_MY2022_Tx" SG_ 547 AhuDgtlChime_D_Stat 1;
BA_ "U_V713N_MY2022_Tx" SG_ 547 AhuDgtlChime_D_Stat 1;
BA_ "GenSigSendType" SG_ 547 AhuDgtlChime_D_Stat 3;
BA_ "U_V710_MY2023_Tx" SG_ 732 ACU_CurrItemsInFMSL_St 1;
BA_ "U_P708_MY2023_Tx" SG_ 732 ACU_CurrItemsInFMSL_St 1;
BA_ "U_V713AV_MY2022_Tx" SG_ 732 ACU_CurrItemsInFMSL_St 1;
BA_ "U_V713N_MY2022_Tx" SG_ 732 ACU_CurrItemsInFMSL_St 1;
BA_ "U_V710_MY2023_Tx" SG_ 732 ACU_FunctionStatus_St 1;
BA_ "U_P708_MY2023_Tx" SG_ 732 ACU_FunctionStatus_St 1;
BA_ "U_V713AV_MY2022_Tx" SG_ 732 ACU_FunctionStatus_St 1;
BA_ "U_V713N_MY2022_Tx" SG_ 732 ACU_FunctionStatus_St 1;
BA_ "U_V713AV_MY2022_Rx" SG_ 732 ACU_FunctionStatus_St 1;
BA_ "U_V713N_MY2022_Rx" SG_ 732 ACU_FunctionStatus_St 1;
BA_ "GenSigSendType" SG_ 732 ACU_FunctionStatus_St 3;
BA_ "U_V710_MY2023_Tx" SG_ 732 ACU_CurrFMSLPreset_St 1;
BA_ "U_P708_MY2023_Tx" SG_ 732 ACU_CurrFMSLPreset_St 1;
BA_ "U_V713AV_MY2022_Tx" SG_ 732 ACU_CurrFMSLPreset_St 1;
BA_ "U_V713N_MY2022_Tx" SG_ 732 ACU_CurrFMSLPreset_St 1;
BA_ "U_V710_MY2023_Tx" SG_ 732 ACU_CurrPreset2_St 1;
BA_ "U_P708_MY2023_Tx" SG_ 732 ACU_CurrPreset2_St 1;
BA_ "U_V713AV_MY2022_Tx" SG_ 732 ACU_CurrPreset2_St 1;
BA_ "U_V713N_MY2022_Tx" SG_ 732 ACU_CurrPreset2_St 1;
BA_ "U_V713AV_MY2022_Rx" SG_ 732 ACU_CurrPreset2_St 1;
BA_ "U_V713N_MY2022_Rx" SG_ 732 ACU_CurrPreset2_St 1;
BA_ "U_V710_MY2023_Tx" SG_ 732 ACU_StorePreset_St 1;
BA_ "U_P708_MY2023_Tx" SG_ 732 ACU_StorePreset_St 1;
BA_ "U_V713AV_MY2022_Tx" SG_ 732 ACU_StorePreset_St 1;
BA_ "U_V713N_MY2022_Tx" SG_ 732 ACU_StorePreset_St 1;
BA_ "U_V713AV_MY2022_Rx" SG_ 732 ACU_StorePreset_St 1;
BA_ "U_V713N_MY2022_Rx" SG_ 732 ACU_StorePreset_St 1;
BA_ "GenSigSendType" SG_ 732 ACU_StorePreset_St 3;
BA_ "U_V710_MY2023_Tx" SG_ 732 ACU_VoiceCommand_St 1;
BA_ "U_P708_MY2023_Tx" SG_ 732 ACU_VoiceCommand_St 1;
BA_ "U_V713AV_MY2022_Tx" SG_ 732 ACU_VoiceCommand_St 1;
BA_ "U_V713N_MY2022_Tx" SG_ 732 ACU_VoiceCommand_St 1;
BA_ "GenSigSendType" SG_ 732 ACU_VoiceCommand_St 3;
BA_ "U_V710_MY2023_Tx" SG_ 732 ACU_CurrMixPreset_St 1;
BA_ "U_P708_MY2023_Tx" SG_ 732 ACU_CurrMixPreset_St 1;
BA_ "U_V713AV_MY2022_Tx" SG_ 732 ACU_CurrMixPreset_St 1;
BA_ "U_V713N_MY2022_Tx" SG_ 732 ACU_CurrMixPreset_St 1;
BA_ "U_V710_MY2023_Tx" SG_ 728 PrplSnd_D_Stat 1;
BA_ "U_P708_MY2023_Tx" SG_ 728 PrplSnd_D_Stat 1;
BA_ "U_V713AV_MY2022_Tx" SG_ 728 PrplSnd_D_Stat 1;
BA_ "U_V713N_MY2022_Tx" SG_ 728 PrplSnd_D_Stat 1;
BA_ "GenSigSendType" SG_ 728 PrplSnd_D_Stat 3;
BA_ "U_V710_MY2023_Tx" SG_ 728 ACU_AuxVolume_Up 1;
BA_ "U_P708_MY2023_Tx" SG_ 728 ACU_AuxVolume_Up 1;
BA_ "U_V713AV_MY2022_Tx" SG_ 728 ACU_AuxVolume_Up 1;
BA_ "U_V713N_MY2022_Tx" SG_ 728 ACU_AuxVolume_Up 1;
BA_ "U_V713AV_MY2022_Rx" SG_ 728 ACU_AuxVolume_Up 1;
BA_ "U_V713N_MY2022_Rx" SG_ 728 ACU_AuxVolume_Up 1;
BA_ "GenSigSendType" SG_ 728 ACU_AuxVolume_Up 3;
BA_ "U_V710_MY2023_Tx" SG_ 728 ACU_AuxVolume_St 1;
BA_ "U_P708_MY2023_Tx" SG_ 728 ACU_AuxVolume_St 1;
BA_ "U_V713AV_MY2022_Tx" SG_ 728 ACU_AuxVolume_St 1;
BA_ "U_V713N_MY2022_Tx" SG_ 728 ACU_AuxVolume_St 1;
BA_ "U_V713AV_MY2022_Rx" SG_ 728 ACU_AuxVolume_St 1;
BA_ "U_V713N_MY2022_Rx" SG_ 728 ACU_AuxVolume_St 1;
BA_ "U_V710_MY2023_Tx" SG_ 728 ACU_Mid_St 1;
BA_ "U_P708_MY2023_Tx" SG_ 728 ACU_Mid_St 1;
BA_ "U_V713AV_MY2022_Tx" SG_ 728 ACU_Mid_St 1;
BA_ "U_V713N_MY2022_Tx" SG_ 728 ACU_Mid_St 1;
BA_ "U_V710_MY2023_Tx" SG_ 728 ACU_RadioSeekMode_St 1;
BA_ "U_P708_MY2023_Tx" SG_ 728 ACU_RadioSeekMode_St 1;
BA_ "U_V713AV_MY2022_Tx" SG_ 728 ACU_RadioSeekMode_St 1;
BA_ "U_V713N_MY2022_Tx" SG_ 728 ACU_RadioSeekMode_St 1;
BA_ "U_V713AV_MY2022_Rx" SG_ 728 ACU_RadioSeekMode_St 1;
BA_ "U_V713N_MY2022_Rx" SG_ 728 ACU_RadioSeekMode_St 1;
BA_ "GenSigSendType" SG_ 728 ACU_RadioSeekMode_St 3;
BA_ "U_V710_MY2023_Tx" SG_ 728 ACU_Volume_St 1;
BA_ "U_P708_MY2023_Tx" SG_ 728 ACU_Volume_St 1;
BA_ "U_V713AV_MY2022_Tx" SG_ 728 ACU_Volume_St 1;
BA_ "U_V713N_MY2022_Tx" SG_ 728 ACU_Volume_St 1;
BA_ "U_V710_MY2023_Rx" SG_ 728 ACU_Volume_St 1;
BA_ "ECGUsedRxSignal" SG_ 728 ACU_Volume_St 1;
BA_ "U_P708_MY2023_Rx" SG_ 728 ACU_Volume_St 1;
BA_ "U_V713AV_MY2022_Rx" SG_ 728 ACU_Volume_St 1;
BA_ "U_V713N_MY2022_Rx" SG_ 728 ACU_Volume_St 1;
BA_ "U_V710_MY2023_Tx" SG_ 728 ACU_Volume_Up 1;
BA_ "U_P708_MY2023_Tx" SG_ 728 ACU_Volume_Up 1;
BA_ "U_V713AV_MY2022_Tx" SG_ 728 ACU_Volume_Up 1;
BA_ "U_V713N_MY2022_Tx" SG_ 728 ACU_Volume_Up 1;
BA_ "U_V713AV_MY2022_Rx" SG_ 728 ACU_Volume_Up 1;
BA_ "U_V713N_MY2022_Rx" SG_ 728 ACU_Volume_Up 1;
BA_ "GenSigSendType" SG_ 728 ACU_Volume_Up 3;
BA_ "U_V710_MY2023_Tx" SG_ 728 ACU_CurrentStatFlags_St 1;
BA_ "U_P708_MY2023_Tx" SG_ 728 ACU_CurrentStatFlags_St 1;
BA_ "U_V713AV_MY2022_Tx" SG_ 728 ACU_CurrentStatFlags_St 1;
BA_ "U_V713N_MY2022_Tx" SG_ 728 ACU_CurrentStatFlags_St 1;
BA_ "U_P708_MY2023_Rx" SG_ 728 ACU_CurrentStatFlags_St 1;
BA_ "U_V713AV_MY2022_Rx" SG_ 728 ACU_CurrentStatFlags_St 1;
BA_ "U_V713N_MY2022_Rx" SG_ 728 ACU_CurrentStatFlags_St 1;
BA_ "U_V710_MY2023_Tx" SG_ 489 ACU_CurrentPSName_St 1;
BA_ "U_P708_MY2023_Tx" SG_ 489 ACU_CurrentPSName_St 1;
BA_ "U_V713AV_MY2022_Tx" SG_ 489 ACU_CurrentPSName_St 1;
BA_ "U_V713N_MY2022_Tx" SG_ 489 ACU_CurrentPSName_St 1;
BA_ "U_P708_MY2023_Rx" SG_ 489 ACU_CurrentPSName_St 1;
BA_ "U_V713AV_MY2022_Rx" SG_ 489 ACU_CurrentPSName_St 1;
BA_ "U_V713N_MY2022_Rx" SG_ 489 ACU_CurrentPSName_St 1;
BA_ "GenSigSendType" SG_ 489 ACU_CurrentPSName_St 3;
BA_ "U_V710_MY2023_Tx" SG_ 757 SpkrStdRight_D_Stat 1;
BA_ "U_P708_MY2023_Tx" SG_ 757 SpkrStdRight_D_Stat 1;
BA_ "U_V713AV_MY2022_Tx" SG_ 757 SpkrStdRight_D_Stat 1;
BA_ "U_V713N_MY2022_Tx" SG_ 757 SpkrStdRight_D_Stat 1;
BA_ "GenSigSendType" SG_ 757 SpkrStdRight_D_Stat 3;
BA_ "U_V710_MY2023_Tx" SG_ 757 SpkrStdLeft_D_Stat 1;
BA_ "U_P708_MY2023_Tx" SG_ 757 SpkrStdLeft_D_Stat 1;
BA_ "U_V713AV_MY2022_Tx" SG_ 757 SpkrStdLeft_D_Stat 1;
BA_ "U_V713N_MY2022_Tx" SG_ 757 SpkrStdLeft_D_Stat 1;
BA_ "GenSigSendType" SG_ 757 SpkrStdLeft_D_Stat 3;
BA_ "U_V710_MY2023_Tx" SG_ 757 SpkrStdCntr_D_Stat 1;
BA_ "U_P708_MY2023_Tx" SG_ 757 SpkrStdCntr_D_Stat 1;
BA_ "U_V713AV_MY2022_Tx" SG_ 757 SpkrStdCntr_D_Stat 1;
BA_ "U_V713N_MY2022_Tx" SG_ 757 SpkrStdCntr_D_Stat 1;
BA_ "GenSigSendType" SG_ 757 SpkrStdCntr_D_Stat 3;
BA_ "U_V710_MY2023_Tx" SG_ 757 SdarsAudioRtng_D_Stat 1;
BA_ "U_P708_MY2023_Tx" SG_ 757 SdarsAudioRtng_D_Stat 1;
BA_ "U_V713AV_MY2022_Tx" SG_ 757 SdarsAudioRtng_D_Stat 1;
BA_ "U_V713N_MY2022_Tx" SG_ 757 SdarsAudioRtng_D_Stat 1;
BA_ "GenSigSendType" SG_ 757 SdarsAudioRtng_D_Stat 3;
BA_ "U_V710_MY2023_Tx" SG_ 757 SDARS_ChipControl_St 1;
BA_ "U_P708_MY2023_Tx" SG_ 757 SDARS_ChipControl_St 1;
BA_ "U_V713AV_MY2022_Tx" SG_ 757 SDARS_ChipControl_St 1;
BA_ "U_V713N_MY2022_Tx" SG_ 757 SDARS_ChipControl_St 1;
BA_ "GenSigSendType" SG_ 757 SDARS_ChipControl_St 3;
BA_ "U_V710_MY2023_Tx" SG_ 757 ACU_AutoStoreResult_St 1;
BA_ "U_P708_MY2023_Tx" SG_ 757 ACU_AutoStoreResult_St 1;
BA_ "U_V713AV_MY2022_Tx" SG_ 757 ACU_AutoStoreResult_St 1;
BA_ "U_V713N_MY2022_Tx" SG_ 757 ACU_AutoStoreResult_St 1;
BA_ "U_V713AV_MY2022_Rx" SG_ 757 ACU_AutoStoreResult_St 1;
BA_ "U_V713N_MY2022_Rx" SG_ 757 ACU_AutoStoreResult_St 1;
BA_ "GenSigSendType" SG_ 757 ACU_AutoStoreResult_St 3;
BA_ "U_V710_MY2023_Tx" SG_ 757 ACU_DirectTune_St 1;
BA_ "U_P708_MY2023_Tx" SG_ 757 ACU_DirectTune_St 1;
BA_ "U_V713AV_MY2022_Tx" SG_ 757 ACU_DirectTune_St 1;
BA_ "U_V713N_MY2022_Tx" SG_ 757 ACU_DirectTune_St 1;
BA_ "U_V713AV_MY2022_Rx" SG_ 757 ACU_DirectTune_St 1;
BA_ "U_V713N_MY2022_Rx" SG_ 757 ACU_DirectTune_St 1;
BA_ "GenSigSendType" SG_ 757 ACU_DirectTune_St 3;
BA_ "U_V710_MY2023_Tx" SG_ 757 ACU_RadioSeekMode2_St 1;
BA_ "U_P708_MY2023_Tx" SG_ 757 ACU_RadioSeekMode2_St 1;
BA_ "U_V713AV_MY2022_Tx" SG_ 757 ACU_RadioSeekMode2_St 1;
BA_ "U_V713N_MY2022_Tx" SG_ 757 ACU_RadioSeekMode2_St 1;
BA_ "U_V710_MY2023_Rx" SG_ 757 ACU_RadioSeekMode2_St 1;
BA_ "U_P708_MY2023_Rx" SG_ 757 ACU_RadioSeekMode2_St 1;
BA_ "U_V713AV_MY2022_Rx" SG_ 757 ACU_RadioSeekMode2_St 1;
BA_ "U_V713N_MY2022_Rx" SG_ 757 ACU_RadioSeekMode2_St 1;
BA_ "GenSigSendType" SG_ 757 ACU_RadioSeekMode2_St 3;
BA_ "U_V710_MY2023_Tx" SG_ 757 ACU_CurrTUBand_St 1;
BA_ "U_P708_MY2023_Tx" SG_ 757 ACU_CurrTUBand_St 1;
BA_ "U_V713AV_MY2022_Tx" SG_ 757 ACU_CurrTUBand_St 1;
BA_ "U_V713N_MY2022_Tx" SG_ 757 ACU_CurrTUBand_St 1;
BA_ "U_V710_MY2023_Rx" SG_ 757 ACU_CurrTUBand_St 1;
BA_ "U_P708_MY2023_Rx" SG_ 757 ACU_CurrTUBand_St 1;
BA_ "U_V713AV_MY2022_Rx" SG_ 757 ACU_CurrTUBand_St 1;
BA_ "U_V713N_MY2022_Rx" SG_ 757 ACU_CurrTUBand_St 1;
BA_ "GenSigSendType" SG_ 757 ACU_CurrTUBand_St 3;
BA_ "U_V710_MY2023_Tx" SG_ 734 ACU_ActServiceLink_St 1;
BA_ "U_P708_MY2023_Tx" SG_ 734 ACU_ActServiceLink_St 1;
BA_ "U_V713AV_MY2022_Tx" SG_ 734 ACU_ActServiceLink_St 1;
BA_ "U_V713N_MY2022_Tx" SG_ 734 ACU_ActServiceLink_St 1;
BA_ "U_P708_MY2023_Rx" SG_ 734 ACU_ActServiceLink_St 1;
BA_ "GenSigSendType" SG_ 734 ACU_ActServiceLink_St 3;
BA_ "U_V710_MY2023_Tx" SG_ 734 ACU_CurrTUDRService2_St 1;
BA_ "U_P708_MY2023_Tx" SG_ 734 ACU_CurrTUDRService2_St 1;
BA_ "U_V713AV_MY2022_Tx" SG_ 734 ACU_CurrTUDRService2_St 1;
BA_ "U_V713N_MY2022_Tx" SG_ 734 ACU_CurrTUDRService2_St 1;
BA_ "U_V713AV_MY2022_Rx" SG_ 734 ACU_CurrTUDRService2_St 1;
BA_ "U_V713N_MY2022_Rx" SG_ 734 ACU_CurrTUDRService2_St 1;
BA_ "GenSigSendType" SG_ 734 ACU_CurrTUDRService2_St 3;
BA_ "U_V710_MY2023_Tx" SG_ 734 ACU_ComTUSIDValid_St 1;
BA_ "U_P708_MY2023_Tx" SG_ 734 ACU_ComTUSIDValid_St 1;
BA_ "U_V713AV_MY2022_Tx" SG_ 734 ACU_ComTUSIDValid_St 1;
BA_ "U_V713N_MY2022_Tx" SG_ 734 ACU_ComTUSIDValid_St 1;
BA_ "GenSigSendType" SG_ 734 ACU_ComTUSIDValid_St 3;
BA_ "U_V710_MY2023_Tx" SG_ 734 ACU_CurrTUDABBlock_St 1;
BA_ "U_P708_MY2023_Tx" SG_ 734 ACU_CurrTUDABBlock_St 1;
BA_ "U_V713AV_MY2022_Tx" SG_ 734 ACU_CurrTUDABBlock_St 1;
BA_ "U_V713N_MY2022_Tx" SG_ 734 ACU_CurrTUDABBlock_St 1;
BA_ "U_P708_MY2023_Rx" SG_ 734 ACU_CurrTUDABBlock_St 1;
BA_ "U_V713AV_MY2022_Rx" SG_ 734 ACU_CurrTUDABBlock_St 1;
BA_ "U_V713N_MY2022_Rx" SG_ 734 ACU_CurrTUDABBlock_St 1;
BA_ "GenSigSendType" SG_ 734 ACU_CurrTUDABBlock_St 3;
BA_ "U_V710_MY2023_Tx" SG_ 734 ACU_CurrTUDRService_St 1;
BA_ "U_P708_MY2023_Tx" SG_ 734 ACU_CurrTUDRService_St 1;
BA_ "U_V713AV_MY2022_Tx" SG_ 734 ACU_CurrTUDRService_St 1;
BA_ "U_V713N_MY2022_Tx" SG_ 734 ACU_CurrTUDRService_St 1;
BA_ "GenSigSendType" SG_ 734 ACU_CurrTUDRService_St 3;
BA_ "U_V710_MY2023_Tx" SG_ 734 ACU_CurrTURadioBand_St 1;
BA_ "U_P708_MY2023_Tx" SG_ 734 ACU_CurrTURadioBand_St 1;
BA_ "U_V713AV_MY2022_Tx" SG_ 734 ACU_CurrTURadioBand_St 1;
BA_ "U_V713N_MY2022_Tx" SG_ 734 ACU_CurrTURadioBand_St 1;
BA_ "GenSigSendType" SG_ 734 ACU_CurrTURadioBand_St 3;
BA_ "U_V710_MY2023_Tx" SG_ 734 ACU_CurrTUSCIDI_St 1;
BA_ "U_P708_MY2023_Tx" SG_ 734 ACU_CurrTUSCIDI_St 1;
BA_ "U_V713AV_MY2022_Tx" SG_ 734 ACU_CurrTUSCIDI_St 1;
BA_ "U_V713N_MY2022_Tx" SG_ 734 ACU_CurrTUSCIDI_St 1;
BA_ "U_V710_MY2023_Tx" SG_ 734 ACU_CurrTUServiceLink_St 1;
BA_ "U_P708_MY2023_Tx" SG_ 734 ACU_CurrTUServiceLink_St 1;
BA_ "U_V713AV_MY2022_Tx" SG_ 734 ACU_CurrTUServiceLink_St 1;
BA_ "U_V713N_MY2022_Tx" SG_ 734 ACU_CurrTUServiceLink_St 1;
BA_ "GenSigSendType" SG_ 734 ACU_CurrTUServiceLink_St 3;
BA_ "U_V710_MY2023_Tx" SG_ 734 ACU_CurrTUSID_St 1;
BA_ "U_P708_MY2023_Tx" SG_ 734 ACU_CurrTUSID_St 1;
BA_ "U_V713AV_MY2022_Tx" SG_ 734 ACU_CurrTUSID_St 1;
BA_ "U_V713N_MY2022_Tx" SG_ 734 ACU_CurrTUSID_St 1;
BA_ "U_V710_MY2023_Tx" SG_ 1420 ACM_GWOnBoardTester 1;
BA_ "U_P708_MY2023_Tx" SG_ 1420 ACM_GWOnBoardTester 1;
BA_ "U_V713AV_MY2022_Tx" SG_ 1420 ACM_GWOnBoardTester 1;
BA_ "U_V713N_MY2022_Tx" SG_ 1420 ACM_GWOnBoardTester 1;
BA_ "U_V710_MY2023_Rx" SG_ 1420 ACM_GWOnBoardTester 1;
BA_ "GenSigStartValue" SG_ 1420 ACM_GWOnBoardTester 255;
BA_ "U_V710_MY2023_Tx" SG_ 1420 ACM_GWNMProxy 1;
BA_ "U_P708_MY2023_Tx" SG_ 1420 ACM_GWNMProxy 1;
BA_ "U_V713AV_MY2022_Tx" SG_ 1420 ACM_GWNMProxy 1;
BA_ "U_V713N_MY2022_Tx" SG_ 1420 ACM_GWNMProxy 1;
BA_ "U_V710_MY2023_Rx" SG_ 1420 ACM_GWNMProxy 1;
BA_ "GenSigStartValue" SG_ 1420 ACM_GWNMProxy 255;
BA_ "U_V710_MY2023_Tx" SG_ 1420 ACM_AutoSarNMReserved4 1;
BA_ "U_P708_MY2023_Tx" SG_ 1420 ACM_AutoSarNMReserved4 1;
BA_ "U_V713AV_MY2022_Tx" SG_ 1420 ACM_AutoSarNMReserved4 1;
BA_ "U_V713N_MY2022_Tx" SG_ 1420 ACM_AutoSarNMReserved4 1;
BA_ "U_V710_MY2023_Rx" SG_ 1420 ACM_AutoSarNMReserved4 1;
BA_ "GenSigStartValue" SG_ 1420 ACM_AutoSarNMReserved4 255;
BA_ "U_V710_MY2023_Tx" SG_ 1420 ACM_AutoSarNMReserved3 1;
BA_ "U_P708_MY2023_Tx" SG_ 1420 ACM_AutoSarNMReserved3 1;
BA_ "U_V713AV_MY2022_Tx" SG_ 1420 ACM_AutoSarNMReserved3 1;
BA_ "U_V713N_MY2022_Tx" SG_ 1420 ACM_AutoSarNMReserved3 1;
BA_ "U_V710_MY2023_Rx" SG_ 1420 ACM_AutoSarNMReserved3 1;
BA_ "GenSigStartValue" SG_ 1420 ACM_AutoSarNMReserved3 255;
BA_ "U_V710_MY2023_Tx" SG_ 1420 ACM_AutoSarNMReserved2 1;
BA_ "U_P708_MY2023_Tx" SG_ 1420 ACM_AutoSarNMReserved2 1;
BA_ "U_V713AV_MY2022_Tx" SG_ 1420 ACM_AutoSarNMReserved2 1;
BA_ "U_V713N_MY2022_Tx" SG_ 1420 ACM_AutoSarNMReserved2 1;
BA_ "U_V710_MY2023_Rx" SG_ 1420 ACM_AutoSarNMReserved2 1;
BA_ "GenSigStartValue" SG_ 1420 ACM_AutoSarNMReserved2 255;
BA_ "U_V710_MY2023_Tx" SG_ 1420 ACM_AutoSarNMReserved1 1;
BA_ "U_P708_MY2023_Tx" SG_ 1420 ACM_AutoSarNMReserved1 1;
BA_ "U_V713AV_MY2022_Tx" SG_ 1420 ACM_AutoSarNMReserved1 1;
BA_ "U_V713N_MY2022_Tx" SG_ 1420 ACM_AutoSarNMReserved1 1;
BA_ "U_V710_MY2023_Rx" SG_ 1420 ACM_AutoSarNMReserved1 1;
BA_ "GenSigStartValue" SG_ 1420 ACM_AutoSarNMReserved1 255;
BA_ "U_V710_MY2023_Tx" SG_ 1420 ACM_AutoSarNMNodeId 1;
BA_ "U_P708_MY2023_Tx" SG_ 1420 ACM_AutoSarNMNodeId 1;
BA_ "U_V713AV_MY2022_Tx" SG_ 1420 ACM_AutoSarNMNodeId 1;
BA_ "U_V713N_MY2022_Tx" SG_ 1420 ACM_AutoSarNMNodeId 1;
BA_ "U_V710_MY2023_Rx" SG_ 1420 ACM_AutoSarNMNodeId 1;
BA_ "GenSigStartValue" SG_ 1420 ACM_AutoSarNMNodeId 140;
BA_ "U_V710_MY2023_Tx" SG_ 1420 ACM_AutoSarNMControl 1;
BA_ "U_P708_MY2023_Tx" SG_ 1420 ACM_AutoSarNMControl 1;
BA_ "U_V713AV_MY2022_Tx" SG_ 1420 ACM_AutoSarNMControl 1;
BA_ "U_V713N_MY2022_Tx" SG_ 1420 ACM_AutoSarNMControl 1;
BA_ "U_V710_MY2023_Rx" SG_ 1420 ACM_AutoSarNMControl 1;
BA_ "U_V710_MY2023_Tx" SG_ 759 Avail_HD_Chan_Valid 1;
BA_ "U_P708_MY2023_Tx" SG_ 759 Avail_HD_Chan_Valid 1;
BA_ "U_V713AV_MY2022_Tx" SG_ 759 Avail_HD_Chan_Valid 1;
BA_ "U_V713N_MY2022_Tx" SG_ 759 Avail_HD_Chan_Valid 1;
BA_ "GenSigSendType" SG_ 759 Avail_HD_Chan_Valid 3;
BA_ "U_V710_MY2023_Tx" SG_ 759 Avail_HD_Chan_St_7 1;
BA_ "U_P708_MY2023_Tx" SG_ 759 Avail_HD_Chan_St_7 1;
BA_ "U_V713AV_MY2022_Tx" SG_ 759 Avail_HD_Chan_St_7 1;
BA_ "U_V713N_MY2022_Tx" SG_ 759 Avail_HD_Chan_St_7 1;
BA_ "GenSigSendType" SG_ 759 Avail_HD_Chan_St_7 3;
BA_ "U_V710_MY2023_Tx" SG_ 759 Avail_HD_Chan_St_6 1;
BA_ "U_P708_MY2023_Tx" SG_ 759 Avail_HD_Chan_St_6 1;
BA_ "U_V713AV_MY2022_Tx" SG_ 759 Avail_HD_Chan_St_6 1;
BA_ "U_V713N_MY2022_Tx" SG_ 759 Avail_HD_Chan_St_6 1;
BA_ "GenSigSendType" SG_ 759 Avail_HD_Chan_St_6 3;
BA_ "U_V710_MY2023_Tx" SG_ 759 Avail_HD_Chan_St_5 1;
BA_ "U_P708_MY2023_Tx" SG_ 759 Avail_HD_Chan_St_5 1;
BA_ "U_V713AV_MY2022_Tx" SG_ 759 Avail_HD_Chan_St_5 1;
BA_ "U_V713N_MY2022_Tx" SG_ 759 Avail_HD_Chan_St_5 1;
BA_ "GenSigSendType" SG_ 759 Avail_HD_Chan_St_5 3;
BA_ "U_V710_MY2023_Tx" SG_ 759 Avail_HD_Chan_St_4 1;
BA_ "U_P708_MY2023_Tx" SG_ 759 Avail_HD_Chan_St_4 1;
BA_ "U_V713AV_MY2022_Tx" SG_ 759 Avail_HD_Chan_St_4 1;
BA_ "U_V713N_MY2022_Tx" SG_ 759 Avail_HD_Chan_St_4 1;
BA_ "GenSigSendType" SG_ 759 Avail_HD_Chan_St_4 3;
BA_ "U_V710_MY2023_Tx" SG_ 759 Avail_HD_Chan_St_3 1;
BA_ "U_P708_MY2023_Tx" SG_ 759 Avail_HD_Chan_St_3 1;
BA_ "U_V713AV_MY2022_Tx" SG_ 759 Avail_HD_Chan_St_3 1;
BA_ "U_V713N_MY2022_Tx" SG_ 759 Avail_HD_Chan_St_3 1;
BA_ "GenSigSendType" SG_ 759 Avail_HD_Chan_St_3 3;
BA_ "U_V710_MY2023_Tx" SG_ 759 Avail_HD_Chan_St_2 1;
BA_ "U_P708_MY2023_Tx" SG_ 759 Avail_HD_Chan_St_2 1;
BA_ "U_V713AV_MY2022_Tx" SG_ 759 Avail_HD_Chan_St_2 1;
BA_ "U_V713N_MY2022_Tx" SG_ 759 Avail_HD_Chan_St_2 1;
BA_ "GenSigSendType" SG_ 759 Avail_HD_Chan_St_2 3;
BA_ "U_V710_MY2023_Tx" SG_ 759 Avail_HD_Chan_St_1 1;
BA_ "U_P708_MY2023_Tx" SG_ 759 Avail_HD_Chan_St_1 1;
BA_ "U_V713AV_MY2022_Tx" SG_ 759 Avail_HD_Chan_St_1 1;
BA_ "U_V713N_MY2022_Tx" SG_ 759 Avail_HD_Chan_St_1 1;
BA_ "GenSigSendType" SG_ 759 Avail_HD_Chan_St_1 3;
BA_ "U_V710_MY2023_Tx" SG_ 759 ACM_StationListScanSt 1;
BA_ "U_P708_MY2023_Tx" SG_ 759 ACM_StationListScanSt 1;
BA_ "U_V713AV_MY2022_Tx" SG_ 759 ACM_StationListScanSt 1;
BA_ "U_V713N_MY2022_Tx" SG_ 759 ACM_StationListScanSt 1;
BA_ "U_V713AV_MY2022_Rx" SG_ 759 ACM_StationListScanSt 1;
BA_ "U_V713N_MY2022_Rx" SG_ 759 ACM_StationListScanSt 1;
BA_ "GenSigSendType" SG_ 759 ACM_StationListScanSt 3;
BA_ "U_V710_MY2023_Tx" SG_ 759 ACM_TagMode 1;
BA_ "U_P708_MY2023_Tx" SG_ 759 ACM_TagMode 1;
BA_ "U_V713AV_MY2022_Tx" SG_ 759 ACM_TagMode 1;
BA_ "U_V713N_MY2022_Tx" SG_ 759 ACM_TagMode 1;
BA_ "U_V713AV_MY2022_Rx" SG_ 759 ACM_TagMode 1;
BA_ "U_V713N_MY2022_Rx" SG_ 759 ACM_TagMode 1;
BA_ "GenSigSendType" SG_ 759 ACM_TagMode 3;
BA_ "U_V710_MY2023_Tx" SG_ 759 ACM_RBDSMode 1;
BA_ "U_P708_MY2023_Tx" SG_ 759 ACM_RBDSMode 1;
BA_ "U_V713AV_MY2022_Tx" SG_ 759 ACM_RBDSMode 1;
BA_ "U_V713N_MY2022_Tx" SG_ 759 ACM_RBDSMode 1;
BA_ "U_V713AV_MY2022_Rx" SG_ 759 ACM_RBDSMode 1;
BA_ "U_V713N_MY2022_Rx" SG_ 759 ACM_RBDSMode 1;
BA_ "GenSigSendType" SG_ 759 ACM_RBDSMode 3;
BA_ "U_V710_MY2023_Tx" SG_ 759 NumofHDMulticastChans_St 1;
BA_ "U_P708_MY2023_Tx" SG_ 759 NumofHDMulticastChans_St 1;
BA_ "U_V713AV_MY2022_Tx" SG_ 759 NumofHDMulticastChans_St 1;
BA_ "U_V713N_MY2022_Tx" SG_ 759 NumofHDMulticastChans_St 1;
BA_ "U_V713AV_MY2022_Rx" SG_ 759 NumofHDMulticastChans_St 1;
BA_ "U_V713N_MY2022_Rx" SG_ 759 NumofHDMulticastChans_St 1;
BA_ "GenSigSendType" SG_ 759 NumofHDMulticastChans_St 3;
BA_ "U_V710_MY2023_Tx" SG_ 759 ACM_HDModeStatus 1;
BA_ "U_P708_MY2023_Tx" SG_ 759 ACM_HDModeStatus 1;
BA_ "U_V713AV_MY2022_Tx" SG_ 759 ACM_HDModeStatus 1;
BA_ "U_V713N_MY2022_Tx" SG_ 759 ACM_HDModeStatus 1;
BA_ "U_V713AV_MY2022_Rx" SG_ 759 ACM_HDModeStatus 1;
BA_ "U_V713N_MY2022_Rx" SG_ 759 ACM_HDModeStatus 1;
BA_ "GenSigSendType" SG_ 759 ACM_HDModeStatus 3;
BA_ "U_V710_MY2023_Tx" SG_ 759 ACM_HDChanStatus 1;
BA_ "U_P708_MY2023_Tx" SG_ 759 ACM_HDChanStatus 1;
BA_ "U_V713AV_MY2022_Tx" SG_ 759 ACM_HDChanStatus 1;
BA_ "U_V713N_MY2022_Tx" SG_ 759 ACM_HDChanStatus 1;
BA_ "U_P708_MY2023_Rx" SG_ 759 ACM_HDChanStatus 1;
BA_ "U_V713AV_MY2022_Rx" SG_ 759 ACM_HDChanStatus 1;
BA_ "U_V713N_MY2022_Rx" SG_ 759 ACM_HDChanStatus 1;
BA_ "GenSigSendType" SG_ 759 ACM_HDChanStatus 3;
BA_ "U_V710_MY2023_Tx" SG_ 759 ACM_CurrentSSName 1;
BA_ "U_P708_MY2023_Tx" SG_ 759 ACM_CurrentSSName 1;
BA_ "U_V713AV_MY2022_Tx" SG_ 759 ACM_CurrentSSName 1;
BA_ "U_V713N_MY2022_Tx" SG_ 759 ACM_CurrentSSName 1;
BA_ "U_P708_MY2023_Rx" SG_ 759 ACM_CurrentSSName 1;
BA_ "U_V713AV_MY2022_Rx" SG_ 759 ACM_CurrentSSName 1;
BA_ "U_V713N_MY2022_Rx" SG_ 759 ACM_CurrentSSName 1;
BA_ "GenSigSendType" SG_ 759 ACM_CurrentSSName 3;
BA_ "U_V710_MY2023_Tx" SG_ 759 ACM_CurrentHDMulticast_St 1;
BA_ "U_P708_MY2023_Tx" SG_ 759 ACM_CurrentHDMulticast_St 1;
BA_ "U_V713AV_MY2022_Tx" SG_ 759 ACM_CurrentHDMulticast_St 1;
BA_ "U_V713N_MY2022_Tx" SG_ 759 ACM_CurrentHDMulticast_St 1;
BA_ "U_V713AV_MY2022_Rx" SG_ 759 ACM_CurrentHDMulticast_St 1;
BA_ "U_V713N_MY2022_Rx" SG_ 759 ACM_CurrentHDMulticast_St 1;
BA_ "GenSigSendType" SG_ 759 ACM_CurrentHDMulticast_St 3;
BA_ "GenSigSendType" SG_ 1960 TesterPhysicalResFCIMB 3;
BA_ "GenSigSendType" SG_ 1952 TesterPhysicalReqFCIMB 3;
BA_ "U_V710_MY2023_Rx" SG_ 144 SetTimeFormat 1;
BA_ "GenSigSendType" SG_ 144 SetTimeFormat 3;
BA_ "GenSigSendType" SG_ 144 TimeAdjustRequest 3;
BA_ "U_V713N_MY2022_Rx" SG_ 144 DateAdjustRequest 1;
BA_ "GenSigSendType" SG_ 144 DateAdjustRequest 3;
BA_ "U_V710_MY2023_Tx" SG_ 851 ConsLongTerm_No_Dsply 1;
BA_ "U_P708_MY2023_Tx" SG_ 851 ConsLongTerm_No_Dsply 1;
BA_ "U_V713AV_MY2022_Tx" SG_ 851 ConsLongTerm_No_Dsply 1;
BA_ "U_V713N_MY2022_Tx" SG_ 851 ConsLongTerm_No_Dsply 1;
BA_ "U_V710_MY2023_Rx" SG_ 851 ConsLongTerm_No_Dsply 1;
BA_ "U_P708_MY2023_Rx" SG_ 851 ConsLongTerm_No_Dsply 1;
BA_ "U_V713AV_MY2022_Rx" SG_ 851 ConsLongTerm_No_Dsply 1;
BA_ "U_V713N_MY2022_Rx" SG_ 851 ConsLongTerm_No_Dsply 1;
BA_ "ECGUsedRxSignal" SG_ 851 ConsLongTerm_No_Dsply 1;
BA_ "U_V710_MY2023_Tx" SG_ 851 ConsUnitIPC_D_Dsply 1;
BA_ "U_P708_MY2023_Tx" SG_ 851 ConsUnitIPC_D_Dsply 1;
BA_ "U_V713AV_MY2022_Tx" SG_ 851 ConsUnitIPC_D_Dsply 1;
BA_ "U_V713N_MY2022_Tx" SG_ 851 ConsUnitIPC_D_Dsply 1;
BA_ "U_V710_MY2023_Rx" SG_ 851 ConsUnitIPC_D_Dsply 1;
BA_ "U_P708_MY2023_Rx" SG_ 851 ConsUnitIPC_D_Dsply 1;
BA_ "U_V713AV_MY2022_Rx" SG_ 851 ConsUnitIPC_D_Dsply 1;
BA_ "U_V713N_MY2022_Rx" SG_ 851 ConsUnitIPC_D_Dsply 1;
BA_ "ECGUsedRxSignal" SG_ 851 ConsUnitIPC_D_Dsply 1;
BA_ "GenSigSendType" SG_ 851 ConsUnitIPC_D_Dsply 3;
BA_ "U_V710_MY2023_Tx" SG_ 851 ConsAvgTrip_No_Dsply 1;
BA_ "U_P708_MY2023_Tx" SG_ 851 ConsAvgTrip_No_Dsply 1;
BA_ "U_V713AV_MY2022_Tx" SG_ 851 ConsAvgTrip_No_Dsply 1;
BA_ "U_V713N_MY2022_Tx" SG_ 851 ConsAvgTrip_No_Dsply 1;
BA_ "U_V710_MY2023_Rx" SG_ 851 ConsAvgTrip_No_Dsply 1;
BA_ "U_P708_MY2023_Rx" SG_ 851 ConsAvgTrip_No_Dsply 1;
BA_ "U_V713AV_MY2022_Rx" SG_ 851 ConsAvgTrip_No_Dsply 1;
BA_ "U_V713N_MY2022_Rx" SG_ 851 ConsAvgTrip_No_Dsply 1;
BA_ "ECGUsedRxSignal" SG_ 851 ConsAvgTrip_No_Dsply 1;
BA_ "U_V710_MY2023_Tx" SG_ 792 FuelRange_L_Dsply 1;
BA_ "U_P708_MY2023_Tx" SG_ 792 FuelRange_L_Dsply 1;
BA_ "U_V713AV_MY2022_Tx" SG_ 792 FuelRange_L_Dsply 1;
BA_ "U_V713N_MY2022_Tx" SG_ 792 FuelRange_L_Dsply 1;
BA_ "ECGUsedRxSignal" SG_ 792 FuelRange_L_Dsply 1;
BA_ "U_V710_MY2023_Rx" SG_ 792 FuelRange_L_Dsply 1;
BA_ "U_P708_MY2023_Rx" SG_ 792 FuelRange_L_Dsply 1;
BA_ "U_V713AV_MY2022_Rx" SG_ 792 FuelRange_L_Dsply 1;
BA_ "U_V713N_MY2022_Rx" SG_ 792 FuelRange_L_Dsply 1;
BA_ "U_V710_MY2023_Tx" SG_ 792 ElTrip_L_Dsply 1;
BA_ "U_P708_MY2023_Tx" SG_ 792 ElTrip_L_Dsply 1;
BA_ "U_V713AV_MY2022_Tx" SG_ 792 ElTrip_L_Dsply 1;
BA_ "U_V713N_MY2022_Tx" SG_ 792 ElTrip_L_Dsply 1;
BA_ "U_V710_MY2023_Rx" SG_ 792 ElTrip_L_Dsply 1;
BA_ "U_P708_MY2023_Rx" SG_ 792 ElTrip_L_Dsply 1;
BA_ "U_V713AV_MY2022_Rx" SG_ 792 ElTrip_L_Dsply 1;
BA_ "U_V713N_MY2022_Rx" SG_ 792 ElTrip_L_Dsply 1;
BA_ "ECGUsedRxSignal" SG_ 792 ElTrip_L_Dsply 1;
BA_ "U_V710_MY2023_Tx" SG_ 792 ElLongTerm_L_Dsply 1;
BA_ "U_P708_MY2023_Tx" SG_ 792 ElLongTerm_L_Dsply 1;
BA_ "U_V713AV_MY2022_Tx" SG_ 792 ElLongTerm_L_Dsply 1;
BA_ "U_V713N_MY2022_Tx" SG_ 792 ElLongTerm_L_Dsply 1;
BA_ "U_V710_MY2023_Rx" SG_ 792 ElLongTerm_L_Dsply 1;
BA_ "U_P708_MY2023_Rx" SG_ 792 ElLongTerm_L_Dsply 1;
BA_ "U_V713AV_MY2022_Rx" SG_ 792 ElLongTerm_L_Dsply 1;
BA_ "U_V713N_MY2022_Rx" SG_ 792 ElLongTerm_L_Dsply 1;
BA_ "ECGUsedRxSignal" SG_ 792 ElLongTerm_L_Dsply 1;
BA_ "U_V710_MY2023_Tx" SG_ 792 DsplyChkActv_B_Stat 1;
BA_ "U_P708_MY2023_Tx" SG_ 792 DsplyChkActv_B_Stat 1;
BA_ "U_V710_MY2023_Rx" SG_ 792 DsplyChkActv_B_Stat 1;
BA_ "U_P708_MY2023_Rx" SG_ 792 DsplyChkActv_B_Stat 1;
BA_ "ECGUsedRxSignal" SG_ 792 DsplyChkActv_B_Stat 1;
BA_ "U_P708_MY2023_Tx" SG_ 789 VehElSurpStat_L_Dsply 1;
BA_ "U_V713AV_MY2022_Tx" SG_ 789 VehElSurpStat_L_Dsply 1;
BA_ "U_V713N_MY2022_Tx" SG_ 789 VehElSurpStat_L_Dsply 1;
BA_ "U_P708_MY2023_Tx" SG_ 789 TripSum_Vl_Dsply 1;
BA_ "U_V713AV_MY2022_Tx" SG_ 789 TripSum_Vl_Dsply 1;
BA_ "U_V713N_MY2022_Tx" SG_ 789 TripSum_Vl_Dsply 1;
BA_ "U_V710_MY2023_Rx" SG_ 789 TripSum_Vl_Dsply 1;
BA_ "U_P708_MY2023_Rx" SG_ 789 TripSum_Vl_Dsply 1;
BA_ "U_V713AV_MY2022_Rx" SG_ 789 TripSum_Vl_Dsply 1;
BA_ "U_V713N_MY2022_Rx" SG_ 789 TripSum_Vl_Dsply 1;
BA_ "ECGUsedRxSignal" SG_ 789 TripSum_Vl_Dsply 1;
BA_ "U_P708_MY2023_Tx" SG_ 789 TripSum_E_Dsply 1;
BA_ "U_V713AV_MY2022_Tx" SG_ 789 TripSum_E_Dsply 1;
BA_ "U_V713N_MY2022_Tx" SG_ 789 TripSum_E_Dsply 1;
BA_ "U_V710_MY2023_Rx" SG_ 789 TripSum_E_Dsply 1;
BA_ "U_P708_MY2023_Rx" SG_ 789 TripSum_E_Dsply 1;
BA_ "U_V713AV_MY2022_Rx" SG_ 789 TripSum_E_Dsply 1;
BA_ "U_V713N_MY2022_Rx" SG_ 789 TripSum_E_Dsply 1;
BA_ "ECGUsedRxSignal" SG_ 789 TripSum_E_Dsply 1;
BA_ "U_V710_MY2023_Tx" SG_ 789 TripSum_L_Dsply 1;
BA_ "U_P708_MY2023_Tx" SG_ 789 TripSum_L_Dsply 1;
BA_ "U_V713AV_MY2022_Tx" SG_ 789 TripSum_L_Dsply 1;
BA_ "U_V713N_MY2022_Tx" SG_ 789 TripSum_L_Dsply 1;
BA_ "U_V710_MY2023_Rx" SG_ 789 TripSum_L_Dsply 1;
BA_ "U_P708_MY2023_Rx" SG_ 789 TripSum_L_Dsply 1;
BA_ "U_V713AV_MY2022_Rx" SG_ 789 TripSum_L_Dsply 1;
BA_ "U_V713N_MY2022_Rx" SG_ 789 TripSum_L_Dsply 1;
BA_ "ECGUsedRxSignal" SG_ 789 TripSum_L_Dsply 1;
BA_ "U_P708_MY2023_Tx" SG_ 697 AUDIO_MC_WORD_Rx 1;
BA_ "U_V713AV_MY2022_Tx" SG_ 697 AUDIO_MC_WORD_Rx 1;
BA_ "U_V713N_MY2022_Tx" SG_ 697 AUDIO_MC_WORD_Rx 1;
BA_ "U_V710_MY2023_Rx" SG_ 697 AUDIO_MC_WORD_Rx 1;
BA_ "U_P708_MY2023_Rx" SG_ 697 AUDIO_MC_WORD_Rx 1;
BA_ "U_V713AV_MY2022_Rx" SG_ 697 AUDIO_MC_WORD_Rx 1;
BA_ "U_V713N_MY2022_Rx" SG_ 697 AUDIO_MC_WORD_Rx 1;
BA_ "U_V710_MY2023_Rx" SG_ 700 AUDIO_RDISP_WORD_Rx 1;
BA_ "U_P708_MY2023_Rx" SG_ 700 AUDIO_RDISP_WORD_Rx 1;
BA_ "U_V713AV_MY2022_Rx" SG_ 700 AUDIO_RDISP_WORD_Rx 1;
BA_ "U_V713N_MY2022_Rx" SG_ 700 AUDIO_RDISP_WORD_Rx 1;
BA_ "GenSigStartValue" SG_ 126 StePinRelInit_An_Sns 65535;
BA_ "U_P708_MY2023_Rx" SG_ 126 StePinCompAnEst_D_Qf 1;
BA_ "U_V713AV_MY2022_Rx" SG_ 126 StePinCompAnEst_D_Qf 1;
BA_ "U_V713N_MY2022_Rx" SG_ 126 StePinCompAnEst_D_Qf 1;
BA_ "GenSigStartValue" SG_ 126 StePinCompAnEst_D_Qf 1;
BA_ "MetaData" SG_ 126 StePinCompAnEst_D_Qf 1;
BA_ "U_P708_MY2023_Rx" SG_ 126 StePinComp_An_Est 1;
BA_ "U_V713AV_MY2022_Rx" SG_ 126 StePinComp_An_Est 1;
BA_ "U_V713N_MY2022_Rx" SG_ 126 StePinComp_An_Est 1;
BA_ "MetaData" SG_ 126 StePinAn_No_Cs 1;
BA_ "MetaData" SG_ 126 StePinAn_No_Cnt 1;
BA_ "U_P708_MY2023_Rx" SG_ 806 SnowPlowMde_B_Enbl 1;
BA_ "U_P708_MY2023_Tx" SG_ 676 MC_RDISP_WORD_Tx 1;
BA_ "U_V713AV_MY2022_Tx" SG_ 676 MC_RDISP_WORD_Tx 1;
BA_ "U_V713N_MY2022_Tx" SG_ 676 MC_RDISP_WORD_Tx 1;
BA_ "U_V710_MY2023_Rx" SG_ 504 Mc_AudioSourceSel_Rq 1;
BA_ "U_P708_MY2023_Rx" SG_ 504 Mc_AudioSourceSel_Rq 1;
BA_ "U_V713AV_MY2022_Rx" SG_ 504 Mc_AudioSourceSel_Rq 1;
BA_ "U_V713N_MY2022_Rx" SG_ 504 Mc_AudioSourceSel_Rq 1;
BA_ "GenSigSendType" SG_ 504 Mc_AudioSourceSel_Rq 3;
BA_ "U_V710_MY2023_Rx" SG_ 504 Mc_FolderNumber_Rq 1;
BA_ "U_P708_MY2023_Rx" SG_ 504 Mc_FolderNumber_Rq 1;
BA_ "U_V713AV_MY2022_Rx" SG_ 504 Mc_FolderNumber_Rq 1;
BA_ "U_V713N_MY2022_Rx" SG_ 504 Mc_FolderNumber_Rq 1;
BA_ "U_V710_MY2023_Rx" SG_ 504 Mc_CutItem_Rq 1;
BA_ "U_P708_MY2023_Rx" SG_ 504 Mc_CutItem_Rq 1;
BA_ "U_V713AV_MY2022_Rx" SG_ 504 Mc_CutItem_Rq 1;
BA_ "U_V713N_MY2022_Rx" SG_ 504 Mc_CutItem_Rq 1;
BA_ "U_V710_MY2023_Rx" SG_ 504 Mc_ItemNameLength_Rq 1;
BA_ "U_P708_MY2023_Rx" SG_ 504 Mc_ItemNameLength_Rq 1;
BA_ "U_V713AV_MY2022_Rx" SG_ 504 Mc_ItemNameLength_Rq 1;
BA_ "U_V713N_MY2022_Rx" SG_ 504 Mc_ItemNameLength_Rq 1;
BA_ "U_V710_MY2023_Rx" SG_ 504 Mc_SourceSetTrack_Rq 1;
BA_ "U_P708_MY2023_Rx" SG_ 504 Mc_SourceSetTrack_Rq 1;
BA_ "U_V713AV_MY2022_Rx" SG_ 504 Mc_SourceSetTrack_Rq 1;
BA_ "U_V713N_MY2022_Rx" SG_ 504 Mc_SourceSetTrack_Rq 1;
BA_ "U_V710_MY2023_Tx" SG_ 410 MyKey_e911Override_St 1;
BA_ "U_P708_MY2023_Tx" SG_ 410 MyKey_e911Override_St 1;
BA_ "U_V713AV_MY2022_Tx" SG_ 410 MyKey_e911Override_St 1;
BA_ "U_V713N_MY2022_Tx" SG_ 410 MyKey_e911Override_St 1;
BA_ "GenSigSendType" SG_ 410 MyKey_e911Override_St 3;
BA_ "U_V710_MY2023_Tx" SG_ 410 DoNotDisturbOveride_St 1;
BA_ "U_P708_MY2023_Tx" SG_ 410 DoNotDisturbOveride_St 1;
BA_ "U_V713AV_MY2022_Tx" SG_ 410 DoNotDisturbOveride_St 1;
BA_ "U_V713N_MY2022_Tx" SG_ 410 DoNotDisturbOveride_St 1;
BA_ "GenSigSendType" SG_ 410 DoNotDisturbOveride_St 3;
BA_ "GenSigSendType" SG_ 1124 GPS_Vdop 1;
BA_ "U_V710_MY2023_Rx" SG_ 1124 GPS_Speed 1;
BA_ "U_P708_MY2023_Rx" SG_ 1124 GPS_Speed 1;
BA_ "U_V713AV_MY2022_Rx" SG_ 1124 GPS_Speed 1;
BA_ "U_V713N_MY2022_Rx" SG_ 1124 GPS_Speed 1;
BA_ "ECGUsedRxSignal" SG_ 1124 GPS_Speed 1;
BA_ "U_V710_MY2023_Rx" SG_ 1124 GPS_MSL_altitude 1;
BA_ "U_P708_MY2023_Rx" SG_ 1124 GPS_MSL_altitude 1;
BA_ "U_V713AV_MY2022_Rx" SG_ 1124 GPS_MSL_altitude 1;
BA_ "U_V713N_MY2022_Rx" SG_ 1124 GPS_MSL_altitude 1;
BA_ "ECGUsedRxSignal" SG_ 1124 GPS_MSL_altitude 1;
BA_ "U_V710_MY2023_Rx" SG_ 1124 GPS_Heading 1;
BA_ "U_P708_MY2023_Rx" SG_ 1124 GPS_Heading 1;
BA_ "U_V713AV_MY2022_Rx" SG_ 1124 GPS_Heading 1;
BA_ "U_V713N_MY2022_Rx" SG_ 1124 GPS_Heading 1;
BA_ "ECGUsedRxSignal" SG_ 1124 GPS_Heading 1;
BA_ "U_V710_MY2023_Rx" SG_ 1124 GPS_dimension 1;
BA_ "U_P708_MY2023_Rx" SG_ 1124 GPS_dimension 1;
BA_ "U_V713AV_MY2022_Rx" SG_ 1124 GPS_dimension 1;
BA_ "U_V713N_MY2022_Rx" SG_ 1124 GPS_dimension 1;
BA_ "ECGUsedRxSignal" SG_ 1124 GPS_dimension 1;
BA_ "U_V710_MY2023_Rx" SG_ 1123 GpsUtcYr_No_Actl 1;
BA_ "U_P708_MY2023_Rx" SG_ 1123 GpsUtcYr_No_Actl 1;
BA_ "U_V713AV_MY2022_Rx" SG_ 1123 GpsUtcYr_No_Actl 1;
BA_ "U_V713N_MY2022_Rx" SG_ 1123 GpsUtcYr_No_Actl 1;
BA_ "ECGUsedRxSignal" SG_ 1123 GpsUtcYr_No_Actl 1;
BA_ "U_V710_MY2023_Rx" SG_ 1123 GpsUtcMnth_No_Actl 1;
BA_ "U_P708_MY2023_Rx" SG_ 1123 GpsUtcMnth_No_Actl 1;
BA_ "U_V713AV_MY2022_Rx" SG_ 1123 GpsUtcMnth_No_Actl 1;
BA_ "U_V713N_MY2022_Rx" SG_ 1123 GpsUtcMnth_No_Actl 1;
BA_ "ECGUsedRxSignal" SG_ 1123 GpsUtcMnth_No_Actl 1;
BA_ "GenSigStartValue" SG_ 1123 GpsUtcMnth_No_Actl 1;
BA_ "U_V710_MY2023_Rx" SG_ 1123 GpsUtcDay_No_Actl 1;
BA_ "U_P708_MY2023_Rx" SG_ 1123 GpsUtcDay_No_Actl 1;
BA_ "U_V713AV_MY2022_Rx" SG_ 1123 GpsUtcDay_No_Actl 1;
BA_ "U_V713N_MY2022_Rx" SG_ 1123 GpsUtcDay_No_Actl 1;
BA_ "ECGUsedRxSignal" SG_ 1123 GpsUtcDay_No_Actl 1;
BA_ "GenSigStartValue" SG_ 1123 GpsUtcDay_No_Actl 1;
BA_ "U_V710_MY2023_Rx" SG_ 1123 GPS_UTC_seconds 1;
BA_ "U_P708_MY2023_Rx" SG_ 1123 GPS_UTC_seconds 1;
BA_ "U_V713AV_MY2022_Rx" SG_ 1123 GPS_UTC_seconds 1;
BA_ "U_V713N_MY2022_Rx" SG_ 1123 GPS_UTC_seconds 1;
BA_ "ECGUsedRxSignal" SG_ 1123 GPS_UTC_seconds 1;
BA_ "U_V710_MY2023_Rx" SG_ 1123 GPS_UTC_minutes 1;
BA_ "U_P708_MY2023_Rx" SG_ 1123 GPS_UTC_minutes 1;
BA_ "U_V713AV_MY2022_Rx" SG_ 1123 GPS_UTC_minutes 1;
BA_ "U_V713N_MY2022_Rx" SG_ 1123 GPS_UTC_minutes 1;
BA_ "ECGUsedRxSignal" SG_ 1123 GPS_UTC_minutes 1;
BA_ "U_V710_MY2023_Rx" SG_ 1123 GPS_UTC_hours 1;
BA_ "U_P708_MY2023_Rx" SG_ 1123 GPS_UTC_hours 1;
BA_ "U_V713AV_MY2022_Rx" SG_ 1123 GPS_UTC_hours 1;
BA_ "U_V713N_MY2022_Rx" SG_ 1123 GPS_UTC_hours 1;
BA_ "ECGUsedRxSignal" SG_ 1123 GPS_UTC_hours 1;
BA_ "ECGUsedRxSignal" SG_ 1123 GPS_Compass_direction 1;
BA_ "U_V710_MY2023_Rx" SG_ 1123 GPS_Compass_direction 1;
BA_ "U_P708_MY2023_Rx" SG_ 1123 GPS_Compass_direction 1;
BA_ "U_V713AV_MY2022_Rx" SG_ 1123 GPS_Compass_direction 1;
BA_ "U_V713N_MY2022_Rx" SG_ 1123 GPS_Compass_direction 1;
BA_ "U_V710_MY2023_Rx" SG_ 1123 GPS_Actual_vs_Infer_pos 1;
BA_ "U_P708_MY2023_Rx" SG_ 1123 GPS_Actual_vs_Infer_pos 1;
BA_ "U_V713AV_MY2022_Rx" SG_ 1123 GPS_Actual_vs_Infer_pos 1;
BA_ "U_V713N_MY2022_Rx" SG_ 1123 GPS_Actual_vs_Infer_pos 1;
BA_ "ECGUsedRxSignal" SG_ 1123 GPS_Actual_vs_Infer_pos 1;
BA_ "GenSigSendType" SG_ 1123 GPS_Actual_vs_Infer_pos 1;
BA_ "U_V710_MY2023_Rx" SG_ 1123 Gps_B_Falt 1;
BA_ "U_P708_MY2023_Rx" SG_ 1123 Gps_B_Falt 1;
BA_ "U_V713AV_MY2022_Rx" SG_ 1123 Gps_B_Falt 1;
BA_ "U_V713N_MY2022_Rx" SG_ 1123 Gps_B_Falt 1;
BA_ "ECGUsedRxSignal" SG_ 1123 Gps_B_Falt 1;
BA_ "U_V710_MY2023_Rx" SG_ 1122 GpsHsphLongEast_D_Actl 1;
BA_ "U_P708_MY2023_Rx" SG_ 1122 GpsHsphLongEast_D_Actl 1;
BA_ "U_V713AV_MY2022_Rx" SG_ 1122 GpsHsphLongEast_D_Actl 1;
BA_ "U_V713N_MY2022_Rx" SG_ 1122 GpsHsphLongEast_D_Actl 1;
BA_ "ECGUsedRxSignal" SG_ 1122 GpsHsphLongEast_D_Actl 1;
BA_ "GenSigSendType" SG_ 1122 GpsHsphLongEast_D_Actl 1;
BA_ "U_V710_MY2023_Rx" SG_ 1122 GpsHsphLattSth_D_Actl 1;
BA_ "U_P708_MY2023_Rx" SG_ 1122 GpsHsphLattSth_D_Actl 1;
BA_ "U_V713AV_MY2022_Rx" SG_ 1122 GpsHsphLattSth_D_Actl 1;
BA_ "U_V713N_MY2022_Rx" SG_ 1122 GpsHsphLattSth_D_Actl 1;
BA_ "ECGUsedRxSignal" SG_ 1122 GpsHsphLattSth_D_Actl 1;
BA_ "U_V710_MY2023_Rx" SG_ 1122 GPS_Longitude_Minutes 1;
BA_ "U_P708_MY2023_Rx" SG_ 1122 GPS_Longitude_Minutes 1;
BA_ "U_V713AV_MY2022_Rx" SG_ 1122 GPS_Longitude_Minutes 1;
BA_ "U_V713N_MY2022_Rx" SG_ 1122 GPS_Longitude_Minutes 1;
BA_ "ECGUsedRxSignal" SG_ 1122 GPS_Longitude_Minutes 1;
BA_ "U_V710_MY2023_Rx" SG_ 1122 GPS_Longitude_Min_dec 1;
BA_ "U_P708_MY2023_Rx" SG_ 1122 GPS_Longitude_Min_dec 1;
BA_ "U_V713AV_MY2022_Rx" SG_ 1122 GPS_Longitude_Min_dec 1;
BA_ "U_V713N_MY2022_Rx" SG_ 1122 GPS_Longitude_Min_dec 1;
BA_ "ECGUsedRxSignal" SG_ 1122 GPS_Longitude_Min_dec 1;
BA_ "U_V710_MY2023_Rx" SG_ 1122 GPS_Longitude_Degrees 1;
BA_ "U_P708_MY2023_Rx" SG_ 1122 GPS_Longitude_Degrees 1;
BA_ "U_V713AV_MY2022_Rx" SG_ 1122 GPS_Longitude_Degrees 1;
BA_ "U_V713N_MY2022_Rx" SG_ 1122 GPS_Longitude_Degrees 1;
BA_ "ECGUsedRxSignal" SG_ 1122 GPS_Longitude_Degrees 1;
BA_ "U_V710_MY2023_Rx" SG_ 1122 GPS_Latitude_Minutes 1;
BA_ "U_P708_MY2023_Rx" SG_ 1122 GPS_Latitude_Minutes 1;
BA_ "U_V713AV_MY2022_Rx" SG_ 1122 GPS_Latitude_Minutes 1;
BA_ "U_V713N_MY2022_Rx" SG_ 1122 GPS_Latitude_Minutes 1;
BA_ "ECGUsedRxSignal" SG_ 1122 GPS_Latitude_Minutes 1;
BA_ "U_V710_MY2023_Rx" SG_ 1122 GPS_Latitude_Min_dec 1;
BA_ "U_P708_MY2023_Rx" SG_ 1122 GPS_Latitude_Min_dec 1;
BA_ "U_V713AV_MY2022_Rx" SG_ 1122 GPS_Latitude_Min_dec 1;
BA_ "U_V713N_MY2022_Rx" SG_ 1122 GPS_Latitude_Min_dec 1;
BA_ "ECGUsedRxSignal" SG_ 1122 GPS_Latitude_Min_dec 1;
BA_ "U_V710_MY2023_Rx" SG_ 1122 GPS_Latitude_Degrees 1;
BA_ "U_P708_MY2023_Rx" SG_ 1122 GPS_Latitude_Degrees 1;
BA_ "U_V713AV_MY2022_Rx" SG_ 1122 GPS_Latitude_Degrees 1;
BA_ "U_V713N_MY2022_Rx" SG_ 1122 GPS_Latitude_Degrees 1;
BA_ "ECGUsedRxSignal" SG_ 1122 GPS_Latitude_Degrees 1;
BA_ "WakeupSignal" SG_ 1050 GlvBoxRleas_No_Actl 1;
BA_ "MetaData" SG_ 1050 PrkAidSwtch_No_Cnt 1;
BA_ "U_V710_MY2023_Rx" SG_ 1050 Outside_Air_Temp_Stat 1;
BA_ "U_P708_MY2023_Rx" SG_ 1050 Outside_Air_Temp_Stat 1;
BA_ "U_V713N_MY2022_Rx" SG_ 1050 Outside_Air_Temp_Stat 1;
BA_ "GenSigStartValue" SG_ 1050 Outside_Air_Temp_Stat 254;
BA_ "U_V713AV_MY2022_Rx" SG_ 1106 TrlrSnsId_No_Actl 1;
BA_ "U_V713N_MY2022_Rx" SG_ 1106 TrlrSnsId_No_Actl 1;
BA_ "U_P708_MY2023_Rx" SG_ 1086 EngOil_P_Actl 1;
BA_ "U_P708_MY2023_Rx" SG_ 1086 EngMnfld_P_Actl 1;
BA_ "GenSigStartValue" SG_ 1086 EngIpcDsplyCht_Te_Actl 75;
BA_ "U_V713AV_MY2022_Rx" SG_ 1086 BattULoChrg_U_Cmd 1;
BA_ "U_V713N_MY2022_Rx" SG_ 1086 BattULoChrg_U_Cmd 1;
BA_ "WakeupSignal" SG_ 817 DrTgateOpen_B_Rq 1;
BA_ "WakeupSignal" SG_ 817 DrTgateExtSwMde_B_Stat 1;
BA_ "WakeupSignal" SG_ 817 Remote_Device_Feedback 1;
BA_ "U_P708_MY2023_Rx" SG_ 817 Veh_Lock_Requestor 1;
BA_ "WakeupSignal" SG_ 817 Veh_Lock_Requestor 1;
BA_ "WakeupSignal" SG_ 817 R_Pwr_Sliding_Dr_Rqst 1;
BA_ "WakeupSignal" SG_ 817 Power_Liftgate_Rqst 1;
BA_ "U_P708_MY2023_Rx" SG_ 817 Veh_Lock_EvNum 1;
BA_ "U_V713AV_MY2022_Rx" SG_ 817 Veh_Lock_EvNum 1;
BA_ "U_V713N_MY2022_Rx" SG_ 817 Veh_Lock_EvNum 1;
BA_ "WakeupSignal" SG_ 817 Veh_Lock_EvNum 1;
BA_ "WakeupSignal" SG_ 817 Power_Decklid_Rqst 1;
BA_ "WakeupSignal" SG_ 817 L_Pwr_Sliding_Dr_Rqst 1;
BA_ "MetaData" SG_ 817 Keyfob_Pad_Msg_Count 1;
BA_ "WakeupSignal" SG_ 817 Keyfob_Pad_Msg_Count 1;
BA_ "U_P708_MY2023_Rx" SG_ 817 Veh_Lock_Status 1;
BA_ "U_V710_MY2023_Rx" SG_ 817 Veh_Lock_Status 1;
BA_ "U_V713AV_MY2022_Rx" SG_ 817 Veh_Lock_Status 1;
BA_ "U_V713N_MY2022_Rx" SG_ 817 Veh_Lock_Status 1;
BA_ "GenSigStartValue" SG_ 817 Veh_Lock_Status 1;
BA_ "WakeupSignal" SG_ 817 Veh_Lock_Status 1;
BA_ "GenSigStartValue" SG_ 817 ChildLck_D_Dsply 1;
BA_ "WakeupSignal" SG_ 817 ChildLck_D_Dsply 1;
BA_ "U_V713AV_MY2022_Rx" SG_ 817 RollCodeUnlock 1;
BA_ "U_V713N_MY2022_Rx" SG_ 817 RollCodeUnlock 1;
BA_ "U_V710_MY2023_Rx" SG_ 817 Lockmsgtxt_D_Rq 1;
BA_ "U_P708_MY2023_Rx" SG_ 817 Lockmsgtxt_D_Rq 1;
BA_ "U_V713AV_MY2022_Rx" SG_ 817 Lockmsgtxt_D_Rq 1;
BA_ "U_V713N_MY2022_Rx" SG_ 817 Lockmsgtxt_D_Rq 1;
BA_ "WakeupSignal" SG_ 817 Lockmsgtxt_D_Rq 1;
BA_ "WakeupSignal" SG_ 817 LockInhibit 1;
BA_ "U_V713AV_MY2022_Rx" SG_ 611 AwdTerrMdeChng_D_Rdy 1;
BA_ "U_V713N_MY2022_Rx" SG_ 611 AwdTerrMdeChng_D_Rdy 1;
BA_ "U_V713AV_MY2022_Rx" SG_ 611 AwdTerrMde_D_Actl 1;
BA_ "U_V713N_MY2022_Rx" SG_ 611 AwdTerrMde_D_Actl 1;
BA_ "U_V713AV_MY2022_Rx" SG_ 611 AwdSys_D_Stat 1;
BA_ "U_V713N_MY2022_Rx" SG_ 611 AwdSys_D_Stat 1;
BA_ "U_V710_MY2023_Rx" SG_ 611 AwdStat_D_RqDsply 1;
BA_ "U_P708_MY2023_Rx" SG_ 611 AwdStat_D_RqDsply 1;
BA_ "U_V713AV_MY2022_Rx" SG_ 611 AwdStat_D_RqDsply 1;
BA_ "U_V713N_MY2022_Rx" SG_ 611 AwdStat_D_RqDsply 1;
BA_ "U_P708_MY2023_Rx" SG_ 611 AwdLck_D_Stat 1;
BA_ "U_V713AV_MY2022_Rx" SG_ 611 AwdLck_D_Stat 1;
BA_ "U_V713N_MY2022_Rx" SG_ 611 AwdLck_D_Stat 1;
BA_ "U_V710_MY2023_Rx" SG_ 611 AwdSrvcRqd_B_Rq 1;
BA_ "U_P708_MY2023_Rx" SG_ 611 AwdSrvcRqd_B_Rq 1;
BA_ "U_V713AV_MY2022_Rx" SG_ 611 AwdSrvcRqd_B_Rq 1;
BA_ "U_V713N_MY2022_Rx" SG_ 611 AwdSrvcRqd_B_Rq 1;
BA_ "U_P708_MY2023_Rx" SG_ 611 AwdLck_Tq_Rq 1;
BA_ "U_V713AV_MY2022_Rx" SG_ 611 AwdLck_Tq_Rq 1;
BA_ "U_V713N_MY2022_Rx" SG_ 611 AwdLck_Tq_Rq 1;
BA_ "U_V713AV_MY2022_Rx" SG_ 611 TrnAout_Tq_RqMx 1;
BA_ "U_V713N_MY2022_Rx" SG_ 611 TrnAout_Tq_RqMx 1;
BA_ "GenSigStartValue" SG_ 611 TrnAout_Tq_RqMx 8191;
BA_ "U_V713AV_MY2022_Rx" SG_ 611 AwdOffRoadMode_D_Stats 1;
BA_ "U_V713N_MY2022_Rx" SG_ 611 AwdOffRoadMode_D_Stats 1;
BA_ "U_V710_MY2023_Rx" SG_ 611 AwdLoLamp_D_RqDsply 1;
BA_ "U_P708_MY2023_Rx" SG_ 611 AwdLoLamp_D_RqDsply 1;
BA_ "U_V713AV_MY2022_Rx" SG_ 611 AwdLoLamp_D_RqDsply 1;
BA_ "U_V713N_MY2022_Rx" SG_ 611 AwdLoLamp_D_RqDsply 1;
BA_ "U_V710_MY2023_Rx" SG_ 611 AwdHiLamp_D_RqDsply 1;
BA_ "U_P708_MY2023_Rx" SG_ 611 AwdHiLamp_D_RqDsply 1;
BA_ "U_V713AV_MY2022_Rx" SG_ 611 AwdHiLamp_D_RqDsply 1;
BA_ "U_V713N_MY2022_Rx" SG_ 611 AwdHiLamp_D_RqDsply 1;
BA_ "U_V710_MY2023_Rx" SG_ 611 AwdAutoLamp_D_RqDsply 1;
BA_ "U_P708_MY2023_Rx" SG_ 611 AwdAutoLamp_D_RqDsply 1;
BA_ "U_V713AV_MY2022_Rx" SG_ 611 AwdAutoLamp_D_RqDsply 1;
BA_ "U_V713N_MY2022_Rx" SG_ 611 AwdAutoLamp_D_RqDsply 1;
BA_ "U_V710_MY2023_Rx" SG_ 611 Awd2wdLamp_D_RqDsply 1;
BA_ "U_P708_MY2023_Rx" SG_ 611 Awd2wdLamp_D_RqDsply 1;
BA_ "U_V713AV_MY2022_Rx" SG_ 611 Awd2wdLamp_D_RqDsply 1;
BA_ "U_V713N_MY2022_Rx" SG_ 611 Awd2wdLamp_D_RqDsply 1;
BA_ "U_V710_MY2023_Rx" SG_ 611 AwdRnge_D_Actl 1;
BA_ "U_P708_MY2023_Rx" SG_ 611 AwdRnge_D_Actl 1;
BA_ "U_V713AV_MY2022_Rx" SG_ 611 AwdRnge_D_Actl 1;
BA_ "U_V713N_MY2022_Rx" SG_ 611 AwdRnge_D_Actl 1;
BA_ "GenSigStartValue" SG_ 611 AwdRnge_D_Actl 7;
BA_ "U_V710_MY2023_Rx" SG_ 611 NtrlTowAvail_B_Stat 1;
BA_ "U_P708_MY2023_Rx" SG_ 611 NtrlTowAvail_B_Stat 1;
BA_ "U_V713AV_MY2022_Rx" SG_ 611 NtrlTowAvail_B_Stat 1;
BA_ "U_V713N_MY2022_Rx" SG_ 611 NtrlTowAvail_B_Stat 1;
BA_ "U_V713AV_MY2022_Rx" SG_ 611 AwdDrvMde_D_Stat 1;
BA_ "U_V713N_MY2022_Rx" SG_ 611 AwdDrvMde_D_Stat 1;
BA_ "U_P708_MY2023_Tx" SG_ 1114 TrailCtlSwtch_B_Stat2 1;
BA_ "U_V713AV_MY2022_Tx" SG_ 1114 TrailCtlSwtch_B_Stat2 1;
BA_ "U_V713N_MY2022_Tx" SG_ 1114 TrailCtlSwtch_B_Stat2 1;
BA_ "GenSigSendType" SG_ 1114 TrailCtlSwtch_B_Stat2 3;
BA_ "U_V710_MY2023_Tx" SG_ 1114 TrlBrkInitOut_D_Rq 1;
BA_ "U_P708_MY2023_Tx" SG_ 1114 TrlBrkInitOut_D_Rq 1;
BA_ "U_V713AV_MY2022_Tx" SG_ 1114 TrlBrkInitOut_D_Rq 1;
BA_ "U_V713N_MY2022_Tx" SG_ 1114 TrlBrkInitOut_D_Rq 1;
BA_ "U_P708_MY2023_Rx" SG_ 1114 TrlBrkInitOut_D_Rq 1;
BA_ "GenSigSendType" SG_ 1114 TrlBrkInitOut_D_Rq 3;
BA_ "U_V713AV_MY2022_Tx" SG_ 968 RvltnMatchAllw_D_Rq 1;
BA_ "U_V713N_MY2022_Tx" SG_ 968 RvltnMatchAllw_D_Rq 1;
BA_ "GenSigSendType" SG_ 968 RvltnMatchAllw_D_Rq 3;
BA_ "GenSigSendType" SG_ 968 BrkDrvMde_D_Rq 3;
BA_ "GenSigSendType" SG_ 968 LnchCtl_N_Rq 3;
BA_ "GenSigSendType" SG_ 968 LnchCtl_D_Rq 3;
BA_ "GenSigSendType" SG_ 968 CurrentColor_CmdGage 3;
BA_ "GenSigStartValue" SG_ 968 CurrentColor_CmdGage 8;
BA_ "GenSigSendType" SG_ 968 BlendedColor_CmdGage 3;
BA_ "GenSigStartValue" SG_ 968 BlendedColor_CmdGage 2;
BA_ "GenSigSendType" SG_ 968 BlendColorRed_CmdGage 3;
BA_ "GenSigSendType" SG_ 968 BlendColorGrn_CmdGage 3;
BA_ "GenSigSendType" SG_ 968 BlendColorBlue_CmdGage 3;
BA_ "GenSigSendType" SG_ 968 Dimming_Level_Cmd 3;
BA_ "GenSigSendType" SG_ 968 Current_Color_Cmd 3;
BA_ "GenSigStartValue" SG_ 968 Current_Color_Cmd 8;
BA_ "GenSigSendType" SG_ 968 BlendedColorRed_Cmd 3;
BA_ "GenSigSendType" SG_ 968 BlendedColorGreen_Cmd 3;
BA_ "GenSigSendType" SG_ 968 BlendedColorBlue_Cmd 3;
BA_ "GenSigSendType" SG_ 968 BlendedColor_Cmd 3;
BA_ "GenSigStartValue" SG_ 968 BlendedColor_Cmd 2;
BA_ "GenSigSendType" SG_ 968 SuspDrvMde_D_Rq 3;
BA_ "U_V710_MY2023_Tx" SG_ 968 SlMde_D_Rq 1;
BA_ "U_P708_MY2023_Tx" SG_ 968 SlMde_D_Rq 1;
BA_ "U_V713AV_MY2022_Tx" SG_ 968 SlMde_D_Rq 1;
BA_ "U_V713N_MY2022_Tx" SG_ 968 SlMde_D_Rq 1;
BA_ "GenSigSendType" SG_ 968 SlMde_D_Rq 3;
BA_ "GenSigStartValue" SG_ 968 SlMde_D_Rq 2;
BA_ "U_V710_MY2023_Tx" SG_ 968 IsaOffst_D_Rq 1;
BA_ "U_P708_MY2023_Tx" SG_ 968 IsaOffst_D_Rq 1;
BA_ "U_V713AV_MY2022_Tx" SG_ 968 IsaOffst_D_Rq 1;
BA_ "U_V713N_MY2022_Tx" SG_ 968 IsaOffst_D_Rq 1;
BA_ "GenSigSendType" SG_ 968 IsaOffst_D_Rq 3;
BA_ "GenSigStartValue" SG_ 968 IsaOffst_D_Rq 14;
BA_ "U_V713AV_MY2022_Rx" SG_ 1006 PersIndexIpmb_D_Actl 1;
BA_ "U_V713N_MY2022_Rx" SG_ 1006 PersIndexIpmb_D_Actl 1;
BA_ "GenSigStartValue" SG_ 1006 PersIndexIpmb_D_Actl 4;
BA_ "U_V713AV_MY2022_Rx" SG_ 1006 FeatNoIpmbActl 1;
BA_ "U_V713N_MY2022_Rx" SG_ 1006 FeatNoIpmbActl 1;
BA_ "U_V713AV_MY2022_Rx" SG_ 1006 FeatConfigIpmbActl 1;
BA_ "U_V713N_MY2022_Rx" SG_ 1006 FeatConfigIpmbActl 1;
BA_ "U_P708_MY2023_Rx" SG_ 129 EngExhMdeQuiet_B_RqDrv2 1;
BA_ "U_P708_MY2023_Rx" SG_ 129 SteWhlSwtchHome_B_Stat 1;
BA_ "U_V713AV_MY2022_Rx" SG_ 129 SteWhlSwtchHome_B_Stat 1;
BA_ "U_V713N_MY2022_Rx" SG_ 129 SteWhlSwtchHome_B_Stat 1;
BA_ "U_V710_MY2023_Rx" SG_ 129 SteWhlSwtchInfo_B_Stat 1;
BA_ "U_V713AV_MY2022_Rx" SG_ 129 SteWhlSwtchInfo_B_Stat 1;
BA_ "U_V713N_MY2022_Rx" SG_ 129 SteWhlSwtchInfo_B_Stat 1;
BA_ "U_V713AV_MY2022_Rx" SG_ 129 SteWhlSwtchView_B_Stat 1;
BA_ "U_V713N_MY2022_Rx" SG_ 129 SteWhlSwtchView_B_Stat 1;
BA_ "WakeupSignal" SG_ 129 SteWhlSwtchView_B_Stat 1;
BA_ "U_V713AV_MY2022_Rx" SG_ 129 SteWhlSwtchSet_B_Stat 1;
BA_ "U_V713N_MY2022_Rx" SG_ 129 SteWhlSwtchSet_B_Stat 1;
BA_ "WakeupSignal" SG_ 129 SteWhlSwtchSet_B_Stat 1;
BA_ "U_V713AV_MY2022_Rx" SG_ 129 SteWhlSwtchPhon_B_Stat 1;
BA_ "U_V713N_MY2022_Rx" SG_ 129 SteWhlSwtchPhon_B_Stat 1;
BA_ "U_P708_MY2023_Rx" SG_ 129 SteWhlSwtchPhon_B_Stat 1;
BA_ "WakeupSignal" SG_ 129 SteWhlSwtchPhon_B_Stat 1;
BA_ "U_V713AV_MY2022_Rx" SG_ 129 SteWhlSwtchNav_B_Stat 1;
BA_ "U_V713N_MY2022_Rx" SG_ 129 SteWhlSwtchNav_B_Stat 1;
BA_ "WakeupSignal" SG_ 129 SteWhlSwtchNav_B_Stat 1;
BA_ "U_V713AV_MY2022_Rx" SG_ 129 SteWhlSwtchMed_B_Stat 1;
BA_ "U_V713N_MY2022_Rx" SG_ 129 SteWhlSwtchMed_B_Stat 1;
BA_ "U_P708_MY2023_Rx" SG_ 129 SteWhlSwtchMed_B_Stat 1;
BA_ "WakeupSignal" SG_ 129 SteWhlSwtchMed_B_Stat 1;
BA_ "U_V713AV_MY2022_Rx" SG_ 129 SteWhlSwtchIod_B_Stat 1;
BA_ "U_V713N_MY2022_Rx" SG_ 129 SteWhlSwtchIod_B_Stat 1;
BA_ "WakeupSignal" SG_ 129 SteWhlSwtchIod_B_Stat 1;
BA_ "U_V710_MY2023_Rx" SG_ 129 SteWhlSwtchHud_B_Stat 1;
BA_ "U_V713AV_MY2022_Rx" SG_ 129 SteWhlSwtchHud_B_Stat 1;
BA_ "U_V713N_MY2022_Rx" SG_ 129 SteWhlSwtchHud_B_Stat 1;
BA_ "U_P708_MY2023_Rx" SG_ 129 SteWhlSwtchHud_B_Stat 1;
BA_ "WakeupSignal" SG_ 129 SteWhlSwtchHud_B_Stat 1;
BA_ "U_V710_MY2023_Rx" SG_ 129 SteWhlSwtchBack_B_Stat 1;
BA_ "U_V713AV_MY2022_Rx" SG_ 129 SteWhlSwtchBack_B_Stat 1;
BA_ "U_V713N_MY2022_Rx" SG_ 129 SteWhlSwtchBack_B_Stat 1;
BA_ "U_P708_MY2023_Rx" SG_ 129 SteWhlSwtchBack_B_Stat 1;
BA_ "WakeupSignal" SG_ 129 SteWhlSwtchBack_B_Stat 1;
BA_ "U_V710_MY2023_Rx" SG_ 129 SteWhlSwtchMenu_B_Stat 1;
BA_ "U_P708_MY2023_Rx" SG_ 129 SteWhlSwtchMenu_B_Stat 1;
BA_ "U_V713AV_MY2022_Rx" SG_ 129 SteWhlSwtchMenu_B_Stat 1;
BA_ "U_V713N_MY2022_Rx" SG_ 129 SteWhlSwtchMenu_B_Stat 1;
BA_ "WakeupSignal" SG_ 129 SteWhlSwtchMenu_B_Stat 1;
BA_ "U_V713AV_MY2022_Rx" SG_ 129 SteEffortInc_B_RqDrv 1;
BA_ "U_V713N_MY2022_Rx" SG_ 129 SteEffortInc_B_RqDrv 1;
BA_ "U_V713AV_MY2022_Rx" SG_ 129 SelDrvMdeInc_B_RqDrv 1;
BA_ "U_V713N_MY2022_Rx" SG_ 129 SelDrvMdeInc_B_RqDrv 1;
BA_ "U_V713AV_MY2022_Rx" SG_ 129 SelDrvMdeDec_B_RqDrv 1;
BA_ "U_V713N_MY2022_Rx" SG_ 129 SelDrvMdeDec_B_RqDrv 1;
BA_ "U_V713AV_MY2022_Rx" SG_ 129 SuspDampInc_B_RqDrv 1;
BA_ "U_V713N_MY2022_Rx" SG_ 129 SuspDampInc_B_RqDrv 1;
BA_ "U_V710_MY2023_Rx" SG_ 129 SteWhlSwtchUp_B_Stat 1;
BA_ "U_P708_MY2023_Rx" SG_ 129 SteWhlSwtchUp_B_Stat 1;
BA_ "U_V713AV_MY2022_Rx" SG_ 129 SteWhlSwtchUp_B_Stat 1;
BA_ "U_V713N_MY2022_Rx" SG_ 129 SteWhlSwtchUp_B_Stat 1;
BA_ "WakeupSignal" SG_ 129 SteWhlSwtchUp_B_Stat 1;
BA_ "U_V710_MY2023_Rx" SG_ 129 SteWhlSwtchRght_B_Stat 1;
BA_ "U_V713AV_MY2022_Rx" SG_ 129 SteWhlSwtchRght_B_Stat 1;
BA_ "U_V713N_MY2022_Rx" SG_ 129 SteWhlSwtchRght_B_Stat 1;
BA_ "WakeupSignal" SG_ 129 SteWhlSwtchRght_B_Stat 1;
BA_ "U_V710_MY2023_Rx" SG_ 129 SteWhlSwtchOk_B_Stat 1;
BA_ "U_P708_MY2023_Rx" SG_ 129 SteWhlSwtchOk_B_Stat 1;
BA_ "U_V713AV_MY2022_Rx" SG_ 129 SteWhlSwtchOk_B_Stat 1;
BA_ "U_V713N_MY2022_Rx" SG_ 129 SteWhlSwtchOk_B_Stat 1;
BA_ "WakeupSignal" SG_ 129 SteWhlSwtchOk_B_Stat 1;
BA_ "U_V710_MY2023_Rx" SG_ 129 SteWhlSwtchLeft_B_Stat 1;
BA_ "U_V713AV_MY2022_Rx" SG_ 129 SteWhlSwtchLeft_B_Stat 1;
BA_ "U_V713N_MY2022_Rx" SG_ 129 SteWhlSwtchLeft_B_Stat 1;
BA_ "WakeupSignal" SG_ 129 SteWhlSwtchLeft_B_Stat 1;
BA_ "U_V710_MY2023_Rx" SG_ 129 SteWhlSwtchDown_B_Stat 1;
BA_ "U_P708_MY2023_Rx" SG_ 129 SteWhlSwtchDown_B_Stat 1;
BA_ "U_V713AV_MY2022_Rx" SG_ 129 SteWhlSwtchDown_B_Stat 1;
BA_ "U_V713N_MY2022_Rx" SG_ 129 SteWhlSwtchDown_B_Stat 1;
BA_ "WakeupSignal" SG_ 129 SteWhlSwtchDown_B_Stat 1;
BA_ "U_P708_MY2023_Tx" SG_ 1244 Con_InfotainmentVer_St 1;
BA_ "U_V713AV_MY2022_Tx" SG_ 1244 Con_InfotainmentVer_St 1;
BA_ "U_V713N_MY2022_Tx" SG_ 1244 Con_InfotainmentVer_St 1;
BA_ "U_P708_MY2023_Rx" SG_ 1244 Con_InfotainmentVer_St 1;
BA_ "U_P708_MY2023_Tx" SG_ 1244 Con_Profiles_St 1;
BA_ "U_V713AV_MY2022_Tx" SG_ 1244 Con_Profiles_St 1;
BA_ "U_V713N_MY2022_Tx" SG_ 1244 Con_Profiles_St 1;
BA_ "U_P708_MY2023_Rx" SG_ 1244 Con_Profiles_St 1;
BA_ "U_P708_MY2023_Tx" SG_ 1244 Con_Configuration 1;
BA_ "U_V713AV_MY2022_Tx" SG_ 1244 Con_Configuration 1;
BA_ "U_V713N_MY2022_Tx" SG_ 1244 Con_Configuration 1;
BA_ "U_P708_MY2023_Rx" SG_ 1244 Con_Configuration 1;
BA_ "U_P708_MY2023_Tx" SG_ 1243 Con_BTAud_InfotainmVer_St 1;
BA_ "U_V713AV_MY2022_Tx" SG_ 1243 Con_BTAud_InfotainmVer_St 1;
BA_ "U_V713N_MY2022_Tx" SG_ 1243 Con_BTAud_InfotainmVer_St 1;
BA_ "U_P708_MY2023_Rx" SG_ 1243 Con_BTAud_InfotainmVer_St 1;
BA_ "U_P708_MY2023_Tx" SG_ 1243 Con_BTAud_Profiles_St 1;
BA_ "U_V713AV_MY2022_Tx" SG_ 1243 Con_BTAud_Profiles_St 1;
BA_ "U_V713N_MY2022_Tx" SG_ 1243 Con_BTAud_Profiles_St 1;
BA_ "U_P708_MY2023_Rx" SG_ 1243 Con_BTAud_Profiles_St 1;
BA_ "U_P708_MY2023_Tx" SG_ 1243 Con_BTAudConfiguration 1;
BA_ "U_V713AV_MY2022_Tx" SG_ 1243 Con_BTAudConfiguration 1;
BA_ "U_V713N_MY2022_Tx" SG_ 1243 Con_BTAudConfiguration 1;
BA_ "U_P708_MY2023_Rx" SG_ 1243 Con_BTAudConfiguration 1;
BA_ "U_V710_MY2023_Tx" SG_ 681 Con_DB1temIndex_St 1;
BA_ "U_P708_MY2023_Tx" SG_ 681 Con_DB1temIndex_St 1;
BA_ "U_V713AV_MY2022_Tx" SG_ 681 Con_DB1temIndex_St 1;
BA_ "U_V713N_MY2022_Tx" SG_ 681 Con_DB1temIndex_St 1;
BA_ "GenSigSendType" SG_ 681 Con_DB1temIndex_St 1;
BA_ "U_V710_MY2023_Tx" SG_ 681 Con_DB1FilterConfig_St 1;
BA_ "U_P708_MY2023_Tx" SG_ 681 Con_DB1FilterConfig_St 1;
BA_ "U_V713AV_MY2022_Tx" SG_ 681 Con_DB1FilterConfig_St 1;
BA_ "U_V713N_MY2022_Tx" SG_ 681 Con_DB1FilterConfig_St 1;
BA_ "U_V710_MY2023_Tx" SG_ 681 Con_DB1Filter3_St 1;
BA_ "U_P708_MY2023_Tx" SG_ 681 Con_DB1Filter3_St 1;
BA_ "U_V713AV_MY2022_Tx" SG_ 681 Con_DB1Filter3_St 1;
BA_ "U_V713N_MY2022_Tx" SG_ 681 Con_DB1Filter3_St 1;
BA_ "U_V710_MY2023_Tx" SG_ 681 Con_DB1Filter2_St 1;
BA_ "U_P708_MY2023_Tx" SG_ 681 Con_DB1Filter2_St 1;
BA_ "U_V713AV_MY2022_Tx" SG_ 681 Con_DB1Filter2_St 1;
BA_ "U_V713N_MY2022_Tx" SG_ 681 Con_DB1Filter2_St 1;
BA_ "U_V710_MY2023_Tx" SG_ 681 Con_DB1Filter1_St 1;
BA_ "U_P708_MY2023_Tx" SG_ 681 Con_DB1Filter1_St 1;
BA_ "U_V713AV_MY2022_Tx" SG_ 681 Con_DB1Filter1_St 1;
BA_ "U_V713N_MY2022_Tx" SG_ 681 Con_DB1Filter1_St 1;
BA_ "U_V713AV_MY2022_Tx" SG_ 744 Con_USB_ActTrNum1_St 1;
BA_ "U_V713N_MY2022_Tx" SG_ 744 Con_USB_ActTrNum1_St 1;
BA_ "GenSigSendType" SG_ 744 Con_USB_ActTrNum1_St 3;
BA_ "U_V713AV_MY2022_Tx" SG_ 744 Con_iPod_NumberOfTracks 1;
BA_ "U_V713N_MY2022_Tx" SG_ 744 Con_iPod_NumberOfTracks 1;
BA_ "GenSigSendType" SG_ 744 Con_iPod_NumberOfTracks 3;
BA_ "U_V713AV_MY2022_Tx" SG_ 744 Con_USB_NumberOfTracks 1;
BA_ "U_V713N_MY2022_Tx" SG_ 744 Con_USB_NumberOfTracks 1;
BA_ "GenSigSendType" SG_ 744 Con_USB_NumberOfTracks 3;
BA_ "U_P708_MY2023_Tx" SG_ 712 NAV_MC_WORD_Rx 1;
BA_ "U_V713AV_MY2022_Tx" SG_ 712 NAV_MC_WORD_Rx 1;
BA_ "U_V713N_MY2022_Tx" SG_ 712 NAV_MC_WORD_Rx 1;
BA_ "U_V713AV_MY2022_Tx" SG_ 639 OfbChrgPrflUpdate_B_Rq 1;
BA_ "U_V713N_MY2022_Tx" SG_ 639 OfbChrgPrflUpdate_B_Rq 1;
BA_ "ECGUsedTxSignal" SG_ 639 OfbChrgPrflUpdate_B_Rq 1;
BA_ "GenSigSendType" SG_ 639 OfbChrgPrflUpdate_B_Rq 3;
BA_ "U_V713AV_MY2022_Tx" SG_ 639 OfbChrgGoTUpdate_B_Rq 1;
BA_ "U_V713N_MY2022_Tx" SG_ 639 OfbChrgGoTUpdate_B_Rq 1;
BA_ "ECGUsedTxSignal" SG_ 639 OfbChrgGoTUpdate_B_Rq 1;
BA_ "GenSigSendType" SG_ 639 OfbChrgGoTUpdate_B_Rq 3;
BA_ "U_V713AV_MY2022_Tx" SG_ 639 OfbChrgClearAll_B_Rq 1;
BA_ "U_V713N_MY2022_Tx" SG_ 639 OfbChrgClearAll_B_Rq 1;
BA_ "ECGUsedTxSignal" SG_ 639 OfbChrgClearAll_B_Rq 1;
BA_ "GenSigSendType" SG_ 639 OfbChrgClearAll_B_Rq 3;
BA_ "U_V713AV_MY2022_Tx" SG_ 639 OfbChrgGoTTouch_D_Rq 1;
BA_ "U_V713N_MY2022_Tx" SG_ 639 OfbChrgGoTTouch_D_Rq 1;
BA_ "ECGUsedTxSignal" SG_ 639 OfbChrgGoTTouch_D_Rq 1;
BA_ "GenSigSendType" SG_ 639 OfbChrgGoTTouch_D_Rq 3;
BA_ "U_V713AV_MY2022_Tx" SG_ 639 OfbChrgGoTPrcond_D_Rq 1;
BA_ "U_V713N_MY2022_Tx" SG_ 639 OfbChrgGoTPrcond_D_Rq 1;
BA_ "ECGUsedTxSignal" SG_ 639 OfbChrgGoTPrcond_D_Rq 1;
BA_ "U_V713AV_MY2022_Tx" SG_ 639 OfbChrgGoTOn_D_Rq 1;
BA_ "U_V713N_MY2022_Tx" SG_ 639 OfbChrgGoTOn_D_Rq 1;
BA_ "ECGUsedTxSignal" SG_ 639 OfbChrgGoTOn_D_Rq 1;
BA_ "GenSigSendType" SG_ 639 OfbChrgGoTOn_D_Rq 3;
BA_ "U_V713AV_MY2022_Tx" SG_ 639 OfbChrgGoTMnte_D_Rq 1;
BA_ "U_V713N_MY2022_Tx" SG_ 639 OfbChrgGoTMnte_D_Rq 1;
BA_ "ECGUsedTxSignal" SG_ 639 OfbChrgGoTMnte_D_Rq 1;
BA_ "MetaData" SG_ 639 OfbChrgGoTMnte_D_Rq 1;
BA_ "U_V713AV_MY2022_Tx" SG_ 639 OfbChrgGoTHr_T_Rq 1;
BA_ "U_V713N_MY2022_Tx" SG_ 639 OfbChrgGoTHr_T_Rq 1;
BA_ "ECGUsedTxSignal" SG_ 639 OfbChrgGoTHr_T_Rq 1;
BA_ "GenSigStartValue" SG_ 639 OfbChrgGoTHr_T_Rq 30;
BA_ "U_V713AV_MY2022_Tx" SG_ 639 OfbChrgGoTExtHtr_D_Rq 1;
BA_ "U_V713N_MY2022_Tx" SG_ 639 OfbChrgGoTExtHtr_D_Rq 1;
BA_ "ECGUsedTxSignal" SG_ 639 OfbChrgGoTExtHtr_D_Rq 1;
BA_ "GenSigSendType" SG_ 639 OfbChrgGoTExtHtr_D_Rq 3;
BA_ "U_V713AV_MY2022_Tx" SG_ 639 OfbChrgGoTElement_D_Rq 1;
BA_ "U_V713N_MY2022_Tx" SG_ 639 OfbChrgGoTElement_D_Rq 1;
BA_ "ECGUsedTxSignal" SG_ 639 OfbChrgGoTElement_D_Rq 1;
BA_ "GenSigSendType" SG_ 639 OfbChrgGoTElement_D_Rq 3;
BA_ "MetaData" SG_ 639 OfbChrgGoTElement_D_Rq 1;
BA_ "U_V713AV_MY2022_Tx" SG_ 639 OfbChrgGoTDelete_B_Rq 1;
BA_ "U_V713N_MY2022_Tx" SG_ 639 OfbChrgGoTDelete_B_Rq 1;
BA_ "ECGUsedTxSignal" SG_ 639 OfbChrgGoTDelete_B_Rq 1;
BA_ "U_V713AV_MY2022_Tx" SG_ 741 Con_USB_Playtype_St 1;
BA_ "U_V713N_MY2022_Tx" SG_ 741 Con_USB_Playtype_St 1;
BA_ "GenSigSendType" SG_ 741 Con_USB_Playtype_St 3;
BA_ "U_V713AV_MY2022_Tx" SG_ 741 Con_ShowSWDLBargr_St 1;
BA_ "U_V713N_MY2022_Tx" SG_ 741 Con_ShowSWDLBargr_St 1;
BA_ "U_V713AV_MY2022_Tx" SG_ 741 Con_ShowSWDLprogress_St 1;
BA_ "U_V713N_MY2022_Tx" SG_ 741 Con_ShowSWDLprogress_St 1;
BA_ "GenSigSendType" SG_ 741 Con_ShowSWDLprogress_St 3;
BA_ "U_V713AV_MY2022_Tx" SG_ 741 Con_iPod_IntroScan_St 1;
BA_ "U_V713N_MY2022_Tx" SG_ 741 Con_iPod_IntroScan_St 1;
BA_ "GenSigSendType" SG_ 741 Con_iPod_IntroScan_St 3;
BA_ "U_V713AV_MY2022_Tx" SG_ 741 Con_iPod_Shuffle_St 1;
BA_ "U_V713N_MY2022_Tx" SG_ 741 Con_iPod_Shuffle_St 1;
BA_ "GenSigSendType" SG_ 741 Con_iPod_Shuffle_St 3;
BA_ "U_V713AV_MY2022_Tx" SG_ 741 Con_iPod_Repeat_St 1;
BA_ "U_V713N_MY2022_Tx" SG_ 741 Con_iPod_Repeat_St 1;
BA_ "GenSigSendType" SG_ 741 Con_iPod_Repeat_St 3;
BA_ "U_V713AV_MY2022_Tx" SG_ 741 Con_USB_Repeat_St 1;
BA_ "U_V713N_MY2022_Tx" SG_ 741 Con_USB_Repeat_St 1;
BA_ "GenSigSendType" SG_ 741 Con_USB_Repeat_St 3;
BA_ "U_V713AV_MY2022_Tx" SG_ 741 Con_USB_IntroScan_St 1;
BA_ "U_V713N_MY2022_Tx" SG_ 741 Con_USB_IntroScan_St 1;
BA_ "GenSigSendType" SG_ 741 Con_USB_IntroScan_St 3;
BA_ "U_V713AV_MY2022_Tx" SG_ 741 Con_USB_Shuffle_St 1;
BA_ "U_V713N_MY2022_Tx" SG_ 741 Con_USB_Shuffle_St 1;
BA_ "GenSigSendType" SG_ 741 Con_USB_Shuffle_St 3;
BA_ "U_V713AV_MY2022_Tx" SG_ 741 Con_iPod_Error_St 1;
BA_ "U_V713N_MY2022_Tx" SG_ 741 Con_iPod_Error_St 1;
BA_ "GenSigSendType" SG_ 741 Con_iPod_Error_St 3;
BA_ "U_V713AV_MY2022_Tx" SG_ 741 Con_USB_Error_St 1;
BA_ "U_V713N_MY2022_Tx" SG_ 741 Con_USB_Error_St 1;
BA_ "GenSigSendType" SG_ 741 Con_USB_Error_St 3;
BA_ "U_V713AV_MY2022_Tx" SG_ 741 Con_iPod_FunctStatus_St 1;
BA_ "U_V713N_MY2022_Tx" SG_ 741 Con_iPod_FunctStatus_St 1;
BA_ "GenSigSendType" SG_ 741 Con_iPod_FunctStatus_St 3;
BA_ "U_V713AV_MY2022_Tx" SG_ 741 Con_USB_FunctStatus_St 1;
BA_ "U_V713N_MY2022_Tx" SG_ 741 Con_USB_FunctStatus_St 1;
BA_ "GenSigSendType" SG_ 741 Con_USB_FunctStatus_St 3;
BA_ "U_V713AV_MY2022_Tx" SG_ 741 Con_USB_OpMode_St 1;
BA_ "U_V713N_MY2022_Tx" SG_ 741 Con_USB_OpMode_St 1;
BA_ "GenSigSendType" SG_ 741 Con_USB_OpMode_St 3;
BA_ "U_V713AV_MY2022_Tx" SG_ 741 Con_iPod_OpMode_St 1;
BA_ "U_V713N_MY2022_Tx" SG_ 741 Con_iPod_OpMode_St 1;
BA_ "GenSigSendType" SG_ 741 Con_iPod_OpMode_St 3;
BA_ "GenSigStartValue" SG_ 954 ExtLghtFront_D_RqBody 1;
BA_ "WakeupSignal" SG_ 954 ExtLghtFront_D_RqBody 1;
BA_ "WakeupSignal" SG_ 954 LghtAmbDrvMde_B_Stat 1;
BA_ "WakeupSignal" SG_ 954 PwRnngBoardPoll_D_Stat 1;
BA_ "WakeupSignal" SG_ 954 TrlrHitchLamp_D_Stat 1;
BA_ "WakeupSignal" SG_ 954 TrukBedLght_B_Stat 1;
BA_ "U_V710_MY2023_Rx" SG_ 954 VehWlcmFrwlMde_D_Stat 1;
BA_ "WakeupSignal" SG_ 954 VehWlcmFrwlMde_D_Stat 1;
BA_ "WakeupSignal" SG_ 954 PudSptLghtRight_D_Rq 1;
BA_ "WakeupSignal" SG_ 954 PudSptLghtLeft_D_Rq 1;
BA_ "WakeupSignal" SG_ 954 ExtLghtRight_D_Stat 1;
BA_ "WakeupSignal" SG_ 954 VehWlcmFrwl_D_Stat 1;
BA_ "WakeupSignal" SG_ 954 ExtLghtRear_D_Stat 1;
BA_ "WakeupSignal" SG_ 954 ExtLghtLeft_D_Stat 1;
BA_ "WakeupSignal" SG_ 954 ExtLghtAlrt_B_Rq 1;
BA_ "WakeupSignal" SG_ 954 ExtLght_D_Falt 1;
BA_ "WakeupSignal" SG_ 954 ExtLghtFront_D_Stat 1;
BA_ "GenSigStartValue" SG_ 125 VehRolComp_W_Actl 4094;
BA_ "GenSigStartValue" SG_ 125 VehVertComp_A_Actl 1022;
BA_ "U_P708_MY2023_Rx" SG_ 125 BrkTotTqRqArb_No_Cs 1;
BA_ "MetaData" SG_ 125 BrkTotTqRqArb_No_Cs 1;
BA_ "U_P708_MY2023_Rx" SG_ 125 BrkTotTqRqArb_No_Cnt 1;
BA_ "MetaData" SG_ 125 BrkTotTqRqArb_No_Cnt 1;
BA_ "U_P708_MY2023_Rx" SG_ 125 BrkTot_Tq_RqArb 1;
BA_ "U_P708_MY2023_Rx" SG_ 125 BrkTot_Tq_Actl 1;
BA_ "U_V713AV_MY2022_Rx" SG_ 125 BrkTot_Tq_Actl 1;
BA_ "U_V713N_MY2022_Rx" SG_ 125 BrkTot_Tq_Actl 1;
BA_ "U_V710_MY2023_Rx" SG_ 125 HsaStat_D_Actl 1;
BA_ "U_P708_MY2023_Rx" SG_ 125 HsaStat_D_Actl 1;
BA_ "U_V713AV_MY2022_Rx" SG_ 125 HsaStat_D_Actl 1;
BA_ "U_V713N_MY2022_Rx" SG_ 125 HsaStat_D_Actl 1;
VAL_ 760 SDARS_Alert_Status 0 "Invalid" 2 "Disabled" 1 "Enabled" ;
VAL_ 760 SDARS_Channel_Lock 0 "Invalid" 2 "Unlocked" 1 "Locked" ;
VAL_ 1113 TrlrTrgtAcquire_D_Stat 7 "Faulty" 6 "NotUsed_2" 5 "NotUsed_1" 4 "RVCforTBA_Activated" 3 "Processing" 2 "TargetNotAcquired" 1 "TargetAcquired" 0 "Null" ;
VAL_ 1113 TrlrAnCalib_B_Complt 1 "Yes" 0 "No" ;
VAL_ 1113 TrlrRvrse_D_Stat 3 "Faulty" 2 "TrailerReverseGuidanceLite" 1 "On" 0 "Off" ;
VAL_ 1113 TrlrAid_D2_Stat 15 "Faulty" 14 "NotUsed_4" 13 "NotUsed_3" 12 "NotUsed_2" 11 "NotUsed_1" 10 "DirtyCamera" 9 "IncorrectLighting" 8 "TrackingLost" 7 "TrackingUnknownConfidence" 6 "TrackingHighConfidence" 5 "TrackingMediumConfidence" 4 "TrackingLowConfidence" 3 "TurnRequested" 2 "DriveStraighRequested" 1 "Initializing" 0 "NotTracking" ;
VAL_ 1113 TrlrAnOffstDir_D_Calc 3 "NotUSed" 2 "Right" 1 "Left_or_Center" 0 "Null" ;
VAL_ 1113 TrlrAid_An3_Actl 2047 "Faulty" ;
VAL_ 1113 TrlrAid_AnRate2_Actl 1023 "Faulty" ;
VAL_ 1113 HitchToVehAxle_L_Calc 255 "Faulty" ;
VAL_ 1144 AwdLckMde_D_Stat 7 "NotUsed_2" 6 "NotUsed_1" 5 "PrimaryAxleSpeedControl" 4 "DualAxleSpeedControl" 3 "EfficiencySplit" 2 "SecondaryAxleTorqueCtrl" 1 "SecondaryAxleSpeedCtrl" 0 "Off" ;
VAL_ 1144 BattTracCool_B_Actl 1 "On" 0 "Off" ;
VAL_ 1144 BattChrgInhbt_D2_Rq 7 "NotUsed_4" 6 "NotUsed_3" 5 "NotUsed_2" 4 "NotUsed_1" 3 "MaintainTargetSoc" 2 "EndAtTarget" 1 "InhibitCharging" 0 "Enable_Charging" ;
VAL_ 1144 BattChrgTrgtSoC_D_Rq 7 "Percent_50" 6 "Percent_60" 5 "Percent_70" 4 "Percent_80" 3 "Percent_85" 2 "Percent_90" 1 "Percent_95" 0 "Percent_100" ;
VAL_ 1144 CabnEvapSovFront_B_Rq 1 "On" 0 "Off" ;
VAL_ 1144 HeatCoreSovRear_B_Rq 1 "On" 0 "Off" ;
VAL_ 1144 BattChlrSov_B_Rq 1 "On" 0 "Off" ;
VAL_ 1144 CabnEvapSovRear_B_Rq 1 "On" 0 "Off" ;
VAL_ 1144 BrkAppl_D_RqPt 3 "BrakesSlowRelease" 2 "BrakesFastRelease" 1 "BrakesEngage" 0 "NotActive" ;
VAL_ 1144 BattClntVlvOvrrd_D_Rq 3 "NotUsed" 2 "OverrideTbcvToChiller" 1 "OverrideTbcvToRadiator" 0 "NoOverrideToTbcvCLogic" ;
VAL_ 1144 BattTracChillerOn_B_Rq 1 "On" 0 "Off" ;
VAL_ 1144 BattTracChiller_D_Stat 3 "NotUsed" 2 "ChillerNotAvailable" 1 "ChillerBrieflyAvailable" 0 "ChillerAvailable" ;
VAL_ 1144 HtrnDcdcDis_B_Rq 1 "Yes" 0 "No" ;
VAL_ 1144 HtrnCnnctPwr_B_Stat 1 "Asserted" 0 "NotAsserted" ;
VAL_ 1144 PtcHtr_D_Stat 3 "Faulty" 2 "NotUsed" 1 "On" 0 "Off" ;
VAL_ 1144 WakeAlarm0_B_Typ 1 "CanAndEcuDriveCircuit" 0 "CanOnly" ;
VAL_ 1144 HtrnClntFlw_D_Rq 3 "High" 2 "Medium" 1 "Low" 0 "Off" ;
VAL_ 1144 BattTracDrvSustn_B_Rq 1 "Active" 0 "Inactive" ;
VAL_ 1144 CabinDrvSustn_B_Rq 1 "Active" 0 "Inactive" ;
VAL_ 1144 ChrgNowEvnt_B_Stat 1 "Active" 0 "Inactive" ;
VAL_ 1144 PreCondBatt_B_Actl 1 "On" 0 "Off" ;
VAL_ 1144 BattTracClntVlv_B_Rq 1 "On" 0 "Off" ;
VAL_ 1144 ULoBattTrnsfrSustn_B_Rq 1 "Active" 0 "Inactive" ;
VAL_ 1144 ULoBattTransfer_D_Stat 7 "NotUsed_2" 6 "NotUsed_1" 5 "TransferError" 4 "TransferComplete" 3 "TransferThroughGridEnergy" 2 "InsufficientEnergyToXfer" 1 "TransferInProgress" 0 "NoTransfer" ;
VAL_ 1144 BattTracClimtDis_B_Stat 1 "Enable" 0 "Disable" ;
VAL_ 523 EngAirFiltMsgTxt_D_Rq 7 "NotUsed_2" 6 "ReducedEngPwCheckAirFilter" 5 "EngineAirFilterMonitorFalt" 4 "ResetComplete" 3 "Clogged" 2 "ReplaceNow" 1 "ReplaceSoon" 0 "NoMessage" ;
VAL_ 523 WaterInFuel_B_Falt 1 "Fault" 0 "NoFault" ;
VAL_ 523 UreaMnAdd_L2_Actl 255 "Faulty" ;
VAL_ 523 UreaMxAdd_L2_Actl 511 "Faulty" ;
VAL_ 942 ApaOffOptnSel_B_Avail 1 "Available" 0 "NotAvailable" ;
VAL_ 942 ApaSlotOption_B_Avail 1 "Available" 0 "NotAvailable" ;
VAL_ 942 ApaSlotAlrtSet_B_Stat 1 "Enable" 0 "Disable" ;
VAL_ 942 ApaSlotAlrt_B_Rq 1 "True" 0 "False" ;
VAL_ 942 ApaRmtFeatSel_B_Avail 1 "Available" 0 "NotAvailable" ;
VAL_ 942 ApaParkOutSel_B_Avail 1 "Available" 0 "NotAvailable" ;
VAL_ 942 ApaSys_D2_Stat 15 "NotUsed_5" 14 "NotUsed_4" 13 "NotUsed_3" 12 "NotUsed_2" 11 "NotUsed_1" 10 "NoSideSelectable" 9 "RightSideSelectable" 8 "LeftSideSelectable" 7 "BothSidesSelectable" 6 "Faulty" 5 "Finished" 4 "Cancelled" 3 "NotAvailable" 2 "Overspeed" 1 "Pause" 0 "NormalOperation" ;
VAL_ 942 ApaSlotTrgt_D_Stat 15 "NotUsed_7" 14 "NotUsed_6" 13 "NotUsed_5" 12 "NotUsed_4" 11 "NotUsed_3" 10 "NotUsed_2" 9 "NotUsed_1" 8 "Front" 7 "Rear" 6 "Right3" 5 "Right2" 4 "Right1" 3 "Left3" 2 "Left2" 1 "Left1" 0 "None" ;
VAL_ 942 ApaParkInSel_B_Avail 1 "Available" 0 "NotAvailable" ;
VAL_ 942 ApaMsgTxt_D2_Stat 15 "ReducedFunction" 14 "TrailerFeatureNotAvailable" 13 "AcceleratorPedalInactive" 12 "SensorsBlocked" 11 "TrailerAttached" 10 "TcsDeactivated" 9 "WheelSlip" 8 "HighInclination" 7 "DoorOpen" 6 "SteeringInteraction" 5 "WrongDirection" 4 "SpeedLimitExceeded" 3 "BrakeEvent" 2 "ObstacleInPath" 1 "WaitForSteering" 0 "None" ;
VAL_ 942 ApaDynmcSlot_B_Stat 1 "On" 0 "Off" ;
VAL_ 942 ApaDisplayMode_D_Stat 3 "NotUsed" 2 "FullScreen" 1 "Menu" 0 "Off" ;
VAL_ 942 ApaControlMode_D_Stat 1 "Active" 0 "Inactive" ;
VAL_ 942 PrkBrkElRleas_B_RqApa 1 "Yes" 0 "No" ;
VAL_ 942 PrkAidAcsyRear_D_Stat 3 "NotUsed" 2 "On" 1 "Off" 0 "Null" ;
VAL_ 942 PrkAidAcsyFront_D_Stat 3 "NotUsed" 2 "On" 1 "Off" 0 "Null" ;
VAL_ 942 ApaDrvRq2MsgTxt_D_Rq 15 "NotUsed_7" 14 "NotUsed_6" 13 "NotUsed_5" 12 "NotUsed_4" 11 "NotUsed_3" 10 "NotUsed_2" 9 "NotUsed_1" 8 "CloseDoor" 7 "TakeControl" 6 "ReleaseEpb" 5 "ReleaseSteering" 4 "ReleaseBrake" 3 "DriveBackward" 2 "DriveForward" 1 "Stop" 0 "NoRequest" ;
VAL_ 942 ApaDrvRq1MsgTxt_D_Rq 7 "NotUsed" 6 "ExitVehicle" 5 "PressApaButton" 4 "ShiftToP" 3 "ShiftToN" 2 "ShiftToD" 1 "ShiftToR" 0 "NoRequest" ;
VAL_ 942 PrkAidDrvDir_D_Stat 7 "NotUsed_2" 6 "NotUsed_1" 5 "BackwardNegative" 4 "ForwardNegative" 3 "BackwardPositive" 2 "ForwardPositive" 1 "NoMotion" 0 "DirectionNotKnown" ;
VAL_ 1088 TrlrRng_L_Dsply 8191 "Faulty" 8190 "NoDataExists" ;
VAL_ 1088 BattDcChrgRms_I_Lim 32767 "Faulty" 32766 "NoDataExists" ;
VAL_ 1088 HvacPrecondRecirc_D_Rq 3 "Last_User_Setting" 2 "Auto" 1 "Recirc" 0 "Outside" ;
VAL_ 1088 HvacPrecondMode2_D_Rq 15 "NotUsed4" 14 "NotUsed3" 13 "NotUsed2" 12 "NotUsed1" 11 "Last_User_Settings" 10 "Auto" 9 "Max_Defrost" 8 "Windshield_Panel_Floor" 7 "Windshield_Panel" 6 "Windshield" 5 "Windshield_Floor" 4 "Floor" 3 "Panel_Floor" 2 "Panel" 1 "MAX_AC" 0 "Off" ;
VAL_ 1088 HvacPrecondBlwr2_D_Rq 15 "NotUsed6" 14 "NotUsed5" 13 "NotUsed4" 12 "NotUsed3" 11 "NotUsed2" 10 "NotUsed1" 9 "Last_User_Setting" 8 "Auto" 7 "Speed7" 6 "Speed6" 5 "Speed5" 4 "Speed4" 3 "Speed3" 2 "Speed2" 1 "Speed1" 0 "Off" ;
VAL_ 1088 HvacPrecondAC_D_Rq 3 "Last_User_Setting" 2 "Auto" 1 "On" 0 "Off" ;
VAL_ 1088 BattChrgInhbt_D_Rq 3 "MaintainTargetSoc" 2 "NotUsed" 1 "InhibitChargingThermal" 0 "Enable_Charging" ;
VAL_ 1088 ChrgStat_D2_Dsply 15 "ChargeStopCommanded" 14 "ChargeStartCommanded" 13 "ChargeTargetReached" 12 "DriveConditioning" 11 "CabinPreconditioning" 10 "ChargingSystemMaintain" 9 "ChargingInductive" 8 "ChargingDCFastCharge" 7 "ChargingAC" 6 "ChargeScheduled" 5 "EvsePaused" 4 "EvseNotDetected" 3 "EvseNotCompatible" 2 "FaultOutsideCar" 1 "FaultInsideCar" 0 "NotReady" ;
VAL_ 1088 ChrgTMatch_B_Stat 1 "True" 0 "False" ;
VAL_ 761 SDARS_Seek_Scan_St 1 "NoChannelsAvailable" 0 "Invalid" ;
VAL_ 761 SDARS_Invalid_Chan_St 0 "Invalid" 2 "Active" 1 "Inactive" ;
VAL_ 761 SDARS_UnSubscrb_Chan_St 0 "Invalid" 2 "Active" 1 "Inactive" ;
VAL_ 761 SDARS_Loss_Ant_St 0 "Invalid" 2 "Active" 1 "Inactive" ;
VAL_ 761 SDARS_UnSubscrb_St 0 "Invalid" 2 "Active" 1 "Inactive" ;
VAL_ 761 SDARS_Subscription_St 0 "Invalid" 2 "Active" 1 "Inactive" ;
VAL_ 761 SDARS_GCI_Update_St 0 "Invalid" 2 "Active" 1 "Inactive" ;
VAL_ 761 SDARS_Firmware_Updat_St 0 "Invalid" 2 "Active" 1 "Inactive" ;
VAL_ 761 SDARS_Antenna_Err_St 0 "Invalid" 2 "Active" 1 "Inactive" ;
VAL_ 761 SDARS_Receive_Err_St 0 "Invalid" 2 "Active" 1 "Inactive" ;
VAL_ 761 SDARS_Error_Conf_St 0 "Invalid" 2 "SDARS_OFF" 1 "SDARS_ON" ;
VAL_ 750 LoclFuelEffUnit_D_Stat 3 "NotUsed" 2 "Active" 1 "Inactive" 0 "Null" ;
VAL_ 750 RoadsideAsstAvail_D_St 3 "AvailableFord" 2 "AvailableLincoln" 1 "NotAvailable" 0 "Null" ;
VAL_ 750 EmbedNavActive_D_Stat 3 "NotUsed" 2 "Active" 1 "Inactive" 0 "Null" ;
VAL_ 750 UnitOfLength_St 3 "miles_yards" 2 "miles_feets" 1 "kilometers_meters" 0 "Invalid" ;
VAL_ 750 RouteActive_St 1 "Active" 0 "Inactive" ;
VAL_ 750 CancelCurrWaypt_St 1 "Cancelled" 0 "Inactive" ;
VAL_ 750 Nav_RemainTTDestDays_St 14 "Exceeding13days" ;
VAL_ 750 WaypointsActive_St 3 "Max_Waypoints_Active" 2 "Waypoints_Active" 1 "Waypoints_Inactive" 0 "Invalid" ;
VAL_ 750 Nav_DistanToDestUnit_St 3 "Yards_yd" 2 "Miles_mi" 1 "Meters_m" 0 "Kilometers_km" ;
VAL_ 750 NavError_Waypoint_St 2 "Navigation_Fault" 1 "No_Error" 0 "Invalid" ;
VAL_ 725 InfotainmentAudio_St 3 "NotUsed" 2 "ErrorState_NoAudio" 1 "NormalOperation" 0 "Null" ;
VAL_ 725 ACU_CompLogic_St 0 "Invalid" 1 "Off" 2 "On" ;
VAL_ 725 ACU_RadioError_St 0 "Invalid" 1 "NoError" 2 "PiNotFound" 3 "PtyNotFound" ;
VAL_ 725 ACU_HardwareError_St 0 "Invalid" 1 "NoError" 2 "EepromReadError" 3 "KeycodeLocked" 4 "KeycodeLockedForever" 5 "CommunicationError" 6 "OverTemperature" 7 "FocusError" ;
VAL_ 725 ACU_CurrentRadioBand_St 6 "Fm3" 0 "Invalid" 1 "Fm1" 2 "Fm2" 3 "FmAst" 4 "Am" 5 "AmAst" ;
VAL_ 725 ACU_AFMode_St 0 "Invalid" 1 "AfOn" 2 "AfOff" 3 "Auto" ;
VAL_ 1049 DcacZone3PwBttn_B_Stat 1 "Pressed" 0 "Not_Pressed" ;
VAL_ 1049 DcacZone2PwBttn_B_Stat 1 "Pressed" 0 "Not_Pressed" ;
VAL_ 1049 DcacPwResetBtn2_B_Stat 1 "Pressed" 0 "Not_Pressed" ;
VAL_ 1049 DcacPwOffButtn2_B_Stat 1 "Pressed" 0 "Not_Pressed" ;
VAL_ 1049 DcacPwHiButtn2_B_Stat 1 "Pressed" 0 "Not_Pressed" ;
VAL_ 1049 DcacGfciTestBtn2_B_Stat 1 "Pressed" 0 "Not_Pressed" ;
VAL_ 1049 DcacAllZoneBttn_B_Stat 1 "Pressed" 0 "Not_Pressed" ;
VAL_ 1049 DcacChime_D_Rq 3 "NotUsed" 2 "SoftChime" 1 "InformationChime" 0 "NoChime" ;
VAL_ 1049 PersTurnSglView_D_RqMnu 3 "NotUsed" 2 "Enable" 1 "Disable" 0 "Null" ;
VAL_ 1049 TrailCtlSwtch_B_Stat4 1 "Pressed" 0 "Not_Pressed" ;
VAL_ 1049 RearDiffLck_D_RqDrv3 3 "Faulty" 2 "NoRequest" 1 "On" 0 "Off" ;
VAL_ 1049 FrontDiffLck_D_RqDrv3 3 "Faulty" 2 "NoRequest" 1 "On" 0 "Off" ;
VAL_ 1049 CamraFrnt_B_RqMnu 1 "On" 0 "Off" ;
VAL_ 1049 TurnAsstSwtch_D_Stat 3 "Faulty" 2 "NotUsed" 1 "Pressed" 0 "Not_Pressed" ;
VAL_ 1049 StabBarCnncButtn_D_Sta3 3 "Faulty" 2 "NotUsed" 1 "Pressed" 0 "Not_Pressed" ;
VAL_ 1049 SelDrvMdeTxtRst_B_Rq2 1 "Yes" 0 "No" ;
VAL_ 1049 SelDrvMdePage_B_Stat 1 "Active" 0 "Inactive" ;
VAL_ 1049 SelDrvMdeCnfm_D_Stat2 3 "NotUsed" 2 "Accepted" 1 "NotAccepted" 0 "Null" ;
VAL_ 1049 SelDrvMde_D_RqDrv 31 "Faulty" 30 "SelDrvMde31" 29 "SelDrvMde30" 28 "SelDrvMde29" 27 "SelDrvMde28" 26 "SelDrvMde27" 25 "SelDrvMde26" 24 "SelDrvMde25" 23 "SelDrvMde24" 22 "SelDrvMde23" 21 "SelDrvMde22" 20 "SelDrvMde21" 19 "SelDrvMde20" 18 "SelDrvMde19" 17 "SelDrvMde18" 16 "SelDrvMde17" 15 "SelDrvMde16" 14 "SelDrvMde15" 13 "SelDrvMde14" 12 "SelDrvMde13" 11 "SelDrvMde12" 10 "SelDrvMde11" 9 "SelDrvMde10" 8 "SelDrvMde09" 7 "SelDrvMde08" 6 "SelDrvMde07" 5 "SelDrvMde06" 4 "SelDrvMde05" 3 "SelDrvMde04" 2 "SelDrvMde03" 1 "SelDrvMde02" 0 "SelDrvMde01" ;
VAL_ 1014 WrlssAcsyChrgr_D_Stat 7 "NotUsed" 6 "Misalignment" 5 "Overheat" 4 "MetalObjectDetected" 3 "ChargingComplete" 2 "ChargingInProgress" 1 "ChargingNotInProgress" 0 "Null" ;
VAL_ 1014 WrlssAcsyChrg_Pc_Actl 127 "Faulty" 126 "NoDataExists" ;
VAL_ 548 DSP_AHU_ChmTstTone_Rq 1 "Active" 0 "Inactive" ;
VAL_ 548 DSP_ChimeChanState_St 7 "Reserved4" 6 "Reserved3" 5 "Reserved2" 4 "Reserved" 3 "Busy" 2 "Ready" 1 "Muted" 0 "Invalid" ;
VAL_ 548 DSP_Chime2_Not_Recgnizd 0 "Inactive" 1 "Chime_Not_Recognized" ;
VAL_ 548 DSP_Chime_Not_Recgnizd 0 "Inactive" 1 "Chime_Not_Recognized" ;
VAL_ 548 DSP_Alert_Channel3 3 "Reserved" 2 "Muted" 1 "Initialized_for_Prompts" 0 "Inactive" ;
VAL_ 548 DSP_Alert_Channel2 3 "Initialized_for_chimes" 2 "Muted" 1 "Reserved" 0 "Inactive" ;
VAL_ 548 DSP_Alert_Channel1 3 "Initialized_for_chimes" 2 "Muted" 1 "Reserved" 0 "Inactive" ;
VAL_ 548 DSP_Chimes_Supported 3 "Not_Used" 2 "Not_Supported" 1 "Supported" 0 "Inactive" ;
VAL_ 548 DSP_AdjChimVolSupp_St 3 "NotUsed_1" 2 "Supported" 1 "NotSupported" 0 "Inactive" ;
VAL_ 548 DSP_AdjChimVolSupp2_St 3 "NotUsed_1" 2 "Supported" 1 "NotSupported" 0 "Inactive" ;
VAL_ 548 DSP_AHU_ChmTstT 31 "NotUsed_22" 30 "NotUsed_21" 29 "NotUsed_20" 28 "NotUsed_19" 27 "NotUsed_18" 26 "NotUsed_17" 25 "NotUsed_16" 24 "NotUsed_15" 23 "NotUsed_14" 22 "NotUsed_13" 21 "NotUsed_12" 20 "NotUsed_11" 19 "NotUsed_10" 18 "NotUsed_9" 17 "NotUsed_8" 16 "NotUsed_7" 15 "NotUsed_6" 14 "NotUsed_5" 13 "NotUsed_4" 12 "NotUsed_3" 11 "NotUsed_2" 10 "NotUsed_1" 9 "Crank_3" 8 "NotUsed" 7 "Running_2" 6 "IgnitionOn_2" 5 "PostIgnition_1" 4 "Accessory_1" 3 "PostAccessory_0" 2 "KeyApproved_0" 1 "KeyRecentlyOut" 0 "KeyOut" ;
VAL_ 548 DspDgtlChime_D_Stat 3 "NotUsed_1" 2 "Supported" 1 "NotSupported" 0 "Inactive" ;
VAL_ 404 Dsp_LangUpdate_Rsp 2 "Language_Not_Supported" 1 "Language_Updated" 0 "Inactive" ;
VAL_ 1008 NavIod_D_Stat 15 "Faulty" 14 "NotUsed_9" 13 "NotUsed_8" 12 "NotUsed_7" 11 "NotUsed_6" 10 "NotUsed_5" 9 "NotUsed_4" 8 "NotUsed_3" 7 "NotUsed_2" 6 "NotUsed_1" 5 "NavigationMode_AR" 4 "NavigationMode_2D" 3 "CruiseMode_2D" 2 "OutputOn" 1 "FeatureAvailButNoOuput" 0 "FeatureNotAvailable" ;
VAL_ 1008 SelectedNumOfPresets 31 "Reserved" 30 "Preset30" 4 "Preset4" 3 "Preset3" 2 "Preset2" 1 "Preset1" 0 "Inactive" ;
VAL_ 1008 MultimediaSrc_D_Stat 10 "BaiduCarlife" 9 "AndroidAuto" 8 "CarPlay" 7 "AppLink" 6 "LineIn" 5 "BluetoothAudio" 4 "WiFi" 3 "SdCard" 2 "Usb" 1 "AudioVideoln" 0 "Null" ;
VAL_ 1008 MultimediaShuf_D_Stat 3 "NotUsed" 2 "On" 1 "Off" 0 "Null" ;
VAL_ 1008 MultimediaRepeat_D_Stat 3 "RepeatOn" 2 "RepeatOff" 1 "RepeatOne" 0 "Null" ;
VAL_ 1008 CPM_MediaPlayerSrc_St 31 "Empty" 30 "Reserved14" 29 "Reserved13" 28 "Reserved12" 27 "Reserved11" 26 "Reserved10" 25 "Reserved9" 24 "Reserved8" 23 "Reserved7" 22 "Reserved6" 21 "Reserved5" 20 "Reserved4" 19 "Reserved3" 18 "Reserved2" 17 "Reserved1" 16 "SourceID16" 15 "SourceID15" 14 "SourceID14" 13 "SourceID13" 12 "SourceID12" 11 "SourceID11" 10 "SourceID10" 9 "SourceID9" 8 "SourceID8" 7 "SourceID7" 6 "SourceID6" 5 "SourceID5" 4 "SourceID4" 3 "SourceID3" 2 "SourceID2" 1 "SourceID1" 0 "NoDataExists" ;
VAL_ 547 Audio_Amp_St 3 "On" 2 "Partial_Amp" 1 "Off" 0 "NoDataExists" ;
VAL_ 547 Chime_Alert_Chan2 2 "Reserved" 1 "Mute" 0 "Inactive" ;
VAL_ 547 AHU_Chime2_Active 63 "Chime_62" 4 "Chime_3" 3 "Chime_2" 2 "Chime_1" 1 "NoChime" 0 "Inactive" ;
VAL_ 547 AHU_Chime2_Not_Recognized 0 "Inactive" 1 "Chime_Not_Recognized" ;
VAL_ 547 Chime_Alert_Chan 2 "Reserved" 1 "Mute" 0 "Inactive" ;
VAL_ 547 AHU_Alert_Channel1 3 "Reserved" 2 "Muted" 1 "Initialize_for_prompt" 0 "Inactive" ;
VAL_ 547 AHU_Chime_Supported 3 "Not_Used" 2 "Not_Supported" 1 "Supported" 0 "Inactive" ;
VAL_ 547 AHU_Chime_Active 63 "Chime_62" 4 "Chime_3" 3 "Chime_2" 2 "Chime_1" 1 "NoChime" 0 "Inactive" ;
VAL_ 547 AHU_Chime_Not_Recognized 0 "Inactive" 1 "Chime_Not_Recognized" ;
VAL_ 547 ChimeId_No_Stat 255 "Id255" 254 "Id254" 253 "Id253" 252 "Id252" 251 "Id251" 250 "Id250" 249 "Id249" 248 "Id248" 247 "Id247" 246 "Id246" 245 "Id245" 244 "Id244" 243 "Id243" 242 "Id242" 241 "Id241" 240 "Id240" 239 "Id239" 238 "Id238" 237 "Id237" 236 "Id236" 235 "Id235" 234 "Id234" 233 "Id233" 232 "Id232" 231 "Id231" 230 "Id230" 229 "Id229" 228 "Id228" 227 "Id227" 226 "Id226" 225 "Id225" 224 "Id224" 223 "Id223" 222 "Id222" 221 "Id221" 220 "Id220" 219 "Id219" 218 "Id218" 217 "Id217" 216 "Id216" 215 "Id215" 214 "Id214" 213 "Id213" 212 "Id212" 211 "Id211" 210 "Id210" 209 "Id209" 208 "Id208" 207 "Id207" 206 "Id206" 205 "Id205" 204 "Id204" 203 "Id203" 202 "Id202" 201 "Id201" 200 "Id200" 199 "Id199" 198 "Id198" 197 "Id197" 196 "Id196" 195 "Id195" 194 "Id194" 193 "Id193" 192 "Id192" 191 "Id191" 190 "Id190" 189 "Id189" 188 "Id188" 187 "Id187" 186 "Id186" 185 "Id185" 184 "Id184" 183 "Id183" 182 "Id182" 181 "Id181" 180 "Id180" 179 "Id179" 178 "Id178" 177 "Id177" 176 "Id176" 175 "Id175" 174 "Id174" 173 "Id173" 172 "Id172" 171 "Id171" 170 "Id170" 169 "Id169" 168 "Id168" 167 "Id167" 166 "Id166" 165 "Id165" 164 "Id164" 163 "Id163" 162 "Id162" 161 "Id161" 160 "Id160" 159 "Id159" 158 "Id158" 157 "Id157" 156 "Id156" 155 "Id155" 154 "Id154" 153 "Id153" 152 "Id152" 151 "Id151" 150 "Id150" 149 "Id149" 148 "Id148" 147 "Id147" 146 "Id146" 145 "Id145" 144 "Id144" 143 "Id143" 142 "Id142" 141 "Id141" 140 "Id140" 139 "Id139" 138 "Id138" 137 "Id137" 136 "Id136" 135 "Id135" 134 "Id134" 133 "Id133" 132 "Id132" 131 "Id131" 130 "Id130" 129 "Id129" 128 "Id128" 127 "Id127" 126 "Id126" 125 "Id125" 124 "Id124" 123 "Id123" 122 "Id122" 121 "Id121" 120 "Id120" 119 "Id119" 118 "Id118" 117 "Id117" 116 "Id116" 115 "Id115" 114 "Id114" 113 "Id113" 112 "Id112" 111 "Id111" 110 "Id110" 109 "Id109" 108 "Id108" 107 "Id107" 106 "Id106" 105 "Id105" 104 "Id104" 103 "Id103" 102 "Id102" 101 "Id101" 100 "Id100" 99 "Id99" 98 "Id98" 97 "Id97" 96 "Id96" 95 "Id95" 94 "Id94" 93 "Id93" 92 "Id92" 91 "Id91" 90 "Id90" 89 "Id89" 88 "Id88" 87 "Id87" 86 "Id86" 85 "Id85" 84 "Id84" 83 "Id83" 82 "Id82" 81 "Id81" 80 "Id80" 79 "Id79" 78 "Id78" 77 "Id77" 76 "Id76" 75 "Id75" 74 "Id74" 73 "Id73" 72 "Id72" 71 "Id71" 70 "Id70" 69 "Id69" 68 "Id68" 67 "Id67" 66 "Id66" 65 "Id65" 64 "Id64" 63 "Id63" 62 "Id62" 61 "Id61" 60 "Id60" 59 "Id59" 58 "Id58" 57 "Id57" 56 "Id56" 55 "Id55" 54 "Id54" 53 "Id53" 52 "Id52" 51 "Id51" 50 "Id50" 49 "Id49" 48 "Id48" 47 "Id47" 46 "Id46" 45 "Id45" 44 "Id44" 43 "Id43" 42 "Id42" 41 "Id41" 40 "Id40" 39 "Id39" 38 "Id38" 37 "Id37" 36 "Id36" 35 "Id35" 34 "Id34" 33 "Id33" 32 "Id32" 31 "Id31" 30 "Id30" 29 "Id29" 28 "Id28" 27 "Id27" 26 "Id26" 25 "Id25" 24 "Id24" 23 "Id23" 22 "Id22" 21 "Id21" 20 "Id20" 19 "Id19" 18 "Id18" 17 "Id17" 16 "Id16" 15 "Id15" 14 "Id14" 13 "Id13" 12 "Id12" 11 "Id11" 10 "Id10" 9 "Id9" 8 "Id8" 7 "Id7" 6 "Id6" 5 "Id5" 4 "Id4" 3 "Id3" 2 "Id2" 1 "Id1" 0 "Inactive" ;
VAL_ 547 Chime2Id_No_Stat 255 "Id255" 254 "Id254" 253 "Id253" 252 "Id252" 251 "Id251" 250 "Id250" 249 "Id249" 248 "Id248" 247 "Id247" 246 "Id246" 245 "Id245" 244 "Id244" 243 "Id243" 242 "Id242" 241 "Id241" 240 "Id240" 239 "Id239" 238 "Id238" 237 "Id237" 236 "Id236" 235 "Id235" 234 "Id234" 233 "Id233" 232 "Id232" 231 "Id231" 230 "Id230" 229 "Id229" 228 "Id228" 227 "Id227" 226 "Id226" 225 "Id225" 224 "Id224" 223 "Id223" 222 "Id222" 221 "Id221" 220 "Id220" 219 "Id219" 218 "Id218" 217 "Id217" 216 "Id216" 215 "Id215" 214 "Id214" 213 "Id213" 212 "Id212" 211 "Id211" 210 "Id210" 209 "Id209" 208 "Id208" 207 "Id207" 206 "Id206" 205 "Id205" 204 "Id204" 203 "Id203" 202 "Id202" 201 "Id201" 200 "Id200" 199 "Id199" 198 "Id198" 197 "Id197" 196 "Id196" 195 "Id195" 194 "Id194" 193 "Id193" 192 "Id192" 191 "Id191" 190 "Id190" 189 "Id189" 188 "Id188" 187 "Id187" 186 "Id186" 185 "Id185" 184 "Id184" 183 "Id183" 182 "Id182" 181 "Id181" 180 "Id180" 179 "Id179" 178 "Id178" 177 "Id177" 176 "Id176" 175 "Id175" 174 "Id174" 173 "Id173" 172 "Id172" 171 "Id171" 170 "Id170" 169 "Id169" 168 "Id168" 167 "Id167" 166 "Id166" 165 "Id165" 164 "Id164" 163 "Id163" 162 "Id162" 161 "Id161" 160 "Id160" 159 "Id159" 158 "Id158" 157 "Id157" 156 "Id156" 155 "Id155" 154 "Id154" 153 "Id153" 152 "Id152" 151 "Id151" 150 "Id150" 149 "Id149" 148 "Id148" 147 "Id147" 146 "Id146" 145 "Id145" 144 "Id144" 143 "Id143" 142 "Id142" 141 "Id141" 140 "Id140" 139 "Id139" 138 "Id138" 137 "Id137" 136 "Id136" 135 "Id135" 134 "Id134" 133 "Id133" 132 "Id132" 131 "Id131" 130 "Id130" 129 "Id129" 128 "Id128" 127 "Id127" 126 "Id126" 125 "Id125" 124 "Id124" 123 "Id123" 122 "Id122" 121 "Id121" 120 "Id120" 119 "Id119" 118 "Id118" 117 "Id117" 116 "Id116" 115 "Id115" 114 "Id114" 113 "Id113" 112 "Id112" 111 "Id111" 110 "Id110" 109 "Id109" 108 "Id108" 107 "Id107" 106 "Id106" 105 "Id105" 104 "Id104" 103 "Id103" 102 "Id102" 101 "Id101" 100 "Id100" 99 "Id99" 98 "Id98" 97 "Id97" 96 "Id96" 95 "Id95" 94 "Id94" 93 "Id93" 92 "Id92" 91 "Id91" 90 "Id90" 89 "Id89" 88 "Id88" 87 "Id87" 86 "Id86" 85 "Id85" 84 "Id84" 83 "Id83" 82 "Id82" 81 "Id81" 80 "Id80" 79 "Id79" 78 "Id78" 77 "Id77" 76 "Id76" 75 "Id75" 74 "Id74" 73 "Id73" 72 "Id72" 71 "Id71" 70 "Id70" 69 "Id69" 68 "Id68" 67 "Id67" 66 "Id66" 65 "Id65" 64 "Id64" 63 "Id63" 62 "Id62" 61 "Id61" 60 "Id60" 59 "Id59" 58 "Id58" 57 "Id57" 56 "Id56" 55 "Id55" 54 "Id54" 53 "Id53" 52 "Id52" 51 "Id51" 50 "Id50" 49 "Id49" 48 "Id48" 47 "Id47" 46 "Id46" 45 "Id45" 44 "Id44" 43 "Id43" 42 "Id42" 41 "Id41" 40 "Id40" 39 "Id39" 38 "Id38" 37 "Id37" 36 "Id36" 35 "Id35" 34 "Id34" 33 "Id33" 32 "Id32" 31 "Id31" 30 "Id30" 29 "Id29" 28 "Id28" 27 "Id27" 26 "Id26" 25 "Id25" 24 "Id24" 23 "Id23" 22 "Id22" 21 "Id21" 20 "Id20" 19 "Id19" 18 "Id18" 17 "Id17" 16 "Id16" 15 "Id15" 14 "Id14" 13 "Id13" 12 "Id12" 11 "Id11" 10 "Id10" 9 "Id9" 8 "Id8" 7 "Id7" 6 "Id6" 5 "Id5" 4 "Id4" 3 "Id3" 2 "Id2" 1 "Id1" 0 "Inactive" ;
VAL_ 547 AHU_AdjChimVolSupp2_St 3 "NotUsed_1" 2 "Supported" 1 "NotSupported" 0 "Inactive" ;
VAL_ 547 AHU_AdjChimeVolSupp_St 3 "NotUsed_1" 2 "Supported" 1 "NotSupported" 0 "Inactive" ;
VAL_ 547 AhuDgtlChime_D_Stat 3 "NotUsed_1" 2 "Supported" 1 "NotSupported" 0 "Inactive" ;
VAL_ 732 ACU_CurrItemsInFMSL_St 255 "NoValidPreset" 0 "Invalid" ;
VAL_ 732 ACU_FunctionStatus_St 7 "RemoveDisc" 0 "Invalid" 1 "Reading" 2 "Loading" 3 "Loaded" 4 "Insert" 5 "PreparingToEject" 6 "Ejecting" ;
VAL_ 732 ACU_CurrFMSLPreset_St 255 "NoValidPreset" 0 "Invalid" ;
VAL_ 732 ACU_CurrPreset2_St 31 "NoActivePreset" 0 "Invalid" ;
VAL_ 732 ACU_StorePreset_St 31 "NotStoring" 0 "Invalid" ;
VAL_ 732 ACU_VoiceCommand_St 2 "NotOk" 1 "Ok" 0 "Invalid" ;
VAL_ 732 ACU_CurrMixPreset_St 31 "NoActivePreset" 0 "Invalid" ;
VAL_ 728 PrplSnd_D_Stat 3 "Faulty" 2 "Enabled" 1 "Disabled" 0 "Null" ;
VAL_ 728 ACU_AuxVolume_Up 1 "Update" 0 "NoUpdate" ;
VAL_ 728 ACU_RadioSeekMode_St 14 "PISeek" 0 "Invalid" 1 "SeekOff" 2 "AutoUp" 3 "AutoDown" 4 "ManSingleStepUp" 5 "ManSingleStepDown" 6 "ContManualUp" 7 "ContManualDown" 8 "ScanUp" 9 "ScanDown" 10 "PtySeekUp" 11 "PtySeekDown" 12 "Autostore" 13 "TpSeek" ;
VAL_ 728 ACU_Volume_Up 1 "Update" 0 "NoUpdate" ;
VAL_ 757 SpkrStdRight_D_Stat 3 "Faulty" 2 "Normal" 1 "NotPresent" 0 "Null" ;
VAL_ 757 SpkrStdLeft_D_Stat 3 "Faulty" 2 "Normal" 1 "NotPresent" 0 "Null" ;
VAL_ 757 SpkrStdCntr_D_Stat 3 "Faulty" 2 "Normal" 1 "NotPresent" 0 "Null" ;
VAL_ 757 SdarsAudioRtng_D_Stat 3 "NotUsed" 2 "APIMStereoOut" 1 "X40l2SStereoOut" 0 "NotDetermined" ;
VAL_ 757 SDARS_ChipControl_St 7 "NotUsed_2" 6 "NotUsed_1" 5 "Ready" 4 "ResetInProgress" 3 "PowerDownInProgress" 2 "PowerUpInProgress" 1 "Off" 0 "Null" ;
VAL_ 757 ACU_AutoStoreResult_St 2 "No_Station_Found" 1 "Inactive" 0 "Invalid" ;
VAL_ 757 ACU_DirectTune_St 2 "Valid_Station" 1 "Invalid_Station" 0 "Invalid" ;
VAL_ 757 ACU_RadioSeekMode2_St 16 "ContAutoDown" 15 "ContAutoUp" 14 "PISeek" 13 "TpSeek" 12 "Autostore" 11 "PtySeekDown" 10 "PtySeekUp" 9 "ScanDown" 8 "ScanUp" 7 "ContManualDown" 6 "ContManualUp" 5 "ManSingleStepDown" 4 "ManSingleStepUp" 3 "AutoDown" 2 "AutoUp" 1 "SeekOff" 0 "Invalid" ;
VAL_ 757 ACU_CurrTUBand_St 10 "SAT2" 9 "SAT1" 8 "DAB2" 7 "DAB1" 6 "Fm3" 5 "AmAst" 4 "Am" 3 "FmAst" 2 "Fm2" 1 "Fm1" 0 "Invalid" 13 "reserved1" 15 "reserved_last" 12 "DAB3" 11 "SAT3" ;
VAL_ 734 ACU_ActServiceLink_St 3 "reserved" 2 "FM2DAB" 1 "DAB2FM" 0 "Invalid" ;
VAL_ 734 ACU_CurrTUDRService2_St 7 "last_reserved" 5 "reserved" 4 "DabNotAvailable" 3 "ServiceAvailable" 2 "ServiceNotAvailable" 1 "SyncEnsemble" 0 "Invalid" ;
VAL_ 734 ACU_ComTUSIDValid_St 1 "Validation" 0 "Invalid" ;
VAL_ 734 ACU_CurrTUDRService_St 3 "ServiceAvailable" 2 "ServiceNotAvailable" 1 "SyncEnsemble" 0 "Invalid" ;
VAL_ 734 ACU_CurrTURadioBand_St 12 "reserved" 11 "SAT3" 10 "SAT2" 15 "reserved_last" 9 "SAT1" 8 "DAB2" 7 "DAB1" 6 "Fm3" 5 "AmAst" 4 "Am" 3 "FmAst" 2 "Fm2" 1 "Fm1" 0 "Invalid" ;
VAL_ 734 ACU_CurrTUServiceLink_St 3 "reserved" 2 "Inactive" 1 "Active" 0 "Invalid" ;
VAL_ 759 Avail_HD_Chan_Valid 1 "Valid" 0 "Invalid" ;
VAL_ 759 Avail_HD_Chan_St_7 1 "Available" 0 "NotAvailable" ;
VAL_ 759 Avail_HD_Chan_St_6 1 "Available" 0 "NotAvailable" ;
VAL_ 759 Avail_HD_Chan_St_5 1 "Available" 0 "NotAvailable" ;
VAL_ 759 Avail_HD_Chan_St_4 1 "Available" 0 "NotAvailable" ;
VAL_ 759 Avail_HD_Chan_St_3 1 "Available" 0 "NotAvailable" ;
VAL_ 759 Avail_HD_Chan_St_2 1 "Available" 0 "NotAvailable" ;
VAL_ 759 Avail_HD_Chan_St_1 1 "Available" 0 "NotAvailable" ;
VAL_ 759 ACM_StationListScanSt 1 "Scan_Cancelled" ;
VAL_ 759 ACM_TagMode 2 "On" 1 "Off" 0 "Inactive" ;
VAL_ 759 ACM_RBDSMode 2 "On" 1 "Off" 0 "Inactive" ;
VAL_ 759 NumofHDMulticastChans_St 7 "Multicast_Available_7" 6 "Multicast_Available_6" 5 "Multicast_Available_5" 4 "Multicast_Available_4" 3 "Multicast_Available_3" 2 "Multicast_Available_2" 1 "Multicast_Available_1" 0 "zero" ;
VAL_ 759 ACM_HDModeStatus 2 "On" 1 "Off" 0 "Inactive" ;
VAL_ 759 ACM_HDChanStatus 4 "Not_Found" 3 "Not_Multicast" 2 "Acquired" 1 "Acquiring" ;
VAL_ 759 ACM_CurrentHDMulticast_St 7 "7" 6 "6" 5 "5" 4 "4" 3 "3" 2 "2" 1 "1" 0 "0" ;
VAL_ 144 SetTimeFormat 3 "NotUsed" 2 "_24h_mode" 1 "_12h_mode" 0 "Inactive" ;
VAL_ 144 TimeAdjustRequest 0 "NoTimeAdjustRequest" 1 "TimeAdjustRequest" ;
VAL_ 144 DateAdjustRequest 0 "NoDateAdjustRequest" 1 "DateAdjustRequest" ;
VAL_ 851 ConsLongTerm_No_Dsply 4095 "Faulty" 4094 "No_Data_Exists" ;
VAL_ 851 ConsUnitIPC_D_Dsply 15 "Reserved_15" 14 "Reserved_14" 13 "Reserved_13" 12 "Reserved_12" 11 "MPG_Hi-Res" 10 "miles_gallon__UK_" 9 "km_L_" 8 "Liters___100_km" 7 "Miles___Gallon" 6 "Whr___km_" 5 "Whr___mi_" 4 "miles_gallon__UK_" 2 "Liters___100_km" 1 "Miles___Gallon__US_" 0 "Invalid" 3 "km_L" ;
VAL_ 851 ConsAvgTrip_No_Dsply 4095 "Faulty" 4094 "No_Data_Exists" ;
VAL_ 792 ElTrip_L_Dsply 65535 "Fault" 65534 "No_Data_Exists" ;
VAL_ 792 ElLongTerm_L_Dsply 16777215 "Fault" 16777214 "No_Data_Exists" ;
VAL_ 792 DsplyChkActv_B_Stat 1 "Active" 0 "Inactive" ;
VAL_ 789 VehElSurpStat_L_Dsply 8191 "Faulty" 8190 "Data_Not_Available" ;
VAL_ 789 TripSum_E_Dsply 511 "_Faulty" 510 "Data_Not_Available" ;
VAL_ 789 TripSum_L_Dsply 65535 "Faulty" 65534 "Data_Not_Available__" ;
VAL_ 126 StePw_B_Rq 1 "Yes" 0 "No" ;
VAL_ 126 StePinRelInit_An_Sns 65535 "Faulty" 65534 "NoDataExists" ;
VAL_ 126 StePinCompAnEst_D_Qf 3 "OK" 2 "Degraded" 1 "No_Data_Exists" 0 "Faulty" ;
VAL_ 806 ClimtCoolRear_B_Rq 1 "On" 0 "Off" ;
VAL_ 806 ClimtHeatRear_D_Rq 7 "NotUsed4" 6 "NotUsed3" 5 "HtrCoreClntFlwOnly" 4 "PtcHtrTestMde" 3 "Defrost_Defog" 2 "FastTempPullDownHeatingReq" 1 "OpportunisticHeatingReq" 0 "NoHeatingRequest" ;
VAL_ 806 SnowPlowMde_B_Enbl 1 "Enable" 0 "Disable" ;
VAL_ 806 ClimtDeltaLoad_Pw_Actl 63 "Faulty" 62 "NoDataExists" ;
VAL_ 806 StopStrtDrvMde_B_RqBtn 1 "Pressed" 0 "Not_Pressed" ;
VAL_ 806 WndwFrontHeat_B_Stat 1 "On" 0 "Off" ;
VAL_ 806 HtrCorePump_B_Rq 1 "On" 0 "Off" ;
VAL_ 806 ClimtHeat_D_Rq 7 "NotUsed4" 6 "NotUsed3" 5 "HtrCoreClntFlwOnly" 4 "PtcHtrTestMde" 3 "Defrost_Defog" 2 "FastTempPullDownHeatingReq" 1 "OpportunisticHeatingReq" 0 "NoHeatingRequest" ;
VAL_ 806 ClimtCool_D_Rq 7 "NotUsed4" 6 "NotUsed3" 5 "NotUsed2" 4 "ElACTestMde" 3 "Defrost_Defog" 2 "FastTempPullDownCoolReq" 1 "OpportunisticCoolingReq" 0 "NoCoolingRequest" ;
VAL_ 806 HvacEvap_Te_Actl 1023 "Fault" ;
VAL_ 806 HvacAirCond_B_Rq 1 "Yes" 0 "No" ;
VAL_ 806 ClimtPw_B_Rq 1 "Yes" 0 "No" ;
VAL_ 504 Mc_AudioSourceSel_Rq 4 "Reserved" 5 "SDcard" 3 "USB" 2 "BTAudio" 1 "CD" 0 "Inactive" ;
VAL_ 504 Mc_CutItem_Rq 3 "Inactive" 2 "ThreeQuarterFromBeginOneQ" 1 "End" 0 "Beginning" ;
VAL_ 410 MyKey_e911Override_St 2 "On" 1 "Off" 0 "No_Data_Exists" ;
VAL_ 410 DoNotDisturbOveride_St 2 "On" 1 "Off" 0 "No_Data_Exists" ;
VAL_ 1124 GPS_Vdop 31 "Invalid" 30 "Unknown" ;
VAL_ 1124 GPS_Speed 255 "Invalid" 254 "Unknown" ;
VAL_ 1124 GPS_Sat_num_in_view 31 "Invalid" 30 "Unknown" ;
VAL_ 1124 GPS_MSL_altitude 4095 "Fault" 4094 "Unknown" ;
VAL_ 1124 GPS_Heading 65535 "Fault" 65534 "Unknown" ;
VAL_ 1124 GPS_Hdop 31 "Invalid" 30 "Unknown" ;
VAL_ 1124 GPS_dimension 2 "_3D" 1 "_2D" 0 "No_Fix" ;
VAL_ 1123 GpsUtcYr_No_Actl 31 "Fault" ;
VAL_ 1123 GpsUtcMnth_No_Actl 15 "Fault" ;
VAL_ 1123 GPS_UTC_seconds 63 "Fault" 62 "Unknown" ;
VAL_ 1123 GPS_UTC_minutes 63 "Fault" 62 "Unknown" ;
VAL_ 1123 GPS_UTC_hours 31 "Invalid" 30 "Unknown" ;
VAL_ 1123 GPS_Pdop 31 "Invalid" 30 "Unknown" ;
VAL_ 1123 GPS_Compass_direction 7 "NorthWest" 6 "West" 5 "SouthWest" 4 "South" 3 "SouthEast" 2 "East" 1 "NorthEast" 0 "North" ;
VAL_ 1123 GPS_Actual_vs_Infer_pos 1 "Inferred_Position" 0 "Actual_Postition" ;
VAL_ 1123 Gps_B_Falt 1 "Yes" 0 "No" ;
VAL_ 1122 GpsHsphLongEast_D_Actl 0 "Invalid" 1 "Eastern" 2 "Western" 3 "Fault" ;
VAL_ 1122 GpsHsphLattSth_D_Actl 3 "Fault" 2 "Northern" 1 "Southern" 0 "Invalid" ;
VAL_ 1122 GPS_Longitude_Minutes 63 "Fault" 62 "Unknown" ;
VAL_ 1122 GPS_Longitude_Min_dec 16383 "Invalid" 16382 "Unknown" ;
VAL_ 1122 GPS_Longitude_Degrees 511 "Fault" 510 "Unknown" ;
VAL_ 1122 GPS_Latitude_Minutes 63 "Fault" 62 "Unknown" ;
VAL_ 1122 GPS_Latitude_Min_dec 16383 "Invalid" 16382 "Unknown" ;
VAL_ 1122 GPS_Latitude_Degrees 255 "Invalid" 254 "Unknown" ;
VAL_ 1050 CamraRearBttn_D_Stat 1 "Pressed" 0 "Not_Pressed" ;
VAL_ 1050 TrailCtlSwtch_B_Stat 1 "Pressed" 0 "Not_Pressed" ;
VAL_ 1050 CamraFrntBttn_D_Stat 1 "Pressed" 0 "Not_Pressed" ;
VAL_ 1050 AutoHoldSwtch_D_Stat 3 "Faulty" 2 "NotUsed" 1 "Pressed" 0 "Not_Pressed" ;
VAL_ 1050 EcoInhbt_B_RqHvac 1 "Yes" 0 "No" ;
VAL_ 1050 LpdbPtc3_B_Rq 1 "On" 0 "Off" ;
VAL_ 1050 LpdbPtc2_B_Rq 1 "On" 0 "Off" ;
VAL_ 1050 LpdbPtc1_B_Rq 1 "On" 0 "Off" ;
VAL_ 1050 LpdbHeatWiprPrk_B_Rq 1 "On" 0 "Off" ;
VAL_ 1050 LpdbDfrstRearOn_B_Rq 1 "On" 0 "Off" ;
VAL_ 1050 LpdbDfrstFrOn_B_Rq 1 "On" 0 "Off" ;
VAL_ 1050 LpdbDfrstFlOn_B_Rq 1 "On" 0 "Off" ;
VAL_ 1050 LpdbAuxBlwr_B_Rq 1 "On" 0 "Off" ;
VAL_ 1050 PrkAidSwtch_D_RqDrv 1 "Pressed" 0 "Not_Pressed" ;
VAL_ 1050 SteWhlHeat_D_Rq 15 "NotUsed6" 14 "NotUsed5" 13 "NotUsed4" 12 "NotUsed3" 11 "NotUsed2" 10 "NotUsed1" 9 "Reserved_3" 8 "Reserved_2" 7 "Reserved_1" 6 "Level_3_Heating" 5 "Level_3_Heating_LS" 4 "Level_2_Heating" 3 "Level_2_Heating_LS" 2 "Level_1_Heating" 1 "Level_1_Heating_LS" 0 "Off" ;
VAL_ 1050 MirrorHeatOn_B_Rq 1 "True" 0 "False" ;
VAL_ 1050 Remote_Start_QuietMode 1 "Quiet" 0 "Not_Quiet" ;
VAL_ 1050 DrvSlipCtlMde_B_Rq 1 "Pressed" 0 "Not_Pressed" ;
VAL_ 1050 Outside_Air_Temp_Stat 255 "Invalid" 254 "Unknown" ;
VAL_ 1106 TrlrSnsId_No_Actl -1 "Faulty_FFFFFFFFFFFF" -2 "NoDataExists_FFFFFFFFFFFE" ;
VAL_ 1086 AwdPtu_Te_Actl 255 "Faulty" ;
VAL_ 1086 FuelPumpPwr_B_Rq 1 "On" 0 "Off" ;
VAL_ 1086 ElLoadCtl_D_Rq 7 "Unused3" 6 "Unused2" 5 "Unused1" 4 "HoldAllDrvrInvisibleLoads" 3 "StdDriverInvisibleLoadsOn" 2 "AllDriverInvisibleLoadsOn" 1 "All_Possible_Loads_Off" 0 "No_Request" ;
VAL_ 817 ChildLckMde_B_Stat 1 "Enable" 0 "Disable" ;
VAL_ 817 VehLckInd_D_Rq 3 "NotUsed" 2 "On_Day" 1 "On_Night" 0 "Off" ;
VAL_ 817 DrTgateOpen_B_Rq 1 "Open" 0 "Null" ;
VAL_ 817 DrTgateExtSwMde_B_Stat 1 "Enable" 0 "Disable" ;
VAL_ 817 Remote_Device_Feedback 7 "Unused3" 6 "Unused2" 5 "Unused1" 4 "Shutdown" 3 "Running" 2 "Starting" 1 "Acknowledge" 0 "Null" ;
VAL_ 817 Veh_Lock_Requestor 31 "Walk_Away_Locking" 30 "Remote_Park_Assist" 29 "DoorsOffToOn_Smart_Unlock" 28 "Rgtm_Shutlock_Switch" 27 "Boundary_Alert" 26 "Transit_Vehicle_Relock" 25 "Transit_Cargo_Relock" 24 "Transit_Ajar_Lock" 23 "Diagnostics" 22 "Console_Lock" 21 "Child_Lock" 20 "Double_Lock" 19 "Passive_Pasenger" 18 "Passive_Driver" 17 "Slam_Lock_Protect" 16 "SYNC" 15 "Passport" 14 "Passive_Smart_Unlock" 13 "Autorelock" 12 "RemoteStart" 0 "Null" 1 "Autolock" 11 "Smart_Unlock" 10 "Sliding_Door" 9 "Passive" 8 "Remote" 7 "Programming" 6 "Powerslide" 5 "Keypad" 4 "Key_Cylinder" 3 "Interior" 2 "Auto_Unlock" ;
VAL_ 817 R_Pwr_Sliding_Dr_Rqst 1 "Active" 0 "Null" ;
VAL_ 817 Power_Liftgate_Rqst 1 "Active" 0 "Null" ;
VAL_ 817 Power_Decklid_Rqst 1 "Active" 0 "Null" ;
VAL_ 817 L_Pwr_Sliding_Dr_Rqst 1 "Active" 0 "Null" ;
VAL_ 817 Veh_Lock_Sub_Id 15 "Unused7" 14 "Unused6" 13 "Unused5" 12 "Unused4" 11 "Unused3" 10 "Unused2" 9 "Unused1" 8 "Customer_8" 7 "Customer_7" 6 "Customer_6" 5 "Customer_5" 4 "Customer_4" 3 "Customer_3" 2 "Customer_2" 1 "Customer_1" 0 "Null" ;
VAL_ 817 Veh_Lock_Status 3 "UNLOCK_DRV" 2 "UNLOCK_ALL" 1 "LOCK_ALL" 0 "LOCK_DBL" ;
VAL_ 817 ChildLck_D_Dsply 3 "NOT_SUPPORTED" 2 "ERROR" 1 "CHILD_UNLOCK" 0 "CHILD_LOCK" ;
VAL_ 817 WindowLockout_B_Stat 1 "Locked" 0 "Unlock" ;
VAL_ 817 Lockmsgtxt_D_Rq 7 "MSG7" 6 "MSG6" 5 "MSG5" 4 "MSG4" 3 "MSG3" 2 "MSG2" 1 "MSG1" 0 "NO_WARNING" ;
VAL_ 817 FobComm_D_Stat 3 "NotUsed" 2 "RemEngStartOK" 1 "RemEngStartFail" 0 "Null" ;
VAL_ 817 LockInhibit 1 "Inhibit" 0 "No_Inhibit" ;
VAL_ 611 AwdTerrMdeChng_D_Rdy 7 "Fault" 6 "Undefined_2" 5 "Undefined_1" 4 "ModeUnavailDrInputRqd" 3 "SpOpModes_NotSupported" 2 "ModeUnavailDynamicCond" 1 "Module_In_Initialization" 0 "Mode_Change_Available" ;
VAL_ 611 AwdTerrMde_D_Actl 7 "Fail_Safe_Default" 6 "Dynamic_Mode" 5 "Rock_Crawl_Mode" 4 "Mud_Ruts_Mode" 3 "Sand_Mode" 2 "Undefined" 1 "Low_Mu_Mode" 0 "Special_Operating_Mode_Off" ;
VAL_ 611 AwdSys_D_Stat 3 "Faulty" 2 "NotUsed" 1 "_4x4_L_H_Active" 0 "_4x4_L_H_Inactive" ;
VAL_ 611 AwdStat_D_RqDsply 31 "Rear_Diff_Lock_Not_Avail" 30 "_4wd_Lock_Required" 29 "Cfg_Perf_Redc_See_Manual" 28 "To_Engage_4x4_Release_Aped" 27 "To_Engage_4x4_Slow_To_3MPH" 26 "Shift_To_Neutral" 25 "Lkr_Mode_Unavail_TMS" 24 " _4x4_Mode_Unavail_TMS" 23 "Out_of_4Low_Crawl" 22 "AWD_PTU_Oil_Changed" 21 "Change_AWD_PTU_Oil" 20 "Neutral_Tow_Disabled" 19 "Neutral_Tow_Enabled" 18 "AWD_OFF" 17 "_4x4_Off_Road_Speed" 16 "_4x4_Extreme_Off_Road_Mode" 15 "_4x4_Exiting_Off_Road" 14 "_4x4_Off_Road_Mode" 10 "_4x4_Locked_Temporarily" 9 "Shift_In_Progress" 13 "Blocked_Shift_Assist" 12 "_4x4_Auto_Restored" 11 "_4x4_Disabled_Temporarily" 7 "Out_of_4Low__Neutral" 6 "Out_of_4Low__Brake" 5 "Out_of_4Low__Speed" 4 "Into_4Low__Clutch" 3 "Into_4Low__Neutral" 2 "Into_4Low__Brake" 1 "Into_4Low__Speed" 0 "Normal__No_Message" 8 "Out_of_4Low__Clutch" ;
VAL_ 611 AwdLck_D_Stat 9 "Undefined" 8 "Under_External_Torque_Ctrl" 7 "Torque_Limited_by_Cmd" 6 "Fully_Locked_by_Cmd" 5 "Disabled" 4 "Warning" 3 "Fault" 2 "Inactive" 1 "Completely_Opened_by_Cmd" 0 "OK" ;
VAL_ 611 AwdSrvcRqd_B_Rq 1 "On" 0 "Off" ;
VAL_ 611 AwdLck_Tq_Rq 4095 "Fault" 4094 "Unknown" ;
VAL_ 611 AwdOffRoadMode_D_Stats 3 "Invalid" 2 "Extreme_Off_Road" 1 "Off_Road" 0 "Normal_Mode" ;
VAL_ 611 AwdLoLamp_D_RqDsply 3 "Not_Used" 2 "Flash" 1 "On" 0 "Off" ;
VAL_ 611 AwdHiLamp_D_RqDsply 3 "Not_Used" 2 "Flash" 1 "On" 0 "Off" ;
VAL_ 611 AwdAutoLamp_D_RqDsply 3 "Not_Used" 2 "Flash" 1 "On" 0 "Off" ;
VAL_ 611 Awd2wdLamp_D_RqDsply 3 "Not_Used" 2 "Flash" 1 "On" 0 "Off" ;
VAL_ 611 AwdRnge_D_Actl 7 "Unknown" 6 "High_Range_2wd" 5 "High_Range_Auto" 4 "High_Range_Locked" 3 "Neutral" 2 "Low_Range_2wd" 1 "Low_Range_Auto" 0 "Low_Range_Locked" ;
VAL_ 611 NtrlTowAvail_B_Stat 1 "Available" 0 "NotAvailable" ;
VAL_ 611 AwdDrvMde_D_Stat 7 "Faulty" 6 "NotAvailable" 5 "RockCrawl" 4 "Baja" 3 "MudAndSand" 2 "Weather" 1 "Sport" 0 "Normal" ;
VAL_ 611 SelDrvMdeAwd_D_Stat 0 "NotAvailable" 1 "Available" 2 "TemporarilyNotAvailable" 3 "Faulty" ;
VAL_ 1114 TrailCtlSwtch_B_Stat2 1 "Pressed" 0 "Not_Pressed" ;
VAL_ 1114 TrlBrkInitOut_D_Rq 3 "Heavy" 2 "Medium" 1 "Light" 0 "Null" ;
VAL_ 968 RvltnMatchAllw_D_Rq 3 "RevolutionMatchDisabled" 2 "RevolutionMatchEnabled" 1 "ChangeWithDriveMode" 0 "NoSelection" ;
VAL_ 968 BrkDrvMde_D_Rq 7 "Faulty" 6 "RockCrawl" 5 "Baja" 4 "DragOrMudAndSand" 3 "Track" 2 "Snow_Wet" 1 "Sport" 0 "Normal" ;
VAL_ 968 LnchCtl_D_Rq 3 "NotUsed2" 2 "NotUsed1" 1 "LC_On" 0 "LC_Off" ;
VAL_ 968 CurrentColor_CmdGage 15 "NotUsed7" 14 "NotUsed6" 13 "NotUsed5" 12 "NotUsed4" 11 "NotUsed3" 10 "NotUsed2" 9 "NotUsed1" 8 "Null" 7 "Color7" 6 "Color6" 5 "Color5" 4 "Color4" 3 "Color3" 2 "Color2" 1 "Color1" 0 "Off" ;
VAL_ 968 BlendedColor_CmdGage 3 "NotUsed" 2 "Null" 1 "On" 0 "Off" ;
VAL_ 968 BlendColorRed_CmdGage 15 "NotUsed10" 14 "NotUsed9" 13 "NotUsed8" 12 "NotUsed7" 11 "NotUsed6" 10 "NotUsed5" 9 "NotUsed4" 8 "NotUsed3" 7 "NotUsed2" 6 "NotUsed1" 5 "_5" 4 "_4" 3 "_3" 2 "_2" 1 "_1" 0 "Null" ;
VAL_ 968 BlendColorGrn_CmdGage 15 "NotUsed10" 14 "NotUsed9" 13 "NotUsed8" 12 "NotUsed7" 11 "NotUsed6" 10 "NotUsed5" 9 "NotUsed4" 8 "NotUsed3" 7 "NotUsed2" 6 "NotUsed1" 5 "_5" 4 "_4" 3 "_3" 2 "_2" 1 "_1" 0 "Null" ;
VAL_ 968 BlendColorBlue_CmdGage 15 "NotUsed10" 14 "NotUsed9" 13 "NotUsed8" 12 "NotUsed7" 11 "NotUsed6" 10 "NotUsed5" 9 "NotUsed4" 8 "NotUsed3" 7 "NotUsed2" 6 "NotUsed1" 5 "_5" 4 "_4" 3 "_3" 2 "_2" 1 "_1" 0 "Null" ;
VAL_ 968 Dimming_Level_Cmd 3 "Low" 2 "Not_Used" 1 "High" 0 "Null" ;
VAL_ 968 Current_Color_Cmd 15 "NotUsed7" 14 "NotUsed6" 13 "NotUsed5" 12 "NotUsed4" 11 "NotUsed3" 10 "NotUsed2" 9 "NotUsed1" 8 "Null" 7 "Color7" 6 "Color6" 5 "Color5" 4 "Color4" 3 "Color3" 2 "Color2" 1 "Color1" 0 "Off" ;
VAL_ 968 BlendedColorRed_Cmd 15 "NotUsed10" 14 "NotUsed9" 13 "NotUsed8" 12 "NotUsed7" 11 "NotUsed6" 10 "NotUsed5" 9 "NotUsed4" 8 "NotUsed3" 7 "NotUsed2" 6 "NotUsed1" 5 "_5" 4 "_4" 3 "_3" 2 "_2" 1 "_1" 0 "Null" ;
VAL_ 968 BlendedColorGreen_Cmd 15 "NotUsed10" 14 "NotUsed9" 13 "NotUsed8" 12 "NotUsed7" 11 "NotUsed6" 10 "NotUsed5" 9 "NotUsed4" 8 "NotUsed3" 7 "NotUsed2" 6 "NotUsed1" 5 "_5" 4 "_4" 3 "_3" 2 "_2" 1 "_1" 0 "Null" ;
VAL_ 968 BlendedColorBlue_Cmd 15 "NotUsed10" 14 "NotUsed9" 13 "NotUsed8" 12 "NotUsed7" 11 "NotUsed6" 10 "NotUsed5" 9 "NotUsed4" 8 "NotUsed3" 7 "NotUsed2" 6 "NotUsed1" 5 "_5" 4 "_4" 3 "_3" 2 "_2" 1 "_1" 0 "Null" ;
VAL_ 968 BlendedColor_Cmd 3 "NotUsed" 2 "Null" 1 "On" 0 "Off" ;
VAL_ 968 SuspDrvMde_D_Rq 7 "Faulty" 6 "NotUsed2" 5 "NotUsed1" 4 "Drag" 3 "Track" 2 "Snow_Wet" 1 "Sport" 0 "Normal" ;
VAL_ 968 SlMde_D_Rq 3 "IsaNotConfigured" 2 "Manual_Mode" 1 "Auto_Mode" 0 "Null" ;
VAL_ 968 IsaOffst_D_Rq 15 "Faulty" 14 "Null" 13 "Thirteen" 12 "Twelve" 11 "Eleven" 10 "Ten" 9 "Nine" 8 "Eight" 7 "Seven" 6 "Six" 5 "Five" 4 "Four" 3 "Three" 2 "Two" 1 "One" 0 "Zero" ;
VAL_ 1006 PersIndexIpmb_D_Actl 7 "Unused_3" 6 "Unused_2" 5 "Unused_1" 4 "Vehicle" 3 "PERS_4" 2 "PERS_3" 1 "PERS_2" 0 "PERS_1" ;
VAL_ 129 AirbagDrv_B_RqDactv 1 "Request" 0 "NoRequest" ;
VAL_ 129 SelDrvMdeSwtch4_D_Stat4 3 "Faulty" 2 "Pressed" 1 "NotPressed" 0 "Null" ;
VAL_ 129 EngExhMdeQuiet_B_RqDrv2 1 "Pressed" 0 "Not_Pressed" ;
VAL_ 129 SteWhlSwtchHome_B_Stat 1 "Pressed" 0 "Not_Pressed" ;
VAL_ 129 SteWhlSwtchInfo_B_Stat 1 "Pressed" 0 "Not_Pressed" ;
VAL_ 129 SelDrvMdeSwtch3_D_Stat4 3 "Faulty" 2 "Pressed" 1 "NotPressed" 0 "Null" ;
VAL_ 129 SelDrvMdeSwtch2_D_Stat4 3 "Faulty" 2 "Pressed" 1 "NotPressed" 0 "Null" ;
VAL_ 129 SelDrvMdeSwtch1_D_Stat4 3 "Faulty" 2 "Pressed" 1 "NotPressed" 0 "Null" ;
VAL_ 129 PoliceAux4Swtch_B_Stat 1 "Switch_Active" 0 "Switch_Not_Active" ;
VAL_ 129 PoliceAux3Swtch_B_Stat 1 "Switch_Active" 0 "Switch_Not_Active" ;
VAL_ 129 PoliceAux2Swtch_B_Stat 1 "Switch_Active" 0 "Switch_Not_Active" ;
VAL_ 129 SteWhlSwtchView_B_Stat 1 "Pressed" 0 "Not_Pressed" ;
VAL_ 129 SteWhlSwtchSet_B_Stat 1 "Pressed" 0 "Not_Pressed" ;
VAL_ 129 SteWhlSwtchPhon_B_Stat 1 "Pressed" 0 "Not_Pressed" ;
VAL_ 129 SteWhlSwtchNav_B_Stat 1 "Pressed" 0 "Not_Pressed" ;
VAL_ 129 SteWhlSwtchMed_B_Stat 1 "Pressed" 0 "Not_Pressed" ;
VAL_ 129 SteWhlSwtchIod_B_Stat 1 "Pressed" 0 "Not_Pressed" ;
VAL_ 129 SteWhlSwtchHud_B_Stat 1 "Pressed" 0 "Not_Pressed" ;
VAL_ 129 SteWhlSwtchBack_B_Stat 1 "Pressed" 0 "Not_Pressed" ;
VAL_ 129 PoliceAux1Swtch_B_Stat 1 "Switch_Active" 0 "Switch_Not_Active" ;
VAL_ 129 SelDrvMdeSwtch_D_Stat4 3 "Faulty" 2 "SwitchState2" 1 "SwitchState1" 0 "NotPressed" ;
VAL_ 129 SteWhlSwtchMenu_B_Stat 1 "Pressed" 0 "Not_Pressed" ;
VAL_ 129 SteEffortInc_B_RqDrv 1 "Pressed" 0 "Not_Pressed" ;
VAL_ 129 SelDrvMdeInc_B_RqDrv 1 "Pressed" 0 "Not_Pressed" ;
VAL_ 129 SelDrvMdeDec_B_RqDrv 1 "Pressed" 0 "Not_Pressed" ;
VAL_ 129 SuspDampInc_B_RqDrv 1 "Pressed" 0 "Not_Pressed" ;
VAL_ 129 SteWhlSwtchUp_B_Stat 1 "Pressed" 0 "Not_Pressed" ;
VAL_ 129 SteWhlSwtchRght_B_Stat 1 "Pressed" 0 "Not_Pressed" ;
VAL_ 129 SteWhlSwtchOk_B_Stat 1 "Pressed" 0 "Not_Pressed" ;
VAL_ 129 SteWhlSwtchLeft_B_Stat 1 "Pressed" 0 "Not_Pressed" ;
VAL_ 129 SteWhlSwtchDown_B_Stat 1 "Pressed" 0 "Not_Pressed" ;
VAL_ 1244 Con_InfotainmentVer_St 1 "B299" 0 "invalid" ;
VAL_ 1243 Con_BTAud_InfotainmVer_St 1 "B299" 0 "invalid" ;
VAL_ 681 Con_DB1FilterConfig_St 31 "UnknownActive" 9 "Reserved" 8 "Podcast" 7 "Audiobook" 6 "Composer" 5 "Track" 4 "Genre" 3 "Album" 2 "Artist" 1 "Playlist" 0 "Root" ;
VAL_ 681 Con_DB1Filter3_St 1023 "All" 1022 "SIIndex_1022" 1 "SIIndex_1" 0 "NotEngaged" ;
VAL_ 681 Con_DB1Filter2_St 65535 "All" 65534 "SIIndex_65534" 1 "SIIndex_1" 0 "NotEngaged" ;
VAL_ 681 Con_DB1Filter1_St 65535 "All" 65534 "SIIndex_65534" 1 "SIIndex_1" 0 "NotEngaged" ;
VAL_ 639 OfbChrgPrflUpdate_B_Rq 1 "Request" 0 "NoRequest" ;
VAL_ 639 OfbChrgGoTUpdate_B_Rq 1 "Request" 0 "NoRequest" ;
VAL_ 639 OfbChrgClearAll_B_Rq 1 "Request" 0 "NoRequest" ;
VAL_ 639 OfbChrgGoTTouch_D_Rq 3 "NotUsed" 2 "On" 1 "Off" 0 "Null" ;
VAL_ 639 OfbChrgGoTPrcond_D_Rq 3 "High" 2 "Medium" 1 "Low" 0 "Off" ;
VAL_ 639 OfbChrgGoTOn_D_Rq 3 "NotUsed" 2 "On" 1 "Off" 0 "Null" ;
VAL_ 639 OfbChrgGoTMnte_D_Rq 15 "NotUsed_4" 14 "NotUsed_3" 13 "NotUsed_2" 12 "NotUsed_1" 11 "Minute_55" 10 "Minute_50" 9 "Minute_45" 8 "Minute_40" 7 "Minute_35" 6 "Minute_30" 5 "Minute_25" 4 "Minute_20" 3 "Minute_15" 2 "Minute_10" 1 "Minute_5" 0 "Minute_0" ;
VAL_ 639 OfbChrgGoTHr_T_Rq 31 "Faulty" 30 "NoDataExists" ;
VAL_ 639 OfbChrgGoTExtHtr_D_Rq 3 "NotUsed" 2 "On" 1 "Off" 0 "Null" ;
VAL_ 639 OfbChrgGoTDelete_B_Rq 1 "Request" 0 "NoRequest" ;
VAL_ 741 Con_USB_Playtype_St 2 "Playlist" 1 "Folder" 0 "Invalid" ;
VAL_ 741 Con_ShowSWDLprogress_St 5 "ConSWUpdateSuccess" 4 "ConSWUpdateNotNecessary" 3 "ConSWUpdateFailed" 2 "ConSWUpdateInProgress" 1 "ConSWUpdateNotRunning" 0 "Invalid" ;
VAL_ 741 Con_iPod_IntroScan_St 3 "OnTheFolderSelGroup" 2 "OnTheDevice" 1 "Off" 0 "Invalid" ;
VAL_ 741 Con_iPod_Shuffle_St 3 "OnTheFolderSelGroup" 2 "OnTheDevice" 1 "Off" 0 "Invalid" ;
VAL_ 741 Con_iPod_Repeat_St 7 "Reserved2" 6 "Reserved1" 5 "Reserved" 4 "RepeatOnDevice" 3 "RepeatOnFolder" 2 "RepeatOnTrack" 1 "Off" 0 "Invalid" ;
VAL_ 741 Con_USB_Repeat_St 7 "Reserved2" 6 "Reserved1" 5 "Reserved" 4 "RepeatOnDevice" 3 "RepeatOnFolder" 2 "RepeatOnTrack" 1 "Off" 0 "Invalid" ;
VAL_ 741 Con_USB_IntroScan_St 3 "OnTheFolderSelGroup" 2 "OnTheDevice" 1 "Off" 0 "Invalid" ;
VAL_ 741 Con_USB_Shuffle_St 3 "OnTheFolderSelGroup" 2 "OnTheDevice" 1 "Off" 0 "Invalid" ;
VAL_ 741 Con_iPod_Error_St 8 "NoDataInFolder" 7 "NoRespFromDevice" 6 "UnableToRead" 5 "NoDataOnDevice" 4 "FileSysNotSupported" 3 "DeviceNotSupported" 2 "InvalidFile" 1 "NoError" 0 "Invalid" ;
VAL_ 741 Con_USB_Error_St 9 "USBHubNotSupported" 8 "NoDataInFolder" 7 "NoRespFromDevice" 6 "UnableToRead" 5 "NoDataOnDevice" 4 "FileSysNotSupported" 3 "DeviceNotSupported" 2 "InvalidFile" 1 "NoError" 0 "Invalid" ;
VAL_ 741 Con_iPod_FunctStatus_St 7 "Reserved2" 6 "Reserved1" 5 "Reserved" 4 "Reading" 3 "Ready" 2 "Initilization" 1 "Free" 0 "Invalid" ;
VAL_ 741 Con_USB_FunctStatus_St 7 "Reserved2" 6 "Reserved1" 5 "Reserved" 4 "Reading" 3 "Ready" 2 "Initilization" 1 "Free" 0 "Invalid" ;
VAL_ 741 Con_USB_OpMode_St 7 "FastRewind20" 6 "FastRewind10" 5 "FastForward20" 4 "FastForward10" 3 "Pause" 2 "Play" 1 "Stop" 0 "Invalid" ;
VAL_ 741 Con_iPod_OpMode_St 7 "FastRewind20" 6 "FastRewind10" 5 "FastForward20" 4 "FastForward10" 3 "Pause" 2 "Play" 1 "Stop" 0 "Invalid" ;
VAL_ 954 ChildLckMaint_D_Stat 3 "NotUsed_1" 2 "Overruled" 1 "On" 0 "Off" ;
VAL_ 954 ExtLghtFront_D_RqBody 3 "NotUsed" 2 "On" 1 "Off" 0 "Null" ;
VAL_ 954 LoadShedRelay_B_Rq 1 "Active" 0 "Inactive" ;
VAL_ 954 LoadShedRelayMde_D_Stat 3 "NotUsed_1" 2 "EngRunRelay" 1 "SnowPlow" 0 "LoadShed" ;
VAL_ 954 KeylessIdl_B_Stat 1 "Pressed" 0 "Not_Pressed" ;
VAL_ 954 CargoLght_D_Stat 3 "NotUsed" 2 "Automatic" 1 "Manual" 0 "Null" ;
VAL_ 954 TlghtTestLght_D_Stat 7 "Error" 6 "AllOff" 5 "TestingReverseLights" 4 "TestingBrakeLights" 3 "TestingLeftTurnSignal" 2 "TestingRightTurnSignal" 1 "ParkingLightsIlluminated" 0 "Null" ;
VAL_ 954 TlghtTestPrecnd_D_Stat 7 "Error" 6 "NotStationary" 5 "InteractionPresent" 4 "PreconditionsPassed" 3 "BattSocLessThan75Percent" 2 "TailLightsOn" 1 "IgnitionNotOn" 0 "Null" ;
VAL_ 954 TlghtTest_D_Stat 3 "InProgress" 2 "Ended" 1 "Completed" 0 "Null" ;
VAL_ 954 LghtAmbDrvMde_B_Stat 1 "Automatic" 0 "Manual" ;
VAL_ 954 PwRnngBoardPoll_D_Stat 3 "NotUsed" 2 "PkPresent" 1 "PkNotPresent" 0 "NotPolling" ;
VAL_ 954 PosLghtFr_D_Stat 3 "Faulty" 2 "Outage" 1 "On" 0 "Off" ;
VAL_ 954 PosLghtFl_D_Stat 3 "Faulty" 2 "Outage" 1 "On" 0 "Off" ;
VAL_ 954 PoliceDmngLvl_D_Stat 7 "NotUsed" 6 "Off_Night" 5 "Off_Day" 4 "Low1Night" 3 "Low1Day" 2 "Inactive" 1 "Decommissioned" 0 "Null" ;
VAL_ 954 TrlrHitchLamp_D_Stat 1 "On" 0 "Off" ;
VAL_ 954 LicPlateLght_B_Stat 1 "On" 0 "Off" ;
VAL_ 954 TrukBedLght_B_Stat 1 "On" 0 "Off" ;
VAL_ 954 VehWlcmFrwlMde_D_Stat 7 "IlluminatedExit" 6 "CourtesyLightingDelayExt" 5 "CourtesyLightingExtended" 4 "CourtesyLightingDelayAll" 3 "CourtesyLightingAll" 2 "IlluminatedEntry" 1 "Approach" 0 "Null" ;
VAL_ 954 PudSptLghtRight_D_Rq 3 "NotUsed" 2 "On" 1 "Off" 0 "Null" ;
VAL_ 954 PudSptLghtLeft_D_Rq 3 "NotUsed" 2 "On" 1 "Off" 0 "Null" ;
VAL_ 954 ExtLghtRight_D_Stat 3 "NotUsed" 2 "On" 1 "Off" 0 "Null" ;
VAL_ 954 VehWlcmFrwl_D_Stat 3 "RunStart" 2 "Farewell" 1 "Welcome" 0 "Null" ;
VAL_ 954 ExtLghtRear_D_Stat 3 "NotUsed" 2 "On" 1 "Off" 0 "Null" ;
VAL_ 954 ExtLghtLeft_D_Stat 3 "NotUsed" 2 "On" 1 "Off" 0 "Null" ;
VAL_ 954 ExtLghtAlrt_B_Rq 1 "Yes" 0 "No" ;
VAL_ 954 ExtLght_D_Falt 3 "Error" 2 "NoStationary" 1 "StartEngine" 0 "Null" ;
VAL_ 954 ExtLghtFront_D_Stat 3 "NotUsed" 2 "On" 1 "Off" 0 "Null" ;
VAL_ 954 CrtsyLghtRear_D_Stat 3 "NotUsed_1" 2 "Automatic" 1 "Manual" 0 "Null" ;
VAL_ 125 VehRolComp_W_Actl 4094 "NoDataExists" 4095 "Fault" ;
VAL_ 125 VehVertComp_A_Actl 1022 "NoDataExists" 1023 "Fault" ;
VAL_ 125 BrkTot_Tq_RqArb 8191 "Fault" 8190 "Unknown" ;
VAL_ 125 BrkTot_Tq_Actl 8191 "Fault" 8190 "Unknown" ;
VAL_ 125 HsaStat_D_Actl 7 "Faulty" 6 "FaultyWithDriverIndication" 5 "SlowRelease" 4 "FastRelease" 3 "ActiveBrakePedalReleased" 2 "ActiveBrakePedalPressed" 1 "FindingGradient" 0 "Inactive" ;
